VERSION ""

NS_ :

BS_:

BU_: RadarFrontCenter RadarFrontSlave DASy MPC3 RadarFrontLeft RadarFrontRight RadarRearLeft RadarRearRight
VAL_TABLE_ RFC_Obj01_DetectionStatus 4 "Reserved" 3 "Prediction target" 2 "Tracking target" 1 "New detection target" 0 "Default value" ;
VAL_TABLE_ RFC_Obj00_DetectionStatus 4 "Reserved" 3 "Prediction target" 2 "Tracking target" 1 "New detection target" 0 "Default value" ;
VAL_TABLE_ RFC_Obj02_DetectionStatus 4 "Reserved" 3 "Prediction target" 2 "Tracking target" 1 "New detection target" 0 "Default value" ;
VAL_TABLE_ RFC_Obj03_DetectionStatus 4 "Reserved" 3 "Prediction target" 2 "Tracking target" 1 "New detection target" 0 "Default value" ;
VAL_TABLE_ RFC_Obj04_DetectionStatus 4 "Reserved" 3 "Prediction target" 2 "Tracking target" 1 "New detection target" 0 "Default value" ;
VAL_TABLE_ RFC_Obj05_DetectionStatus 4 "Reserved" 3 "Prediction target" 2 "Tracking target" 1 "New detection target" 0 "Default value" ;
VAL_TABLE_ RFC_Obj06_DetectionStatus 4 "Reserved" 3 "Prediction target" 2 "Tracking target" 1 "New detection target" 0 "Default value" ;
VAL_TABLE_ RFC_Obj07_DetectionStatus 4 "Reserved" 3 "Prediction target" 2 "Tracking target" 1 "New detection target" 0 "Default value" ;
VAL_TABLE_ RFC_Obj08_DetectionStatus 4 "Reserved" 3 "Prediction target" 2 "Tracking target" 1 "New detection target" 0 "Default value" ;
VAL_TABLE_ RFC_Obj09_DetectionStatus 4 "Reserved" 3 "Prediction target" 2 "Tracking target" 1 "New detection target" 0 "Default value" ;
VAL_TABLE_ RFC_Obj10_DetectionStatus 4 "Reserved" 3 "Prediction target" 2 "Tracking target" 1 "New detection target" 0 "Default value" ;
VAL_TABLE_ RFC_Obj11_DetectionStatus 4 "Reserved" 3 "Prediction target" 2 "Tracking target" 1 "New detection target" 0 "Default value" ;
VAL_TABLE_ RFC_Obj12_DetectionStatus 4 "Reserved" 3 "Prediction target" 2 "Tracking target" 1 "New detection target" 0 "Default value" ;
VAL_TABLE_ RFC_Obj13_DetectionStatus 4 "Reserved" 3 "Prediction target" 2 "Tracking target" 1 "New detection target" 0 "Default value" ;
VAL_TABLE_ RFC_Obj14_DetectionStatus 4 "Reserved" 3 "Prediction target" 2 "Tracking target" 1 "New detection target" 0 "Default value" ;
VAL_TABLE_ RFC_Obj15_DetectionStatus 4 "Reserved" 3 "Prediction target" 2 "Tracking target" 1 "New detection target" 0 "Default value" ;
VAL_TABLE_ RFC_Obj16_DetectionStatus 4 "Reserved" 3 "Prediction target" 2 "Tracking target" 1 "New detection target" 0 "Default value" ;
VAL_TABLE_ RFC_Obj17_DetectionStatus 4 "Reserved" 3 "Prediction target" 2 "Tracking target" 1 "New detection target" 0 "Default value" ;
VAL_TABLE_ RFC_Obj18_DetectionStatus 4 "Reserved" 3 "Prediction target" 2 "Tracking target" 1 "New detection target" 0 "Default value" ;
VAL_TABLE_ RFC_Obj19_DetectionStatus 4 "Reserved" 3 "Prediction target" 2 "Tracking target" 1 "New detection target" 0 "Default value" ;
VAL_TABLE_ RFC_Obj20_DetectionStatus 4 "Reserved" 3 "Prediction target" 2 "Tracking target" 1 "New detection target" 0 "Default value" ;
VAL_TABLE_ RFC_Obj21_DetectionStatus 4 "Reserved" 3 "Prediction target" 2 "Tracking target" 1 "New detection target" 0 "Default value" ;
VAL_TABLE_ RFC_Obj22_DetectionStatus 4 "Reserved" 3 "Prediction target" 2 "Tracking target" 1 "New detection target" 0 "Default value" ;
VAL_TABLE_ RFC_Obj23_DetectionStatus 4 "Reserved" 3 "Prediction target" 2 "Tracking target" 1 "New detection target" 0 "Default value" ;
VAL_TABLE_ RFC_Obj24_DetectionStatus 4 "Reserved" 3 "Prediction target" 2 "Tracking target" 1 "New detection target" 0 "Default value" ;
VAL_TABLE_ RFC_Obj25_DetectionStatus 4 "Reserved" 3 "Prediction target" 2 "Tracking target" 1 "New detection target" 0 "Default value" ;
VAL_TABLE_ RFC_Obj26_DetectionStatus 4 "Reserved" 3 "Prediction target" 2 "Tracking target" 1 "New detection target" 0 "Default value" ;
VAL_TABLE_ RFC_Obj27_DetectionStatus 4 "Reserved" 3 "Prediction target" 2 "Tracking target" 1 "New detection target" 0 "Default value" ;
VAL_TABLE_ RFC_Obj28_DetectionStatus 4 "Reserved" 3 "Prediction target" 2 "Tracking target" 1 "New detection target" 0 "Default value" ;
VAL_TABLE_ RFC_Obj29_DetectionStatus 4 "Reserved" 3 "Prediction target" 2 "Tracking target" 1 "New detection target" 0 "Default value" ;
VAL_TABLE_ RFC_Obj30_DetectionStatus 4 "Reserved" 3 "Prediction target" 2 "Tracking target" 1 "New detection target" 0 "Default value" ;
VAL_TABLE_ RFC_Obj31_DetectionStatus 4 "Reserved" 3 "Prediction target" 2 "Tracking target" 1 "New detection target" 0 "Default value" ;

BO_ 3221225472 VECTOR__INDEPENDENT_SIG_MSG: 0 Vector__XXX
 SG_ VFC_Left_Confidence : 0|7@1+ (0.01,0) [0|1] "" Vector__XXX
 SG_ VFC_Left_DxEnd : 0|9@1+ (0.5,0) [0|255.5] "m" Vector__XXX
 SG_ VFC_Left_Dy : 0|12@1+ (0.0078125,-16) [-16|15.9921875] "m" Vector__XXX
 SG_ VFC_Left_Curv : 0|12@1+ (3.0517578125E-005,-0.0625) [-0.0625|0.062469482421875] "1/m" Vector__XXX
 SG_ VFC_Left_CurvChange : 0|12@1+ (7.62939453125E-006,-0.015625) [-0.015625|0.0156173706054688] "1/m^2" Vector__XXX
 SG_ VFC_Left_HeadingAngle : 0|12@1+ (0.00048828125,-1) [-1|0.99951171875] "rad" Vector__XXX
 SG_ VFC_Left_Type : 0|5@1+ (1,0) [0|19] "" Vector__XXX
 SG_ VFC_Left_ID : 0|8@1+ (1,0) [0|255] "" Vector__XXX
 SG_ VFC_Right_Confidence : 0|7@1+ (0.01,0) [0|1] "" Vector__XXX
 SG_ VFC_Right_DxEnd : 0|9@1+ (0.5,0) [0|255.5] "m" Vector__XXX
 SG_ VFC_Right_Dy : 0|12@1+ (0.0078125,-16) [-16|15.9921875] "m" Vector__XXX
 SG_ VFC_Right_Curv : 0|12@1+ (3.0517578125E-005,-0.0625) [-0.0625|0.062469482421875] "1/m" Vector__XXX
 SG_ VFC_Right_CurvChange : 0|12@1+ (7.62939453125E-006,-0.015625) [-0.015625|0.0156173706054688] "1/m^2" Vector__XXX
 SG_ VFC_Right_HeadingAngle : 0|12@1+ (0.00048828125,-1) [-1|0.99951171875] "rad" Vector__XXX
 SG_ VFC_Right_Type : 0|5@1+ (1,0) [0|19] "" Vector__XXX
 SG_ VFC_Right_ID : 0|8@1+ (1,0) [0|255] "" Vector__XXX
 SG_ VFC_LeftLe_Confidence : 0|7@1+ (0.01,0) [0|1] "" Vector__XXX
 SG_ VFC_LeftLe_DxEnd : 0|9@1+ (0.5,0) [0|255.5] "m" Vector__XXX
 SG_ VFC_LeftLe_Dy : 0|12@1+ (0.0078125,-16) [-16|15.9921875] "m" Vector__XXX
 SG_ VFC_LeftLe_Curv : 0|12@1+ (3.0517578125E-005,-0.0625) [-0.0625|0.062469482421875] "1/m" Vector__XXX
 SG_ VFC_LeftLe_CurvChange : 0|12@1+ (7.62939453125E-006,-0.015625) [-0.015625|0.0156173706054688] "1/m^2" Vector__XXX
 SG_ VFC_LeftLe_HeadingAngle : 0|12@1+ (0.00048828125,-1) [-1|0.99951171875] "rad" Vector__XXX
 SG_ VFC_LeftLe_Type : 0|5@1+ (1,0) [0|19] "" Vector__XXX
 SG_ VFC_LeftLe_ID : 0|8@1+ (1,0) [0|255] "" Vector__XXX
 SG_ VFC_RightRi_Confidence : 0|7@1+ (0.01,0) [0|1] "" Vector__XXX
 SG_ VFC_RightRi_DxEnd : 0|9@1+ (0.5,0) [0|255.5] "m" Vector__XXX
 SG_ VFC_RightRi_Dy : 0|12@1+ (0.0078125,-16) [-16|15.9921875] "m" Vector__XXX
 SG_ VFC_RightRi_Curv : 0|12@1+ (3.0517578125E-005,-0.0625) [-0.0625|0.062469482421875] "1/m" Vector__XXX
 SG_ VFC_RightRi_CurvChange : 0|12@1+ (7.62939453125E-006,-0.015625) [-0.015625|0.0156173706054688] "1/m^2" Vector__XXX
 SG_ VFC_RightRi_HeadingAngle : 0|12@1+ (0.00048828125,-1) [-1|0.99951171875] "rad" Vector__XXX
 SG_ VFC_RightRi_Type : 0|5@1+ (1,0) [0|19] "" Vector__XXX
 SG_ VFC_RightRi_ID : 0|8@1+ (1,0) [0|255] "" Vector__XXX
 SG_ RFC_ACC_TGU_Hdr_CRC : 0|8@1+ (1,0) [0|255] "" Vector__XXX
 SG_ RFC_ACC_TGU_Hdr_MsgCtr : 0|4@1+ (1,0) [0|15] "" Vector__XXX
 SG_ RFC_ACC_TGU_Hdr_TimeStampStatus : 0|8@1+ (1,0) [0|255] "" Vector__XXX
 SG_ RFC_ACC_TGU_Hdr_TimeStamp : 0|42@1+ (1,0) [0|4398046511103] "ms" Vector__XXX
 SG_ RFC_ACC_TGU_Hdr_SensorState : 0|4@1+ (1,0) [0|15] "" Vector__XXX
 SG_ RFC_ACCObjInfo1_CRC : 0|8@1+ (1,0) [0|255] "" Vector__XXX
 SG_ RFC_ACCObjInfo1_MsgCtr : 0|4@1+ (1,0) [0|15] "" Vector__XXX
 SG_ RFC_ACCObjInfo1_ID : 0|8@1+ (1,0) [0|255] "" Vector__XXX
 SG_ RFC_ACCObjInfo1_Dx : 0|13@1+ (0.0625,-255.9375) [-255.9375|255.9375] "m" Vector__XXX
 SG_ RFC_ACCObjInfo1_Vx : 0|11@1+ (0.125,-128) [-128|127.875] "mps" Vector__XXX
 SG_ RFC_ACCObjInfo1_Ax : 0|10@1+ (0.125,-44.5) [-44.5|44.5] "mps2" Vector__XXX
 SG_ RFC_ACCObjInfo1_Dy : 0|13@1+ (0.0625,-255.9375) [-255.9375|255.9375] "m" Vector__XXX
 SG_ RFC_ACCObjInfo1_Vy : 0|11@1+ (0.125,-128) [-128|127.875] "mps" Vector__XXX
 SG_ RFC_ACCObjInfo1_Ay : 0|10@1+ (0.125,-44.5) [-44.5|44.5] "mps2" Vector__XXX
 SG_ RFC_ACCObjInfo1_DxStd : 0|8@1+ (0.05,0) [0|12.75] "m" Vector__XXX
 SG_ RFC_ACCObjInfo1_VxStd : 0|6@1+ (0.2,0) [0|12.6] "mps" Vector__XXX
 SG_ RFC_ACCObjInfo1_AxStd : 0|5@1+ (0.35,0) [0|10.85] "mps2" Vector__XXX
 SG_ RFC_ACCObjInfo1_DyStd : 0|8@1+ (0.1,0) [0|25.5] "m" Vector__XXX
 SG_ RFC_ACCObjInfo1_VyStd : 0|6@1+ (0.2,0) [0|12.6] "mps" Vector__XXX
 SG_ RFC_ACCObjInfo1_AyStd : 0|5@1+ (0.35,0) [0|10.85] "mps2" Vector__XXX
 SG_ RFC_ACCObjInfo1_ValidFlag : 0|1@1+ (1,0) [0|1] "" Vector__XXX
 SG_ RFC_ACCObjInfo1_UpdateFlag : 0|1@1+ (1,0) [0|1] "" Vector__XXX
 SG_ RFC_ACCObjInfo1_MirProb : 0|7@1+ (1,0) [0|100] "percent" Vector__XXX
 SG_ RFC_ACCObjInfo1_ObsProb : 0|7@1+ (1,0) [0|100] "percent" Vector__XXX
 SG_ RFC_ACCObjInfo1_ExistProb : 0|7@1+ (1,0) [0|100] "percent" Vector__XXX
 SG_ RFC_ACCObjInfo1_Type : 0|4@1+ (1,0) [0|15] "" Vector__XXX
 SG_ RFC_ACCObjInfo1_EDynProp : 0|4@1+ (1,0) [0|15] "" Vector__XXX
 SG_ RFC_ACCObjInfo1_UiLifeCycles : 0|7@1+ (1,0) [0|127] "" Vector__XXX
 SG_ RFC_ACCObjInfo1_RCS : 0|11@1+ (0.1,-100) [-100|100] "dBm" Vector__XXX
 SG_ RFC_ACCObjInfo1_RFF : 0|8@1+ (1,0) [0|255] "" Vector__XXX
 SG_ RFC_ACCObjInfo1_Width : 0|16@1- (0.0078125,0) [-256|255.9921875] "" Vector__XXX
 SG_ RFC_OnGoingObj3_CRC : 0|8@1+ (1,0) [0|255] "" Vector__XXX
 SG_ RFC_OnGoingObj3_MsgCtr : 0|4@1+ (1,0) [0|15] "" Vector__XXX
 SG_ RFC_OnGoingObj3_ID : 0|8@1+ (1,0) [0|255] "" Vector__XXX
 SG_ RFC_OnGoingObj3_Dx : 0|13@1+ (0.0625,-255.9375) [-255.9375|255.9375] "m" Vector__XXX
 SG_ RFC_OnGoingObj3_Vx : 0|11@1+ (0.125,-128) [-128|127.875] "mps" Vector__XXX
 SG_ RFC_OnGoingObj3_Ax : 0|10@1+ (0.125,-44.5) [-44.5|44.5] "mps2" Vector__XXX
 SG_ RFC_OnGoingObj3_Dy : 0|13@1+ (0.0625,-255.9375) [-255.9375|255.9375] "m" Vector__XXX
 SG_ RFC_OnGoingObj3_Vy : 0|11@1+ (0.125,-128) [-128|127.875] "mps" Vector__XXX
 SG_ RFC_OnGoingObj3_Ay : 0|10@1+ (0.125,-44.5) [-44.5|44.5] "mps2" Vector__XXX
 SG_ RFC_OnGoingObj3_DxStd : 0|8@1+ (0.05,0) [0|12.75] "m" Vector__XXX
 SG_ RFC_OnGoingObj3_VxStd : 0|6@1+ (0.2,0) [0|12.6] "mps" Vector__XXX
 SG_ RFC_OnGoingObj3_AxStd : 0|5@1+ (0.35,0) [0|10.85] "mps2" Vector__XXX
 SG_ RFC_OnGoingObj3_DyStd : 0|8@1+ (0.1,0) [0|25.5] "m" Vector__XXX
 SG_ RFC_OnGoingObj3_VyStd : 0|6@1+ (0.2,0) [0|12.6] "mps" Vector__XXX
 SG_ RFC_OnGoingObj3_AyStd : 0|5@1+ (0.35,0) [0|10.85] "mps2" Vector__XXX
 SG_ RFC_OnGoingObj3_ValidFlag : 0|1@1+ (1,0) [0|1] "" Vector__XXX
 SG_ RFC_OnGoingObj3_UpdateFlag : 0|1@1+ (1,0) [0|1] "" Vector__XXX
 SG_ RFC_OnGoingObj3_MirProb : 0|7@1+ (1,0) [0|100] "percent" Vector__XXX
 SG_ RFC_OnGoingObj3_ObsProb : 0|7@1+ (1,0) [0|100] "percent" Vector__XXX
 SG_ RFC_OnGoingObj3_ExistProb : 0|7@1+ (1,0) [0|100] "percent" Vector__XXX
 SG_ RFC_OnGoingObj3_Type : 0|4@1+ (1,0) [0|15] "" Vector__XXX
 SG_ RFC_OnGoingObj3_EDynProp : 0|4@1+ (1,0) [0|15] "" Vector__XXX
 SG_ RFC_OnGoingObj3_UiLifeCycles : 0|7@1+ (1,0) [0|127] "" Vector__XXX
 SG_ RFC_OnGoingObj3_RCS : 0|11@1+ (0.1,-100) [-100|100] "dBm" Vector__XXX
 SG_ RFC_OnGoingObj3_RFF : 0|8@1+ (1,0) [0|255] "" Vector__XXX
 SG_ RFC_OnGoingObj3_Width : 0|16@1- (0.0078125,0) [-256|255.9921875] "" Vector__XXX
 SG_ RFC_OnGoingObj2_CRC : 0|8@1+ (1,0) [0|255] "" Vector__XXX
 SG_ RFC_OnGoingObj2_MsgCtr : 0|4@1+ (1,0) [0|15] "" Vector__XXX
 SG_ RFC_OnGoingObj2_ID : 0|8@1+ (1,0) [0|255] "" Vector__XXX
 SG_ RFC_OnGoingObj2_Dx : 0|13@1+ (0.0625,-255.9375) [-255.9375|255.9375] "m" Vector__XXX
 SG_ RFC_OnGoingObj2_Vx : 0|11@1+ (0.125,-128) [-128|127.875] "mps" Vector__XXX
 SG_ RFC_OnGoingObj2_Ax : 0|10@1+ (0.125,-44.5) [-44.5|44.5] "mps2" Vector__XXX
 SG_ RFC_OnGoingObj2_Dy : 0|13@1+ (0.0625,-255.9375) [-255.9375|255.9375] "m" Vector__XXX
 SG_ RFC_OnGoingObj2_Vy : 0|11@1+ (0.125,-128) [-128|127.875] "mps" Vector__XXX
 SG_ RFC_OnGoingObj2_Ay : 0|10@1+ (0.125,-44.5) [-44.5|44.5] "mps2" Vector__XXX
 SG_ RFC_OnGoingObj2_DxStd : 0|8@1+ (0.05,0) [0|12.75] "m" Vector__XXX
 SG_ RFC_OnGoingObj2_VxStd : 0|6@1+ (0.2,0) [0|12.6] "mps" Vector__XXX
 SG_ RFC_OnGoingObj2_AxStd : 0|5@1+ (0.35,0) [0|10.85] "mps2" Vector__XXX
 SG_ RFC_OnGoingObj2_DyStd : 0|8@1+ (0.1,0) [0|25.5] "m" Vector__XXX
 SG_ RFC_OnGoingObj2_VyStd : 0|6@1+ (0.2,0) [0|12.6] "mps" Vector__XXX
 SG_ RFC_OnGoingObj2_AyStd : 0|5@1+ (0.35,0) [0|10.85] "mps2" Vector__XXX
 SG_ RFC_OnGoingObj2_ValidFlag : 0|1@1+ (1,0) [0|1] "" Vector__XXX
 SG_ RFC_OnGoingObj2_UpdateFlag : 0|1@1+ (1,0) [0|1] "" Vector__XXX
 SG_ RFC_OnGoingObj2_MirProb : 0|7@1+ (1,0) [0|100] "percent" Vector__XXX
 SG_ RFC_OnGoingObj2_ObsProb : 0|7@1+ (1,0) [0|100] "percent" Vector__XXX
 SG_ RFC_OnGoingObj2_ExistProb : 0|7@1+ (1,0) [0|100] "percent" Vector__XXX
 SG_ RFC_OnGoingObj2_Type : 0|4@1+ (1,0) [0|15] "" Vector__XXX
 SG_ RFC_OnGoingObj2_EDynProp : 0|4@1+ (1,0) [0|15] "" Vector__XXX
 SG_ RFC_OnGoingObj2_UiLifeCycles : 0|7@1+ (1,0) [0|127] "" Vector__XXX
 SG_ RFC_OnGoingObj2_RCS : 0|11@1+ (0.1,-100) [-100|100] "dBm" Vector__XXX
 SG_ RFC_OnGoingObj2_RFF : 0|8@1+ (1,0) [0|255] "" Vector__XXX
 SG_ RFC_OnGoingObj2_Width : 0|16@1- (0.0078125,0) [-256|255.9921875] "" Vector__XXX
 SG_ RRR_ObjHdr_CRC : 0|16@1+ (1,0) [0|65535] "" Vector__XXX
 SG_ RRR_ObjHdr_AliveCtr : 0|8@1+ (1,0) [0|255] "" Vector__XXX
 SG_ RRR_ObjHdr_ProtBlockCtr : 0|4@1+ (1,0) [0|15] "" Vector__XXX
 SG_ RRR_ObjHdr_TimeLatency : 0|16@1+ (1,0) [0|65535] "ms" Vector__XXX
 SG_ RRR_ObjHdr_TimeStampStatus : 0|8@1+ (1,0) [0|255] "" Vector__XXX
 SG_ RRR_ObjHdr_TimeStamp : 0|26@1+ (1,0) [0|67108863] "ms" Vector__XXX
 SG_ RRL_ObjHdr_CRC : 0|16@1+ (1,0) [0|65535] "" Vector__XXX
 SG_ RRL_ObjHdr_AliveCtr : 0|8@1+ (1,0) [0|255] "" Vector__XXX
 SG_ RRL_ObjHdr_ProtBlockCtr : 0|4@1+ (1,0) [0|15] "" Vector__XXX
 SG_ RRL_ObjHdr_TimeLatency : 0|16@1+ (1,0) [0|65535] "ms" Vector__XXX
 SG_ RRL_ObjHdr_TimeStampStatus : 0|8@1+ (1,0) [0|255] "" Vector__XXX
 SG_ RRL_ObjHdr_TimeStamp : 0|26@1+ (1,0) [0|67108863] "ms" Vector__XXX
 SG_ RFR_ObjHdr_CRC : 0|16@1+ (1,0) [0|65535] "" Vector__XXX
 SG_ RFR_ObjHdr_AliveCtr : 0|8@1+ (1,0) [0|255] "" Vector__XXX
 SG_ RFR_ObjHdr_ProtBlockCtr : 0|4@1+ (1,0) [0|15] "" Vector__XXX
 SG_ RFR_ObjHdr_TimeLatency : 0|16@1+ (1,0) [0|65535] "ms" Vector__XXX
 SG_ RFR_ObjHdr_TimeStampStatus : 0|8@1+ (1,0) [0|255] "" Vector__XXX
 SG_ RFR_ObjHdr_TimeStamp : 0|26@1+ (1,0) [0|67108863] "ms" Vector__XXX
 SG_ RFL_ObjHdr_CRC : 0|16@1+ (1,0) [0|65535] "" Vector__XXX
 SG_ RFL_ObjHdr_AliveCtr : 0|8@1+ (1,0) [0|255] "" Vector__XXX
 SG_ RFL_ObjHdr_ProtBlockCtr : 0|4@1+ (1,0) [0|15] "" Vector__XXX
 SG_ RFL_ObjHdr_TimeLatency : 0|16@1+ (1,0) [0|65535] "ms" Vector__XXX
 SG_ RFL_ObjHdr_TimeStampStatus : 0|8@1+ (1,0) [0|255] "" Vector__XXX
 SG_ RFL_ObjHdr_TimeStamp : 0|26@1+ (1,0) [0|67108863] "ms" Vector__XXX
 SG_ VFC_SafeSearch_ALC_CRC : 0|8@1+ (1,0) [0|255] "" Vector__XXX
 SG_ VFC_SafeSearch_ALC_MsgCtr : 0|4@1+ (1,0) [0|15] "" Vector__XXX
 SG_ VFC_ALCSt : 0|3@1+ (1,0) [0|7] "" Vector__XXX
 SG_ VFC_LaneChangeDirection : 0|2@1+ (1,0) [0|3] "" Vector__XXX
 SG_ VFC_SafeSearchCondition : 0|1@1+ (1,0) [0|1] "" Vector__XXX
 SG_ VFC_JumpTargetLane : 0|1@1+ (1,0) [0|1] "" Vector__XXX
 SG_ RFC_Evaluator_ALC_CRC : 0|8@1+ (1,0) [0|255] "" Vector__XXX
 SG_ RFC_Evaluator_ALC_MsgCtr : 0|4@1+ (1,0) [0|15] "" Vector__XXX
 SG_ LaneChangeLeft_collision_prob : 0|7@1+ (0.01,0) [0|1] "" Vector__XXX
 SG_ LaneChangeLeft_recommendation : 0|1@1+ (1,0) [0|1] "" Vector__XXX
 SG_ LaneChangeRight_collision_prob : 0|7@1+ (0.01,0) [0|1] "" Vector__XXX
 SG_ LaneChangeRight_recommendation : 0|1@1+ (1,0) [0|1] "" Vector__XXX
 SG_ CRObj_LeftObjLostAtCloseRange : 0|1@1+ (1,0) [0|1] "" Vector__XXX
 SG_ CRObj_RightObjLostAtCloseRange : 0|1@1+ (1,0) [0|1] "" Vector__XXX
 SG_ CRObj_evaluator_axd_valid : 0|1@1+ (1,0) [0|1] "" Vector__XXX
 SG_ CRObj_evaluator_axc_valid : 0|1@1+ (1,0) [0|1] "" Vector__XXX
 SG_ FLObj_evaluator_feasibility : 0|7@1+ (0.01,0) [0|1] "" Vector__XXX
 SG_ FRObj_evaluator_feasibility : 0|7@1+ (0.01,0) [0|1] "" Vector__XXX
 SG_ RLObj_evaluator_feasibility : 0|7@1+ (0.01,0) [0|1] "" Vector__XXX
 SG_ RRObj_evaluator_feasibility : 0|7@1+ (0.01,0) [0|1] "" Vector__XXX
 SG_ RFC_ALC_CR_invalid : 0|1@1+ (1,0) [0|1] "" Vector__XXX
 SG_ RFL_Status_CRC : 0|8@1+ (1,0) [0|255] "" Vector__XXX
 SG_ RFL_Status_MsgCtr : 0|4@1+ (1,0) [0|15] "" Vector__XXX
 SG_ RFL_Modulation_Status : 0|2@1+ (1,0) [0|3] "" Vector__XXX
 SG_ RFL_Status_SensorState : 0|4@1+ (1,0) [0|15] "" Vector__XXX
 SG_ RFR_Status_CRC : 0|8@1+ (1,0) [0|255] "" Vector__XXX
 SG_ RFR_Status_MsgCtr : 0|4@1+ (1,0) [0|15] "" Vector__XXX
 SG_ RFR_Modulation_Status : 0|2@1+ (1,0) [0|3] "" Vector__XXX
 SG_ RFR_Status_SensorState : 0|4@1+ (1,0) [0|15] "" Vector__XXX
 SG_ RRL_Status_CRC : 0|8@1+ (1,0) [0|255] "" Vector__XXX
 SG_ RRL_Status_MsgCtr : 0|4@1+ (1,0) [0|15] "" Vector__XXX
 SG_ RRL_Status_SensorState : 0|4@1+ (1,0) [0|15] "" Vector__XXX
 SG_ RRL_Modulation_Status : 0|2@1+ (1,0) [0|3] "" Vector__XXX
 SG_ RRR_Status_CRC : 0|8@1+ (1,0) [0|255] "" Vector__XXX
 SG_ RRR_Status_MsgCtr : 0|4@1+ (1,0) [0|15] "" Vector__XXX
 SG_ RRR_Status_SensorState : 0|4@1+ (1,0) [0|15] "" Vector__XXX
 SG_ RRR_Modulation_Status : 0|2@1+ (1,0) [0|3] "" Vector__XXX
 SG_ RFL_Obj00_01_CRC : 0|16@1+ (1,0) [0|65535] "" Vector__XXX
 SG_ RFL_Obj00_01_AliveCtr : 0|8@1+ (1,0) [0|255] "" Vector__XXX
 SG_ RFL_Obj00_01_ProtBlockCtr : 0|4@1+ (1,0) [0|15] "" Vector__XXX
 SG_ RFL_Obj00_RefPosIndex : 0|4@1+ (1,0) [0|15] "" Vector__XXX
 SG_ RFL_Obj00_Dx : 0|13@1+ (0.0625,-256) [-256|255.9375] "m" Vector__XXX
 SG_ RFL_Obj00_Dy : 0|11@1+ (0.125,-128) [-128|127.875] "m" Vector__XXX
 SG_ RFL_Obj00_DxVnce : 0|12@1+ (0.01,0) [0|30] "m^2" Vector__XXX
 SG_ RFL_Obj00_DyVnce : 0|12@1+ (0.01,0) [0|30] "m^2" Vector__XXX
 SG_ RFL_Obj00_Vx : 0|12@1+ (0.0625,-128) [-128|127.9375] "m/s" Vector__XXX
 SG_ RFL_Obj00_WidthVnce : 0|12@1+ (0.01,0) [0|30] "m^2" Vector__XXX
 SG_ RFL_Obj00_Width : 0|7@1+ (0.125,0) [0|15.875] "m" Vector__XXX
 SG_ RFL_Obj00_Valid : 0|1@1+ (1,0) [0|1] "" Vector__XXX
 SG_ RFL_Obj00_ID : 0|7@1+ (1,0) [0|127] "" Vector__XXX
 SG_ RFL_Obj00_Length : 0|7@1+ (0.125,0) [0|15.875] "m" Vector__XXX
 SG_ RFL_Obj00_MovingObserved : 0|6@1+ (2,0) [0|100] "%" Vector__XXX
 SG_ RFL_Obj00_MovingProbability : 0|6@1+ (2,0) [0|100] "%" Vector__XXX
 SG_ RFL_Obj01_RefPosIndex : 0|4@1+ (1,0) [0|15] "" Vector__XXX
 SG_ RFL_Obj01_Dx : 0|13@1+ (0.0625,-256) [-256|255.9375] "m" Vector__XXX
 SG_ RFL_Obj01_Dy : 0|11@1+ (0.125,-128) [-128|127.875] "m" Vector__XXX
 SG_ RFL_Obj01_DxVnce : 0|12@1+ (0.01,0) [0|30] "m^2" Vector__XXX
 SG_ RFL_Obj01_DyVnce : 0|12@1+ (0.01,0) [0|30] "m^2" Vector__XXX
 SG_ RFL_Obj01_Vx : 0|12@1+ (0.0625,-128) [-128|127.9375] "m/s" Vector__XXX
 SG_ RFL_Obj01_WidthVnce : 0|12@1+ (0.01,0) [0|30] "m^2" Vector__XXX
 SG_ RFL_Obj01_Width : 0|7@1+ (0.125,0) [0|15.875] "m" Vector__XXX
 SG_ RFL_Obj01_Valid : 0|1@1+ (1,0) [0|1] "" Vector__XXX
 SG_ RFL_Obj01_ID : 0|7@1+ (1,0) [0|127] "" Vector__XXX
 SG_ RFL_Obj01_Length : 0|7@1+ (0.125,0) [0|15.875] "m" Vector__XXX
 SG_ RFL_Obj01_MovingObserved : 0|6@1+ (2,0) [0|100] "%" Vector__XXX
 SG_ RFL_Obj01_MovingProbability : 0|6@1+ (2,0) [0|100] "%" Vector__XXX
 SG_ RFL_Obj02_03_CRC : 0|16@1+ (1,0) [0|65535] "" Vector__XXX
 SG_ RFL_Obj02_03_AliveCtr : 0|8@1+ (1,0) [0|255] "" Vector__XXX
 SG_ RFL_Obj02_03_ProtBlockCtr : 0|4@1+ (1,0) [0|15] "" Vector__XXX
 SG_ RFL_Obj02_RefPosIndex : 0|4@1+ (1,0) [0|15] "" Vector__XXX
 SG_ RFL_Obj02_Dx : 0|13@1+ (0.0625,-256) [-256|255.9375] "m" Vector__XXX
 SG_ RFL_Obj02_Dy : 0|11@1+ (0.125,-128) [-128|127.875] "m" Vector__XXX
 SG_ RFL_Obj02_DxVnce : 0|12@1+ (0.01,0) [0|30] "m^2" Vector__XXX
 SG_ RFL_Obj02_DyVnce : 0|12@1+ (0.01,0) [0|30] "m^2" Vector__XXX
 SG_ RFL_Obj02_Vx : 0|12@1+ (0.0625,-128) [-128|127.9375] "m/s" Vector__XXX
 SG_ RFL_Obj02_WidthVnce : 0|12@1+ (0.01,0) [0|30] "m^2" Vector__XXX
 SG_ RFL_Obj02_Width : 0|7@1+ (0.125,0) [0|15.875] "m" Vector__XXX
 SG_ RFL_Obj02_Valid : 0|1@1+ (1,0) [0|1] "" Vector__XXX
 SG_ RFL_Obj02_ID : 0|7@1+ (1,0) [0|127] "" Vector__XXX
 SG_ RFL_Obj02_Length : 0|7@1+ (0.125,0) [0|15.875] "m" Vector__XXX
 SG_ RFL_Obj02_MovingObserved : 0|6@1+ (2,0) [0|100] "%" Vector__XXX
 SG_ RFL_Obj02_MovingProbability : 0|6@1+ (2,0) [0|100] "%" Vector__XXX
 SG_ RFL_Obj03_RefPosIndex : 0|4@1+ (1,0) [0|15] "" Vector__XXX
 SG_ RFL_Obj03_Dx : 0|13@1+ (0.0625,-256) [-256|255.9375] "m" Vector__XXX
 SG_ RFL_Obj03_Dy : 0|11@1+ (0.125,-128) [-128|127.875] "m" Vector__XXX
 SG_ RFL_Obj03_DxVnce : 0|12@1+ (0.01,0) [0|30] "m^2" Vector__XXX
 SG_ RFL_Obj03_DyVnce : 0|12@1+ (0.01,0) [0|30] "m^2" Vector__XXX
 SG_ RFL_Obj03_Vx : 0|12@1+ (0.0625,-128) [-128|127.9375] "m/s" Vector__XXX
 SG_ RFL_Obj03_WidthVnce : 0|12@1+ (0.01,0) [0|30] "m^2" Vector__XXX
 SG_ RFL_Obj03_Width : 0|7@1+ (0.125,0) [0|15.875] "m" Vector__XXX
 SG_ RFL_Obj03_Valid : 0|1@1+ (1,0) [0|1] "" Vector__XXX
 SG_ RFL_Obj03_ID : 0|7@1+ (1,0) [0|127] "" Vector__XXX
 SG_ RFL_Obj03_Length : 0|7@1+ (0.125,0) [0|15.875] "m" Vector__XXX
 SG_ RFL_Obj03_MovingObserved : 0|6@1+ (2,0) [0|100] "%" Vector__XXX
 SG_ RFL_Obj03_MovingProbability : 0|6@1+ (2,0) [0|100] "%" Vector__XXX
 SG_ RFL_Obj04_05_CRC : 0|16@1+ (1,0) [0|65535] "" Vector__XXX
 SG_ RFL_Obj04_05_AliveCtr : 0|8@1+ (1,0) [0|255] "" Vector__XXX
 SG_ RFL_Obj04_05_ProtBlockCtr : 0|4@1+ (1,0) [0|15] "" Vector__XXX
 SG_ RFL_Obj04_RefPosIndex : 0|4@1+ (1,0) [0|15] "" Vector__XXX
 SG_ RFL_Obj04_Dx : 0|13@1+ (0.0625,-256) [-256|255.9375] "m" Vector__XXX
 SG_ RFL_Obj04_Dy : 0|11@1+ (0.125,-128) [-128|127.875] "m" Vector__XXX
 SG_ RFL_Obj04_DxVnce : 0|12@1+ (0.01,0) [0|30] "m^2" Vector__XXX
 SG_ RFL_Obj04_DyVnce : 0|12@1+ (0.01,0) [0|30] "m^2" Vector__XXX
 SG_ RFL_Obj04_Vx : 0|12@1+ (0.0625,-128) [-128|127.9375] "m/s" Vector__XXX
 SG_ RFL_Obj04_WidthVnce : 0|12@1+ (0.01,0) [0|30] "m^2" Vector__XXX
 SG_ RFL_Obj04_Width : 0|7@1+ (0.125,0) [0|15.875] "m" Vector__XXX
 SG_ RFL_Obj04_Valid : 0|1@1+ (1,0) [0|1] "" Vector__XXX
 SG_ RFL_Obj04_ID : 0|7@1+ (1,0) [0|127] "" Vector__XXX
 SG_ RFL_Obj04_Length : 0|7@1+ (0.125,0) [0|15.875] "m" Vector__XXX
 SG_ RFL_Obj04_MovingObserved : 0|6@1+ (2,0) [0|100] "%" Vector__XXX
 SG_ RFL_Obj04_MovingProbability : 0|6@1+ (2,0) [0|100] "%" Vector__XXX
 SG_ RFL_Obj05_RefPosIndex : 0|4@1+ (1,0) [0|15] "" Vector__XXX
 SG_ RFL_Obj05_Dx : 0|13@1+ (0.0625,-256) [-256|255.9375] "m" Vector__XXX
 SG_ RFL_Obj05_Dy : 0|11@1+ (0.125,-128) [-128|127.875] "m" Vector__XXX
 SG_ RFL_Obj05_DxVnce : 0|12@1+ (0.01,0) [0|30] "m^2" Vector__XXX
 SG_ RFL_Obj05_DyVnce : 0|12@1+ (0.01,0) [0|30] "m^2" Vector__XXX
 SG_ RFL_Obj05_Vx : 0|12@1+ (0.0625,-128) [-128|127.9375] "m/s" Vector__XXX
 SG_ RFL_Obj05_WidthVnce : 0|12@1+ (0.01,0) [0|30] "m^2" Vector__XXX
 SG_ RFL_Obj05_Width : 0|7@1+ (0.125,0) [0|15.875] "m" Vector__XXX
 SG_ RFL_Obj05_Valid : 0|1@1+ (1,0) [0|1] "" Vector__XXX
 SG_ RFL_Obj05_ID : 0|7@1+ (1,0) [0|127] "" Vector__XXX
 SG_ RFL_Obj05_Length : 0|7@1+ (0.125,0) [0|15.875] "m" Vector__XXX
 SG_ RFL_Obj05_MovingObserved : 0|6@1+ (2,0) [0|100] "%" Vector__XXX
 SG_ RFL_Obj05_MovingProbability : 0|6@1+ (2,0) [0|100] "%" Vector__XXX
 SG_ RFR_Obj00_01_CRC : 0|16@1+ (1,0) [0|65535] "" Vector__XXX
 SG_ RFR_Obj00_01_AliveCtr : 0|8@1+ (1,0) [0|255] "" Vector__XXX
 SG_ RFR_Obj00_01_ProtBlockCtr : 0|4@1+ (1,0) [0|15] "" Vector__XXX
 SG_ RFR_Obj00_RefPosIndex : 0|4@1+ (1,0) [0|15] "" Vector__XXX
 SG_ RFR_Obj00_Dx : 0|13@1+ (0.0625,-256) [-256|255.9375] "m" Vector__XXX
 SG_ RFR_Obj00_Dy : 0|11@1+ (0.125,-128) [-128|127.875] "m" Vector__XXX
 SG_ RFR_Obj00_DxVnce : 0|12@1+ (0.01,0) [0|30] "m^2" Vector__XXX
 SG_ RFR_Obj00_DyVnce : 0|12@1+ (0.01,0) [0|30] "m^2" Vector__XXX
 SG_ RFR_Obj00_Vx : 0|12@1+ (0.0625,-128) [-128|127.9375] "m/s" Vector__XXX
 SG_ RFR_Obj00_WidthVnce : 0|12@1+ (0.01,0) [0|30] "m^2" Vector__XXX
 SG_ RFR_Obj00_Width : 0|7@1+ (0.125,0) [0|15.875] "m" Vector__XXX
 SG_ RFR_Obj00_Valid : 0|1@1+ (1,0) [0|1] "" Vector__XXX
 SG_ RFR_Obj00_ID : 0|7@1+ (1,0) [0|127] "" Vector__XXX
 SG_ RFR_Obj00_Length : 0|7@1+ (0.125,0) [0|15.875] "m" Vector__XXX
 SG_ RFR_Obj00_MovingObserved : 0|6@1+ (2,0) [0|100] "%" Vector__XXX
 SG_ RFR_Obj00_MovingProbability : 0|6@1+ (2,0) [0|100] "%" Vector__XXX
 SG_ RFR_Obj01_RefPosIndex : 0|4@1+ (1,0) [0|15] "" Vector__XXX
 SG_ RFR_Obj01_Dx : 0|13@1+ (0.0625,-256) [-256|255.9375] "m" Vector__XXX
 SG_ RFR_Obj01_Dy : 0|11@1+ (0.125,-128) [-128|127.875] "m" Vector__XXX
 SG_ RFR_Obj01_DxVnce : 0|12@1+ (0.01,0) [0|30] "m^2" Vector__XXX
 SG_ RFR_Obj01_DyVnce : 0|12@1+ (0.01,0) [0|30] "m^2" Vector__XXX
 SG_ RFR_Obj01_Vx : 0|12@1+ (0.0625,-128) [-128|127.9375] "m/s" Vector__XXX
 SG_ RFR_Obj01_WidthVnce : 0|12@1+ (0.01,0) [0|30] "m^2" Vector__XXX
 SG_ RFR_Obj01_Width : 0|7@1+ (0.125,0) [0|15.875] "m" Vector__XXX
 SG_ RFR_Obj01_Valid : 0|1@1+ (1,0) [0|1] "" Vector__XXX
 SG_ RFR_Obj01_ID : 0|7@1+ (1,0) [0|127] "" Vector__XXX
 SG_ RFR_Obj01_Length : 0|7@1+ (0.125,0) [0|15.875] "m" Vector__XXX
 SG_ RFR_Obj01_MovingObserved : 0|6@1+ (2,0) [0|100] "%" Vector__XXX
 SG_ RFR_Obj01_MovingProbability : 0|6@1+ (2,0) [0|100] "%" Vector__XXX
 SG_ RFR_Obj02_03_CRC : 0|16@1+ (1,0) [0|65535] "" Vector__XXX
 SG_ RFR_Obj02_03_AliveCtr : 0|8@1+ (1,0) [0|255] "" Vector__XXX
 SG_ RFR_Obj02_03_ProtBlockCtr : 0|4@1+ (1,0) [0|15] "" Vector__XXX
 SG_ RFR_Obj02_RefPosIndex : 0|4@1+ (1,0) [0|15] "" Vector__XXX
 SG_ RFR_Obj02_Dx : 0|13@1+ (0.0625,-256) [-256|255.9375] "m" Vector__XXX
 SG_ RFR_Obj02_Dy : 0|11@1+ (0.125,-128) [-128|127.875] "m" Vector__XXX
 SG_ RFR_Obj02_DxVnce : 0|12@1+ (0.01,0) [0|30] "m^2" Vector__XXX
 SG_ RFR_Obj02_DyVnce : 0|12@1+ (0.01,0) [0|30] "m^2" Vector__XXX
 SG_ RFR_Obj02_Vx : 0|12@1+ (0.0625,-128) [-128|127.9375] "m/s" Vector__XXX
 SG_ RFR_Obj02_WidthVnce : 0|12@1+ (0.01,0) [0|30] "m^2" Vector__XXX
 SG_ RFR_Obj02_Width : 0|7@1+ (0.125,0) [0|15.875] "m" Vector__XXX
 SG_ RFR_Obj02_Valid : 0|1@1+ (1,0) [0|1] "" Vector__XXX
 SG_ RFR_Obj02_ID : 0|7@1+ (1,0) [0|127] "" Vector__XXX
 SG_ RFR_Obj02_Length : 0|7@1+ (0.125,0) [0|15.875] "m" Vector__XXX
 SG_ RFR_Obj02_MovingObserved : 0|6@1+ (2,0) [0|100] "%" Vector__XXX
 SG_ RFR_Obj02_MovingProbability : 0|6@1+ (2,0) [0|100] "%" Vector__XXX
 SG_ RFR_Obj03_RefPosIndex : 0|4@1+ (1,0) [0|15] "" Vector__XXX
 SG_ RFR_Obj03_Dx : 0|13@1+ (0.0625,-256) [-256|255.9375] "m" Vector__XXX
 SG_ RFR_Obj03_Dy : 0|11@1+ (0.125,-128) [-128|127.875] "m" Vector__XXX
 SG_ RFR_Obj03_DxVnce : 0|12@1+ (0.01,0) [0|30] "m^2" Vector__XXX
 SG_ RFR_Obj03_DyVnce : 0|12@1+ (0.01,0) [0|30] "m^2" Vector__XXX
 SG_ RFR_Obj03_Vx : 0|12@1+ (0.0625,-128) [-128|127.9375] "m/s" Vector__XXX
 SG_ RFR_Obj03_WidthVnce : 0|12@1+ (0.01,0) [0|30] "m^2" Vector__XXX
 SG_ RFR_Obj03_Width : 0|7@1+ (0.125,0) [0|15.875] "m" Vector__XXX
 SG_ RFR_Obj03_Valid : 0|1@1+ (1,0) [0|1] "" Vector__XXX
 SG_ RFR_Obj03_ID : 0|7@1+ (1,0) [0|127] "" Vector__XXX
 SG_ RFR_Obj03_Length : 0|7@1+ (0.125,0) [0|15.875] "m" Vector__XXX
 SG_ RFR_Obj03_MovingObserved : 0|6@1+ (2,0) [0|100] "%" Vector__XXX
 SG_ RFR_Obj03_MovingProbability : 0|6@1+ (2,0) [0|100] "%" Vector__XXX
 SG_ RFR_Obj04_05_CRC : 0|16@1+ (1,0) [0|65535] "" Vector__XXX
 SG_ RFR_Obj04_05_AliveCtr : 0|8@1+ (1,0) [0|255] "" Vector__XXX
 SG_ RFR_Obj04_05_ProtBlockCtr : 0|4@1+ (1,0) [0|15] "" Vector__XXX
 SG_ RFR_Obj04_RefPosIndex : 0|4@1+ (1,0) [0|15] "" Vector__XXX
 SG_ RFR_Obj04_Dx : 0|13@1+ (0.0625,-256) [-256|255.9375] "m" Vector__XXX
 SG_ RFR_Obj04_Dy : 0|11@1+ (0.125,-128) [-128|127.875] "m" Vector__XXX
 SG_ RFR_Obj04_DxVnce : 0|12@1+ (0.01,0) [0|30] "m^2" Vector__XXX
 SG_ RFR_Obj04_DyVnce : 0|12@1+ (0.01,0) [0|30] "m^2" Vector__XXX
 SG_ RFR_Obj04_Vx : 0|12@1+ (0.0625,-128) [-128|127.9375] "m/s" Vector__XXX
 SG_ RFR_Obj04_WidthVnce : 0|12@1+ (0.01,0) [0|30] "m^2" Vector__XXX
 SG_ RFR_Obj04_Width : 0|7@1+ (0.125,0) [0|15.875] "m" Vector__XXX
 SG_ RFR_Obj04_Valid : 0|1@1+ (1,0) [0|1] "" Vector__XXX
 SG_ RFR_Obj04_ID : 0|7@1+ (1,0) [0|127] "" Vector__XXX
 SG_ RFR_Obj04_Length : 0|7@1+ (0.125,0) [0|15.875] "m" Vector__XXX
 SG_ RFR_Obj04_MovingObserved : 0|6@1+ (2,0) [0|100] "%" Vector__XXX
 SG_ RFR_Obj04_MovingProbability : 0|6@1+ (2,0) [0|100] "%" Vector__XXX
 SG_ RFR_Obj05_RefPosIndex : 0|4@1+ (1,0) [0|15] "" Vector__XXX
 SG_ RFR_Obj05_Dx : 0|13@1+ (0.0625,-256) [-256|255.9375] "m" Vector__XXX
 SG_ RFR_Obj05_Dy : 0|11@1+ (0.125,-128) [-128|127.875] "m" Vector__XXX
 SG_ RFR_Obj05_DxVnce : 0|12@1+ (0.01,0) [0|30] "m^2" Vector__XXX
 SG_ RFR_Obj05_DyVnce : 0|12@1+ (0.01,0) [0|30] "m^2" Vector__XXX
 SG_ RFR_Obj05_Vx : 0|12@1+ (0.0625,-128) [-128|127.9375] "m/s" Vector__XXX
 SG_ RFR_Obj05_WidthVnce : 0|12@1+ (0.01,0) [0|30] "m^2" Vector__XXX
 SG_ RFR_Obj05_Width : 0|7@1+ (0.125,0) [0|15.875] "m" Vector__XXX
 SG_ RFR_Obj05_Valid : 0|1@1+ (1,0) [0|1] "" Vector__XXX
 SG_ RFR_Obj05_ID : 0|7@1+ (1,0) [0|127] "" Vector__XXX
 SG_ RFR_Obj05_Length : 0|7@1+ (0.125,0) [0|15.875] "m" Vector__XXX
 SG_ RFR_Obj05_MovingObserved : 0|6@1+ (2,0) [0|100] "%" Vector__XXX
 SG_ RFR_Obj05_MovingProbability : 0|6@1+ (2,0) [0|100] "%" Vector__XXX
 SG_ RRL_Obj00_01_CRC : 0|16@1+ (1,0) [0|65535] "" Vector__XXX
 SG_ RRL_Obj00_01_AliveCtr : 0|8@1+ (1,0) [0|255] "" Vector__XXX
 SG_ RRL_Obj00_01_ProtBlockCtr : 0|4@1+ (1,0) [0|15] "" Vector__XXX
 SG_ RRL_Obj00_RefPosIndex : 0|4@1+ (1,0) [0|15] "" Vector__XXX
 SG_ RRL_Obj00_Dx : 0|13@1+ (0.0625,-256) [-256|255.9375] "m" Vector__XXX
 SG_ RRL_Obj00_Dy : 0|11@1+ (0.125,-128) [-128|127.875] "m" Vector__XXX
 SG_ RRL_Obj00_DxVnce : 0|12@1+ (0.01,0) [0|30] "m^2" Vector__XXX
 SG_ RRL_Obj00_DyVnce : 0|12@1+ (0.01,0) [0|30] "m^2" Vector__XXX
 SG_ RRL_Obj00_Vx : 0|12@1+ (0.0625,-128) [-128|127.9375] "m/s" Vector__XXX
 SG_ RRL_Obj00_WidthVnce : 0|12@1+ (0.01,0) [0|30] "m^2" Vector__XXX
 SG_ RRL_Obj00_Width : 0|7@1+ (0.125,0) [0|15.875] "m" Vector__XXX
 SG_ RRL_Obj00_Valid : 0|1@1+ (1,0) [0|1] "" Vector__XXX
 SG_ RRL_Obj00_ID : 0|7@1+ (1,0) [0|127] "" Vector__XXX
 SG_ RRL_Obj00_Length : 0|7@1+ (0.125,0) [0|15.875] "m" Vector__XXX
 SG_ RRL_Obj00_MovingObserved : 0|6@1+ (2,0) [0|100] "%" Vector__XXX
 SG_ RRL_Obj00_MovingProbability : 0|6@1+ (2,0) [0|100] "%" Vector__XXX
 SG_ RRL_Obj01_RefPosIndex : 0|4@1+ (1,0) [0|15] "" Vector__XXX
 SG_ RRL_Obj01_Dx : 0|13@1+ (0.0625,-256) [-256|255.9375] "m" Vector__XXX
 SG_ RRL_Obj01_Dy : 0|11@1+ (0.125,-128) [-128|127.875] "m" Vector__XXX
 SG_ RRL_Obj01_DxVnce : 0|12@1+ (0.01,0) [0|30] "m^2" Vector__XXX
 SG_ RRL_Obj01_DyVnce : 0|12@1+ (0.01,0) [0|30] "m^2" Vector__XXX
 SG_ RRL_Obj01_Vx : 0|12@1+ (0.0625,-128) [-128|127.9375] "m/s" Vector__XXX
 SG_ RRL_Obj01_WidthVnce : 0|12@1+ (0.01,0) [0|30] "m^2" Vector__XXX
 SG_ RRL_Obj01_Width : 0|7@1+ (0.125,0) [0|15.875] "m" Vector__XXX
 SG_ RRL_Obj01_Valid : 0|1@1+ (1,0) [0|1] "" Vector__XXX
 SG_ RRL_Obj01_ID : 0|7@1+ (1,0) [0|127] "" Vector__XXX
 SG_ RRL_Obj01_Length : 0|7@1+ (0.125,0) [0|15.875] "m" Vector__XXX
 SG_ RRL_Obj01_MovingObserved : 0|6@1+ (2,0) [0|100] "%" Vector__XXX
 SG_ RRL_Obj01_MovingProbability : 0|6@1+ (2,0) [0|100] "%" Vector__XXX
 SG_ RRL_Obj02_03_CRC : 0|16@1+ (1,0) [0|65535] "" Vector__XXX
 SG_ RRL_Obj02_03_AliveCtr : 0|8@1+ (1,0) [0|255] "" Vector__XXX
 SG_ RRL_Obj02_03_ProtBlockCtr : 0|4@1+ (1,0) [0|15] "" Vector__XXX
 SG_ RRL_Obj02_RefPosIndex : 0|4@1+ (1,0) [0|15] "" Vector__XXX
 SG_ RRL_Obj02_Dx : 0|13@1+ (0.0625,-256) [-256|255.9375] "m" Vector__XXX
 SG_ RRL_Obj02_Dy : 0|11@1+ (0.125,-128) [-128|127.875] "m" Vector__XXX
 SG_ RRL_Obj02_DxVnce : 0|12@1+ (0.01,0) [0|30] "m^2" Vector__XXX
 SG_ RRL_Obj02_DyVnce : 0|12@1+ (0.01,0) [0|30] "m^2" Vector__XXX
 SG_ RRL_Obj02_Vx : 0|12@1+ (0.0625,-128) [-128|127.9375] "m/s" Vector__XXX
 SG_ RRL_Obj02_WidthVnce : 0|12@1+ (0.01,0) [0|30] "m^2" Vector__XXX
 SG_ RRL_Obj02_Width : 0|7@1+ (0.125,0) [0|15.875] "m" Vector__XXX
 SG_ RRL_Obj02_Valid : 0|1@1+ (1,0) [0|1] "" Vector__XXX
 SG_ RRL_Obj02_ID : 0|7@1+ (1,0) [0|127] "" Vector__XXX
 SG_ RRL_Obj02_Length : 0|7@1+ (0.125,0) [0|15.875] "m" Vector__XXX
 SG_ RRL_Obj02_MovingObserved : 0|6@1+ (2,0) [0|100] "%" Vector__XXX
 SG_ RRL_Obj02_MovingProbability : 0|6@1+ (2,0) [0|100] "%" Vector__XXX
 SG_ RRL_Obj03_RefPosIndex : 0|4@1+ (1,0) [0|15] "" Vector__XXX
 SG_ RRL_Obj03_Dx : 0|13@1+ (0.0625,-256) [-256|255.9375] "m" Vector__XXX
 SG_ RRL_Obj03_Dy : 0|11@1+ (0.125,-128) [-128|127.875] "m" Vector__XXX
 SG_ RRL_Obj03_DxVnce : 0|12@1+ (0.01,0) [0|30] "m^2" Vector__XXX
 SG_ RRL_Obj03_DyVnce : 0|12@1+ (0.01,0) [0|30] "m^2" Vector__XXX
 SG_ RRL_Obj03_Vx : 0|12@1+ (0.0625,-128) [-128|127.9375] "m/s" Vector__XXX
 SG_ RRL_Obj03_WidthVnce : 0|12@1+ (0.01,0) [0|30] "m^2" Vector__XXX
 SG_ RRL_Obj03_Width : 0|7@1+ (0.125,0) [0|15.875] "m" Vector__XXX
 SG_ RRL_Obj03_Valid : 0|1@1+ (1,0) [0|1] "" Vector__XXX
 SG_ RRL_Obj03_ID : 0|7@1+ (1,0) [0|127] "" Vector__XXX
 SG_ RRL_Obj03_Length : 0|7@1+ (0.125,0) [0|15.875] "m" Vector__XXX
 SG_ RRL_Obj03_MovingObserved : 0|6@1+ (2,0) [0|100] "%" Vector__XXX
 SG_ RRL_Obj03_MovingProbability : 0|6@1+ (2,0) [0|100] "%" Vector__XXX
 SG_ RRL_Obj04_05_CRC : 0|16@1+ (1,0) [0|65535] "" Vector__XXX
 SG_ RRL_Obj04_05_AliveCtr : 0|8@1+ (1,0) [0|255] "" Vector__XXX
 SG_ RRL_Obj04_05_ProtBlockCtr : 0|4@1+ (1,0) [0|15] "" Vector__XXX
 SG_ RRL_Obj04_RefPosIndex : 0|4@1+ (1,0) [0|15] "" Vector__XXX
 SG_ RRL_Obj04_Dx : 0|13@1+ (0.0625,-256) [-256|255.9375] "m" Vector__XXX
 SG_ RRL_Obj04_Dy : 0|11@1+ (0.125,-128) [-128|127.875] "m" Vector__XXX
 SG_ RRL_Obj04_DxVnce : 0|12@1+ (0.01,0) [0|30] "m^2" Vector__XXX
 SG_ RRL_Obj04_DyVnce : 0|12@1+ (0.01,0) [0|30] "m^2" Vector__XXX
 SG_ RRL_Obj04_Vx : 0|12@1+ (0.0625,-128) [-128|127.9375] "m/s" Vector__XXX
 SG_ RRL_Obj04_WidthVnce : 0|12@1+ (0.01,0) [0|30] "m^2" Vector__XXX
 SG_ RRL_Obj04_Width : 0|7@1+ (0.125,0) [0|15.875] "m" Vector__XXX
 SG_ RRL_Obj04_Valid : 0|1@1+ (1,0) [0|1] "" Vector__XXX
 SG_ RRL_Obj04_ID : 0|7@1+ (1,0) [0|127] "" Vector__XXX
 SG_ RRL_Obj04_Length : 0|7@1+ (0.125,0) [0|15.875] "m" Vector__XXX
 SG_ RRL_Obj04_MovingObserved : 0|6@1+ (2,0) [0|100] "%" Vector__XXX
 SG_ RRL_Obj04_MovingProbability : 0|6@1+ (2,0) [0|100] "%" Vector__XXX
 SG_ RRL_Obj05_RefPosIndex : 0|4@1+ (1,0) [0|15] "" Vector__XXX
 SG_ RRL_Obj05_Dx : 0|13@1+ (0.0625,-256) [-256|255.9375] "m" Vector__XXX
 SG_ RRL_Obj05_Dy : 0|11@1+ (0.125,-128) [-128|127.875] "m" Vector__XXX
 SG_ RRL_Obj05_DxVnce : 0|12@1+ (0.01,0) [0|30] "m^2" Vector__XXX
 SG_ RRL_Obj05_DyVnce : 0|12@1+ (0.01,0) [0|30] "m^2" Vector__XXX
 SG_ RRL_Obj05_Vx : 0|12@1+ (0.0625,-128) [-128|127.9375] "m/s" Vector__XXX
 SG_ RRL_Obj05_WidthVnce : 0|12@1+ (0.01,0) [0|30] "m^2" Vector__XXX
 SG_ RRL_Obj05_Width : 0|7@1+ (0.125,0) [0|15.875] "m" Vector__XXX
 SG_ RRL_Obj05_Valid : 0|1@1+ (1,0) [0|1] "" Vector__XXX
 SG_ RRL_Obj05_ID : 0|7@1+ (1,0) [0|127] "" Vector__XXX
 SG_ RRL_Obj05_Length : 0|7@1+ (0.125,0) [0|15.875] "m" Vector__XXX
 SG_ RRL_Obj05_MovingObserved : 0|6@1+ (2,0) [0|100] "%" Vector__XXX
 SG_ RRL_Obj05_MovingProbability : 0|6@1+ (2,0) [0|100] "%" Vector__XXX
 SG_ RRR_Obj00_01_CRC : 0|16@1+ (1,0) [0|65535] "" Vector__XXX
 SG_ RRR_Obj00_01_AliveCtr : 0|8@1+ (1,0) [0|255] "" Vector__XXX
 SG_ RRR_Obj00_01_ProtBlockCtr : 0|4@1+ (1,0) [0|15] "" Vector__XXX
 SG_ RRR_Obj00_RefPosIndex : 0|4@1+ (1,0) [0|15] "" Vector__XXX
 SG_ RRR_Obj00_Dx : 0|13@1+ (0.0625,-256) [-256|255.9375] "m" Vector__XXX
 SG_ RRR_Obj00_Dy : 0|11@1+ (0.125,-128) [-128|127.875] "m" Vector__XXX
 SG_ RRR_Obj00_DxVnce : 0|12@1+ (0.01,0) [0|30] "m^2" Vector__XXX
 SG_ RRR_Obj00_DyVnce : 0|12@1+ (0.01,0) [0|30] "m^2" Vector__XXX
 SG_ RRR_Obj00_Vx : 0|12@1+ (0.0625,-128) [-128|127.9375] "m/s" Vector__XXX
 SG_ RRR_Obj00_WidthVnce : 0|12@1+ (0.01,0) [0|30] "m^2" Vector__XXX
 SG_ RRR_Obj00_Width : 0|7@1+ (0.125,0) [0|15.875] "m" Vector__XXX
 SG_ RRR_Obj00_Valid : 0|1@1+ (1,0) [0|1] "" Vector__XXX
 SG_ RRR_Obj00_ID : 0|7@1+ (1,0) [0|127] "" Vector__XXX
 SG_ RRR_Obj00_Length : 0|7@1+ (0.125,0) [0|15.875] "m" Vector__XXX
 SG_ RRR_Obj00_MovingObserved : 0|6@1+ (2,0) [0|100] "%" Vector__XXX
 SG_ RRR_Obj00_MovingProbability : 0|6@1+ (2,0) [0|100] "%" Vector__XXX
 SG_ RRR_Obj01_RefPosIndex : 0|4@1+ (1,0) [0|15] "" Vector__XXX
 SG_ RRR_Obj01_Dx : 0|13@1+ (0.0625,-256) [-256|255.9375] "m" Vector__XXX
 SG_ RRR_Obj01_Dy : 0|11@1+ (0.125,-128) [-128|127.875] "m" Vector__XXX
 SG_ RRR_Obj01_DxVnce : 0|12@1+ (0.01,0) [0|30] "m^2" Vector__XXX
 SG_ RRR_Obj01_DyVnce : 0|12@1+ (0.01,0) [0|30] "m^2" Vector__XXX
 SG_ RRR_Obj01_Vx : 0|12@1+ (0.0625,-128) [-128|127.9375] "m/s" Vector__XXX
 SG_ RRR_Obj01_WidthVnce : 0|12@1+ (0.01,0) [0|30] "m^2" Vector__XXX
 SG_ RRR_Obj01_Width : 0|7@1+ (0.125,0) [0|15.875] "m" Vector__XXX
 SG_ RRR_Obj01_Valid : 0|1@1+ (1,0) [0|1] "" Vector__XXX
 SG_ RRR_Obj01_ID : 0|7@1+ (1,0) [0|127] "" Vector__XXX
 SG_ RRR_Obj01_Length : 0|7@1+ (0.125,0) [0|15.875] "m" Vector__XXX
 SG_ RRR_Obj01_MovingObserved : 0|6@1+ (2,0) [0|100] "%" Vector__XXX
 SG_ RRR_Obj01_MovingProbability : 0|6@1+ (2,0) [0|100] "%" Vector__XXX
 SG_ RRR_Obj02_03_CRC : 0|16@1+ (1,0) [0|65535] "" Vector__XXX
 SG_ RRR_Obj02_03_AliveCtr : 0|8@1+ (1,0) [0|255] "" Vector__XXX
 SG_ RRR_Obj02_03_ProtBlockCtr : 0|4@1+ (1,0) [0|15] "" Vector__XXX
 SG_ RRR_Obj02_RefPosIndex : 0|4@1+ (1,0) [0|15] "" Vector__XXX
 SG_ RRR_Obj02_Dx : 0|13@1+ (0.0625,-256) [-256|255.9375] "m" Vector__XXX
 SG_ RRR_Obj02_Dy : 0|11@1+ (0.125,-128) [-128|127.875] "m" Vector__XXX
 SG_ RRR_Obj02_DxVnce : 0|12@1+ (0.01,0) [0|30] "m^2" Vector__XXX
 SG_ RRR_Obj02_DyVnce : 0|12@1+ (0.01,0) [0|30] "m^2" Vector__XXX
 SG_ RRR_Obj02_Vx : 0|12@1+ (0.0625,-128) [-128|127.9375] "m/s" Vector__XXX
 SG_ RRR_Obj02_WidthVnce : 0|12@1+ (0.01,0) [0|30] "m^2" Vector__XXX
 SG_ RRR_Obj02_Width : 0|7@1+ (0.125,0) [0|15.875] "m" Vector__XXX
 SG_ RRR_Obj02_Valid : 0|1@1+ (1,0) [0|1] "" Vector__XXX
 SG_ RRR_Obj02_ID : 0|7@1+ (1,0) [0|127] "" Vector__XXX
 SG_ RRR_Obj02_Length : 0|7@1+ (0.125,0) [0|15.875] "m" Vector__XXX
 SG_ RRR_Obj02_MovingObserved : 0|6@1+ (2,0) [0|100] "%" Vector__XXX
 SG_ RRR_Obj02_MovingProbability : 0|6@1+ (2,0) [0|100] "%" Vector__XXX
 SG_ RRR_Obj03_RefPosIndex : 0|4@1+ (1,0) [0|15] "" Vector__XXX
 SG_ RRR_Obj03_Dx : 0|13@1+ (0.0625,-256) [-256|255.9375] "m" Vector__XXX
 SG_ RRR_Obj03_Dy : 0|11@1+ (0.125,-128) [-128|127.875] "m" Vector__XXX
 SG_ RRR_Obj03_DxVnce : 0|12@1+ (0.01,0) [0|30] "m^2" Vector__XXX
 SG_ RRR_Obj03_DyVnce : 0|12@1+ (0.01,0) [0|30] "m^2" Vector__XXX
 SG_ RRR_Obj03_Vx : 0|12@1+ (0.0625,-128) [-128|127.9375] "m/s" Vector__XXX
 SG_ RRR_Obj03_WidthVnce : 0|12@1+ (0.01,0) [0|30] "m^2" Vector__XXX
 SG_ RRR_Obj03_Width : 0|7@1+ (0.125,0) [0|15.875] "m" Vector__XXX
 SG_ RRR_Obj03_Valid : 0|1@1+ (1,0) [0|1] "" Vector__XXX
 SG_ RRR_Obj03_ID : 0|7@1+ (1,0) [0|127] "" Vector__XXX
 SG_ RRR_Obj03_Length : 0|7@1+ (0.125,0) [0|15.875] "m" Vector__XXX
 SG_ RRR_Obj03_MovingObserved : 0|6@1+ (2,0) [0|100] "%" Vector__XXX
 SG_ RRR_Obj03_MovingProbability : 0|6@1+ (2,0) [0|100] "%" Vector__XXX
 SG_ RRR_Obj04_05_CRC : 0|16@1+ (1,0) [0|65535] "" Vector__XXX
 SG_ RRR_Obj04_05_AliveCtr : 0|8@1+ (1,0) [0|255] "" Vector__XXX
 SG_ RRR_Obj04_05_ProtBlockCtr : 0|4@1+ (1,0) [0|15] "" Vector__XXX
 SG_ RRR_Obj04_RefPosIndex : 0|4@1+ (1,0) [0|15] "" Vector__XXX
 SG_ RRR_Obj04_Dx : 0|13@1+ (0.0625,-256) [-256|255.9375] "m" Vector__XXX
 SG_ RRR_Obj04_Dy : 0|11@1+ (0.125,-128) [-128|127.875] "m" Vector__XXX
 SG_ RRR_Obj04_DxVnce : 0|12@1+ (0.01,0) [0|30] "m^2" Vector__XXX
 SG_ RRR_Obj04_DyVnce : 0|12@1+ (0.01,0) [0|30] "m^2" Vector__XXX
 SG_ RRR_Obj04_Vx : 0|12@1+ (0.0625,-128) [-128|127.9375] "m/s" Vector__XXX
 SG_ RRR_Obj04_WidthVnce : 0|12@1+ (0.01,0) [0|30] "m^2" Vector__XXX
 SG_ RRR_Obj04_Width : 0|7@1+ (0.125,0) [0|15.875] "m" Vector__XXX
 SG_ RRR_Obj04_Valid : 0|1@1+ (1,0) [0|1] "" Vector__XXX
 SG_ RRR_Obj04_ID : 0|7@1+ (1,0) [0|127] "" Vector__XXX
 SG_ RRR_Obj04_Length : 0|7@1+ (0.125,0) [0|15.875] "m" Vector__XXX
 SG_ RRR_Obj04_MovingObserved : 0|6@1+ (2,0) [0|100] "%" Vector__XXX
 SG_ RRR_Obj04_MovingProbability : 0|6@1+ (2,0) [0|100] "%" Vector__XXX
 SG_ RRR_Obj05_RefPosIndex : 0|4@1+ (1,0) [0|15] "" Vector__XXX
 SG_ RRR_Obj05_Dx : 0|13@1+ (0.0625,-256) [-256|255.9375] "m" Vector__XXX
 SG_ RRR_Obj05_Dy : 0|11@1+ (0.125,-128) [-128|127.875] "m" Vector__XXX
 SG_ RRR_Obj05_DxVnce : 0|12@1+ (0.01,0) [0|30] "m^2" Vector__XXX
 SG_ RRR_Obj05_DyVnce : 0|12@1+ (0.01,0) [0|30] "m^2" Vector__XXX
 SG_ RRR_Obj05_Vx : 0|12@1+ (0.0625,-128) [-128|127.9375] "m/s" Vector__XXX
 SG_ RRR_Obj05_WidthVnce : 0|12@1+ (0.01,0) [0|30] "m^2" Vector__XXX
 SG_ RRR_Obj05_Width : 0|7@1+ (0.125,0) [0|15.875] "m" Vector__XXX
 SG_ RRR_Obj05_Valid : 0|1@1+ (1,0) [0|1] "" Vector__XXX
 SG_ RRR_Obj05_ID : 0|7@1+ (1,0) [0|127] "" Vector__XXX
 SG_ RRR_Obj05_Length : 0|7@1+ (0.125,0) [0|15.875] "m" Vector__XXX
 SG_ RRR_Obj05_MovingObserved : 0|6@1+ (2,0) [0|100] "%" Vector__XXX
 SG_ RRR_Obj05_MovingProbability : 0|6@1+ (2,0) [0|100] "%" Vector__XXX

BO_ 941 RFC_FCT_AEB: 20 RadarFrontCenter
 SG_ AEB_TTC_tiplLoWarnAcoustic : 144|10@1+ (0.1,0) [0|10] "s" Vector__XXX
 SG_ AddSenNotAsLoTgOncEmBrkA : 49|1@1+ (1,0) [0|1] "" Vector__XXX
 SG_ ObjNotMeaEgoTurnTgtCrFullBrake : 136|1@1+ (1,0) [0|1] "" Vector__XXX
 SG_ ObjNotMeaEgoTurnTgtLoFullBrake : 135|1@1+ (1,0) [0|1] "" Vector__XXX
 SG_ ObjNotMeaEgoLongTgtLoFullBrake : 134|1@1+ (1,0) [0|1] "" Vector__XXX
 SG_ ObjNotMeaEgoLongTgtLoEmBrakeA : 133|1@1+ (1,0) [0|1] "" Vector__XXX
 SG_ ObjNotMeaEgoLongTgtOncFullBrk : 132|1@1+ (1,0) [0|1] "" Vector__XXX
 SG_ ObjNotMeaEgoLongTgtOncEmBrkA : 131|1@1+ (1,0) [0|1] "" Vector__XXX
 SG_ ObjNotMeaEgoLongTgtCrEmBrkA : 130|1@1+ (1,0) [0|1] "" Vector__XXX
 SG_ ObjNotMeaEgoLongTgtCrFullBrk : 129|1@1+ (1,0) [0|1] "" Vector__XXX
 SG_ ObjNotVerifEgoTurnTgtLoFullBrk : 128|1@1+ (1,0) [0|1] "" Vector__XXX
 SG_ ObjNotVerifEgoTurnTgtCrFullBrk : 127|1@1+ (1,0) [0|1] "" Vector__XXX
 SG_ ObjNotVerifEgoLongTgtCrEmBrkA : 126|1@1+ (1,0) [0|1] "" Vector__XXX
 SG_ ObjNotVerifEgoLongTgtCrFullBrk : 125|1@1+ (1,0) [0|1] "" Vector__XXX
 SG_ ObjNotVerifEgoLongTgtOncEmBrkA : 124|1@1+ (1,0) [0|1] "" Vector__XXX
 SG_ ObjNotVerifEgoLongTgtOncFullBrk : 123|1@1+ (1,0) [0|1] "" Vector__XXX
 SG_ ObjNotVerifEgoLongTgtLoEmBrkA : 122|1@1+ (1,0) [0|1] "" Vector__XXX
 SG_ ObjNotVerifEgoLongTgtLoFullBrk : 121|1@1+ (1,0) [0|1] "" Vector__XXX
 SG_ ObjQuaEgoTurnTgtCrWarnAcoustic : 120|1@1+ (1,0) [0|1] "" Vector__XXX
 SG_ ObjQuaEgoTurnTgtCrPrefill : 119|1@1+ (1,0) [0|1] "" Vector__XXX
 SG_ ObjQuaEgoTurnTgtCrFullBrk : 118|1@1+ (1,0) [0|1] "" Vector__XXX
 SG_ ObjQuaEgoTurnTgtLoPrefill : 117|1@1+ (1,0) [0|1] "" Vector__XXX
 SG_ ObjQuaEgoTurnTgtLoFullBrk : 116|1@1+ (1,0) [0|1] "" Vector__XXX
 SG_ ObjQuaEgoLongTgtLoWarnAcoustic : 115|1@1+ (1,0) [0|1] "" Vector__XXX
 SG_ ObjQuaEgoLongTgtLoWarnHaptic : 114|1@1+ (1,0) [0|1] "" Vector__XXX
 SG_ ObjQuaEgoLongTgtLoPrefill : 113|1@1+ (1,0) [0|1] "" Vector__XXX
 SG_ ObjQuaEgoLongTgtLoPartialBrk : 112|1@1+ (1,0) [0|1] "" Vector__XXX
 SG_ ObjQuaEgoLongTgtLoFullBrk : 111|1@1+ (1,0) [0|1] "" Vector__XXX
 SG_ ObjQuaEgoLongTgtLoEmBrkA : 110|1@1+ (1,0) [0|1] "" Vector__XXX
 SG_ ObjQuaEgoLongTgtOncPrefill : 109|1@1+ (1,0) [0|1] "" Vector__XXX
 SG_ ObjQuaEgoLongTgtOncFullBrk : 108|1@1+ (1,0) [0|1] "" Vector__XXX
 SG_ ObjQuaEgoLongTgtOncEmBrkA : 107|1@1+ (1,0) [0|1] "" Vector__XXX
 SG_ ObjQuaEgoLongTgtCrWarnAcoustic : 106|1@1+ (1,0) [0|1] "" Vector__XXX
 SG_ ObjQuaEgoLongTgtCrPrefill : 105|1@1+ (1,0) [0|1] "" Vector__XXX
 SG_ ObjQuaEgoLongTgtCrEmBrkA : 104|1@1+ (1,0) [0|1] "" Vector__XXX
 SG_ ObjQuaEgoLongTgtCrFullBrake : 103|1@1+ (1,0) [0|1] "" Vector__XXX
 SG_ LatEgoLongTgtLoWarnAcoustic : 102|1@1+ (1,0) [0|1] "" Vector__XXX
 SG_ LongEgoLongTgtLoWarnAcoustic : 101|1@1+ (1,0) [0|1] "" Vector__XXX
 SG_ LongBelowEgoLongBtLoLatInfor : 100|1@1+ (1,0) [0|1] "" Vector__XXX
 SG_ LongBelowEgoLongBtLoWarnHaptic : 99|1@1+ (1,0) [0|1] "" Vector__XXX
 SG_ LongBelowEgoLongBtLoWarnAcoustic : 98|1@1+ (1,0) [0|1] "" Vector__XXX
 SG_ LongBelowEgoLongBTgtLoPrefill : 97|1@1+ (1,0) [0|1] "" Vector__XXX
 SG_ LongBelowEgoLongBTgtLoPartialBrk : 96|1@1+ (1,0) [0|1] "" Vector__XXX
 SG_ LongBelowEgoLongBTgtLoFullBrk : 87|1@1+ (1,0) [0|1] "" Vector__XXX
 SG_ LongBelowEgoLongBTgtOncPrefill : 88|1@1+ (1,0) [0|1] "" Vector__XXX
 SG_ LongBelowEgoLongBTgtOncFullBrk : 86|1@1+ (1,0) [0|1] "" Vector__XXX
 SG_ LongBelowEgoLongBTgtLoEmBrkA : 85|1@1+ (1,0) [0|1] "" Vector__XXX
 SG_ LongBelowEgoLongBTgtOncEmBrkA : 84|1@1+ (1,0) [0|1] "" Vector__XXX
 SG_ LongAboveEgoLongATgtOncPrefill : 83|1@1+ (1,0) [0|1] "" Vector__XXX
 SG_ LongAboveEgoLongATgtOncFullBrk : 82|1@1+ (1,0) [0|1] "" Vector__XXX
 SG_ LongAboveEgoLongATgtOncEmBrkA : 81|1@1+ (1,0) [0|1] "" Vector__XXX
 SG_ StandstillProlongTimeCond : 80|1@1+ (1,0) [0|1] "" Vector__XXX
 SG_ AccAvoidNotCrEgoLongTgtCross : 79|1@1+ (1,0) [0|1] "" Vector__XXX
 SG_ AccAvoidLatNoLoTgOncPrefill : 78|1@1+ (1,0) [0|1] "" Vector__XXX
 SG_ AccAvoidLatNoLoTgOncFullBrk : 77|1@1+ (1,0) [0|1] "" Vector__XXX
 SG_ AccAvoidLatNoLoTgOncEmBrkA : 76|1@1+ (1,0) [0|1] "" Vector__XXX
 SG_ AccAvoidNoCrCondEgoLoTgtLong : 75|1@1+ (1,0) [0|1] "" Vector__XXX
 SG_ BlockTiNoElaEbaCond : 74|1@1+ (1,0) [0|1] "" Vector__XXX
 SG_ BlockTiNotElaFullBrkCond : 73|1@1+ (1,0) [0|1] "" Vector__XXX
 SG_ BlockTiNotElaWarnHapticCond : 72|1@1+ (1,0) [0|1] "" Vector__XXX
 SG_ BlockTiNotElaWarnAcousticCond : 71|1@1+ (1,0) [0|1] "" Vector__XXX
 SG_ BlockTiNotElaPrefillCond : 70|1@1+ (1,0) [0|1] "" Vector__XXX
 SG_ OnlyByAddSenLoTgOncFullBrk : 69|1@1+ (1,0) [0|1] "" Vector__XXX
 SG_ OnlyByAddSenTuTgCrFullBrk : 68|1@1+ (1,0) [0|1] "" Vector__XXX
 SG_ OnlyByAddSenTuTgLoFullBrk : 67|1@1+ (1,0) [0|1] "" Vector__XXX
 SG_ OnlyByAddSenLoTgCrFullBrk : 66|1@1+ (1,0) [0|1] "" Vector__XXX
 SG_ OnlyByAddSenLoTgLoFullBrk : 65|1@1+ (1,0) [0|1] "" Vector__XXX
 SG_ AddSenNotAsTuTgCrWarnAcoustic : 64|1@1+ (1,0) [0|1] "" Vector__XXX
 SG_ AddSenNotAsTuTgCrFullBrk : 63|1@1+ (1,0) [0|1] "" Vector__XXX
 SG_ AddSenNotAsTuTgLoFullBrk : 62|1@1+ (1,0) [0|1] "" Vector__XXX
 SG_ AddSenNotAsLoTgCrWarnAcoustic : 61|1@1+ (1,0) [0|1] "" Vector__XXX
 SG_ AddSenNotAsLoTgCrEmBrkA : 60|1@1+ (1,0) [0|1] "" Vector__XXX
 SG_ AddSenNotAsLoTgCrFullBrk : 59|1@1+ (1,0) [0|1] "" Vector__XXX
 SG_ AddSenNotAsdLoTgLoEmBrkA : 58|1@1+ (1,0) [0|1] "" Vector__XXX
 SG_ AddSenNotAsLoTgLoWarnHaptic : 57|1@1+ (1,0) [0|1] "" Vector__XXX
 SG_ AddSenNotAsLoTgLoWarnAcoustic : 56|1@1+ (1,0) [0|1] "" Vector__XXX
 SG_ AddSenNotAsLoTgOncFullBrk : 55|1@1+ (1,0) [0|1] "" Vector__XXX
 SG_ AddSenrNotAsLoTgLoPartialBrk : 54|1@1+ (1,0) [0|1] "" Vector__XXX
 SG_ AddSenNotAsLoTgLoFullBrk : 53|1@1+ (1,0) [0|1] "" Vector__XXX
 SG_ CurvatureAboveThresCond : 52|1@1+ (1,0) [0|1] "" Vector__XXX
 SG_ DriverOvertakingCond : 51|1@1+ (1,0) [0|1] "" Vector__XXX
 SG_ DriverBrkSignCustomerCond : 50|1@1+ (1,0) [0|1] "" Vector__XXX
 SG_ TTCThEgoLoTgtLoWarnAcoustic : 15|1@1+ (1,0) [0|1] "" Vector__XXX
 SG_ AEB_AebPObjNotMoving : 48|1@1+ (1,0) [0|1] "" Vector__XXX
 SG_ AEB_Standstill_State : 46|2@1+ (1,0) [0|2] "" Vector__XXX
 SG_ AEB_TiplTurnFullBrk_State : 44|2@1+ (1,0) [0|2] "" Vector__XXX
 SG_ AEB_TixlFullBrk_State : 42|2@1+ (1,0) [0|2] "" Vector__XXX
 SG_ AEB_TixlWarnAcoustic_State : 40|2@1+ (1,0) [0|2] "" Vector__XXX
 SG_ AEB_CfmEba_State : 38|2@1+ (1,0) [0|2] "" Vector__XXX
 SG_ AEB_CfmFullBrk_State : 36|2@1+ (1,0) [0|2] "" Vector__XXX
 SG_ AEB_CfmWarnAcoustic_State : 34|2@1+ (1,0) [0|2] "" Vector__XXX
 SG_ AEB_TiplLoOncEba_State : 32|2@1+ (1,0) [0|2] "" Vector__XXX
 SG_ AEB_TiplLoFullBrkOnc_State : 30|2@1+ (1,0) [0|2] "" Vector__XXX
 SG_ AEB_TiplLoEba_State : 28|2@1+ (1,0) [0|2] "" Vector__XXX
 SG_ AEB_TiplLoPartialBrk_State : 26|2@1+ (1,0) [0|2] "" Vector__XXX
 SG_ AEB_TiplLoFullBrk_State : 24|2@1+ (1,0) [0|2] "" Vector__XXX
 SG_ AEB_TiplLoWarnAcoustic_State : 13|2@1+ (1,0) [0|3] "" Vector__XXX
 SG_ AEB_TiplLoWarnHaptic_State : 11|2@1+ (1,0) [0|3] "" Vector__XXX
 SG_ AEB_TimeToBrk : 0|11@1- (0.01,0) [-10|10] "s" Vector__XXX

BO_ 940 RFC_FCT_ACC: 24 RadarFrontCenter
 SG_ fct_acc_reserved : 160|8@1+ (1,0) [0|255] "" Vector__XXX
 SG_ IsconditionVLCNotActive : 14|1@1+ (1,0) [0|1] "" Vector__XXX
 SG_ IsconditionHillDescentCtrlActAPC : 13|1@1+ (1,0) [0|1] "" Vector__XXX
 SG_ IsconditionDisplaySpdTooHighAPC : 12|1@1+ (1,0) [0|1] "" Vector__XXX
 SG_ IsConditionTargetAccelisPositive : 11|1@1+ (1,0) [0|1] "" Vector__XXX
 SG_ IsConditionHillDescentCtrlActive : 10|1@1+ (1,0) [0|1] "" Vector__XXX
 SG_ IsconditionCancelButtonPressed : 9|1@1+ (1,0) [0|1] "" Vector__XXX
 SG_ ACC_objectDataList0movingState : 152|3@1+ (1,0) [0|8] "" Vector__XXX
 SG_ ACC_objectDataList0vy : 144|8@1+ (0.5,-64) [-64|63.5] "" Vector__XXX
 SG_ ACC_objectDataList0vx : 136|8@1+ (0.5,-64) [-64|63.5] "" Vector__XXX
 SG_ ACC_objectDataList0dy : 128|8@1+ (0.5,-64) [-64|63.5] "" Vector__XXX
 SG_ ACC_objectDataList0dx : 120|8@1+ (1,0) [0|255] "" Vector__XXX
 SG_ ACC_objectDataList0fusIndex : 112|8@1+ (1,0) [0|255] "" Vector__XXX
 SG_ IsconditionCameraBlindness : 109|1@1+ (1,0) [0|1] "" Vector__XXX
 SG_ IsconditionNoBrakeForce : 108|1@1+ (1,0) [0|1] "" Vector__XXX
 SG_ IsconditionCDDNotActive : 107|1@1+ (1,0) [0|1] "" Vector__XXX
 SG_ IsconditionVirtualButtonFromSCF : 106|1@1+ (1,0) [0|1] "" Vector__XXX
 SG_ IsconditionTrailerConnectSts : 105|1@1+ (1,0) [0|1] "" Vector__XXX
 SG_ IsconditionStandWaitExceedTimer : 104|1@1+ (1,0) [0|1] "" Vector__XXX
 SG_ IsVehicleSpeedAndTOSuppress : 103|1@1+ (1,0) [0|1] "" Vector__XXX
 SG_ IsconditionDrivDrsOpenStandstill : 102|1@1+ (1,0) [0|1] "" Vector__XXX
 SG_ IsconditionPassDrsOpenStandstill : 101|1@1+ (1,0) [0|1] "" Vector__XXX
 SG_ IsconditionTolCloseRange : 100|1@1+ (1,0) [0|1] "" Vector__XXX
 SG_ IsconditionHillDescentContActive : 99|1@1+ (1,0) [0|1] "" Vector__XXX
 SG_ IsconditionSetButtonCus : 98|1@1+ (1,0) [0|1] "" Vector__XXX
 SG_ IsconditionStandExceedTimer : 97|1@1+ (1,0) [0|1] "" Vector__XXX
 SG_ IsconditionSuspendExceedTimer : 96|1@1+ (1,0) [0|1] "" Vector__XXX
 SG_ IsconditionObjectLostCloseNotDec : 87|1@1+ (1,0) [0|1] "" Vector__XXX
 SG_ IsconditionBeltOpenNotStandstill : 86|1@1+ (1,0) [0|1] "" Vector__XXX
 SG_ IsconditionBeltOpenStandstill : 85|1@1+ (1,0) [0|1] "" Vector__XXX
 SG_ IsconditionDoorOpenNotStandstill : 84|1@1+ (1,0) [0|1] "" Vector__XXX
 SG_ IsconditionCancelButtonPressBOM : 83|1@1+ (1,0) [0|1] "" Vector__XXX
 SG_ IsconditionCusAutoResumeTimer : 82|1@1+ (1,0) [0|1] "" Vector__XXX
 SG_ isNoBrakeForceStandstillActive : 88|1@1+ (1,0) [0|1] "" Vector__XXX
 SG_ IsconditionActTriggerButton : 81|1@1+ (1,0) [0|1] "" Vector__XXX
 SG_ IsconditionESPDisabled : 80|1@1+ (1,0) [0|1] "" Vector__XXX
 SG_ IsconditionMainSwitchOff : 71|1@1+ (1,0) [0|1] "" Vector__XXX
 SG_ IsconditionBrakeTempHigh : 70|1@1+ (1,0) [0|1] "" Vector__XXX
 SG_ IsconditionHoodOpend : 69|1@1+ (1,0) [0|1] "" Vector__XXX
 SG_ IsconditionFollowObjectLostClose : 68|1@1+ (1,0) [0|1] "" Vector__XXX
 SG_ IsconditionEPBSwtApplied : 67|1@1+ (1,0) [0|1] "" Vector__XXX
 SG_ IsconditionRollingBackwards : 66|1@1+ (1,0) [0|1] "" Vector__XXX
 SG_ IsconditionDisplaySpeedTooHigh : 65|1@1+ (1,0) [0|1] "" Vector__XXX
 SG_ IsConditionFollowObjectContNot : 72|1@1+ (1,0) [0|1] "" Vector__XXX
 SG_ IsConditionTargetAcceNegative : 64|1@1+ (1,0) [0|1] "" Vector__XXX
 SG_ IsConditionDecToStop : 63|1@1+ (1,0) [0|1] "" Vector__XXX
 SG_ IsConditionStandSecureEnd : 62|1@1+ (1,0) [0|1] "" Vector__XXX
 SG_ IsConditionAcceleratorPedal : 61|1@1+ (1,0) [0|1] "" Vector__XXX
 SG_ IsConditionMaxStandTimeElapsed : 60|1@1+ (1,0) [0|1] "" Vector__XXX
 SG_ IsConditionMaxBrakeOnlyTime : 59|1@1+ (1,0) [0|1] "" Vector__XXX
 SG_ IsConditionVehicleMovAfterDrive : 58|1@1+ (1,0) [0|1] "" Vector__XXX
 SG_ isConditionStandStillTDriveOff : 57|1@1+ (1,0) [0|1] "" Vector__XXX
 SG_ IsConditionTimeInDriveOff : 56|1@1+ (1,0) [0|1] "" Vector__XXX
 SG_ IsConditionVehicleSpeedDriveOff : 55|1@1+ (1,0) [0|1] "" Vector__XXX
 SG_ IsConditionOverrideActive : 54|1@1+ (1,0) [0|1] "" Vector__XXX
 SG_ IsConditionAsrTimerFulfilled : 53|1@1+ (1,0) [0|1] "" Vector__XXX
 SG_ IsConditionAbsTimerFulfilled : 52|1@1+ (1,0) [0|1] "" Vector__XXX
 SG_ IsConditionFadeoutFinished : 51|1@1+ (1,0) [0|1] "" Vector__XXX
 SG_ IsConditionDriveOffAutomatic : 50|1@1+ (1,0) [0|1] "" Vector__XXX
 SG_ IsConditionDriveOffConfirmed : 49|1@1+ (1,0) [0|1] "" Vector__XXX
 SG_ IsConditionBrakePedalPressed : 48|1@1+ (1,0) [0|1] "" Vector__XXX
 SG_ IsConditionVehicleSpeedInvalid : 47|1@1+ (1,0) [0|1] "" Vector__XXX
 SG_ IsConditionEscTimerFulfilled : 46|1@1+ (1,0) [0|1] "" Vector__XXX
 SG_ IsConditionExternalDeactivation : 45|1@1+ (1,0) [0|1] "" Vector__XXX
 SG_ IsConditionIrreversibleFailure : 44|1@1+ (1,0) [0|1] "" Vector__XXX
 SG_ IsConditionReversibleFailure : 43|1@1+ (1,0) [0|1] "" Vector__XXX
 SG_ IsConditionInit2offFulfilled : 42|1@1+ (1,0) [0|1] "" Vector__XXX
 SG_ IsConditionStandstillFulfilled : 41|1@1+ (1,0) [0|1] "" Vector__XXX
 SG_ IsConditionDriveOffRequest : 40|1@1+ (1,0) [0|1] "" Vector__XXX
 SG_ IsConditionActivationRequest : 23|1@1+ (1,0) [0|1] "" Vector__XXX
 SG_ IsConditionSpeedInvalidAccBase : 22|1@1+ (1,0) [0|1] "" Vector__XXX
 SG_ IsConditionRoadSlopeDeacnLow : 21|1@1+ (1,0) [0|1] "" Vector__XXX
 SG_ IsConditionRoadSlopeDeacHigh : 32|1@1+ (1,0) [0|1] "" Vector__XXX
 SG_ IsConditionRoadSlopeApcLow : 20|1@1+ (1,0) [0|1] "" Vector__XXX
 SG_ IsConditionRoadSlopeApcHigh : 19|1@1+ (1,0) [0|1] "" Vector__XXX
 SG_ IsConditionParkingAssistActive : 18|1@1+ (1,0) [0|1] "" Vector__XXX
 SG_ IsConditionEngineNotRunning : 24|1@1+ (1,0) [0|1] "" Vector__XXX
 SG_ IsConditionAccNotEnabled : 17|1@1+ (1,0) [0|1] "" Vector__XXX
 SG_ IsConditionElectronicParkBrake : 16|1@1+ (1,0) [0|1] "" Vector__XXX
 SG_ IsConditionNoForwardGearEngaged : 8|1@1+ (1,0) [0|1] "" Vector__XXX
 SG_ IsConditionDriverSeatBeltOpen : 7|1@1+ (1,0) [0|1] "" Vector__XXX
 SG_ IsConditionAnyDoorOpenFulfilled : 6|1@1+ (1,0) [0|1] "" Vector__XXX
 SG_ IsConditionDeactivationRequest : 5|1@1+ (1,0) [0|1] "" Vector__XXX
 SG_ IsBrkPedalPressNotStandstill : 4|1@1+ (1,0) [0|1] "" Vector__XXX
 SG_ IsConditionAebaActiveFulfilled : 3|1@1+ (1,0) [0|1] "" Vector__XXX
 SG_ IsConditionAsrActiveFulfilled : 2|1@1+ (1,0) [0|1] "" Vector__XXX
 SG_ IsConditionEscActiveFulfilled : 1|1@1+ (1,0) [0|1] "" Vector__XXX
 SG_ IsConditionAbsActiveFulfilled : 0|1@1+ (1,0) [0|1] "" Vector__XXX

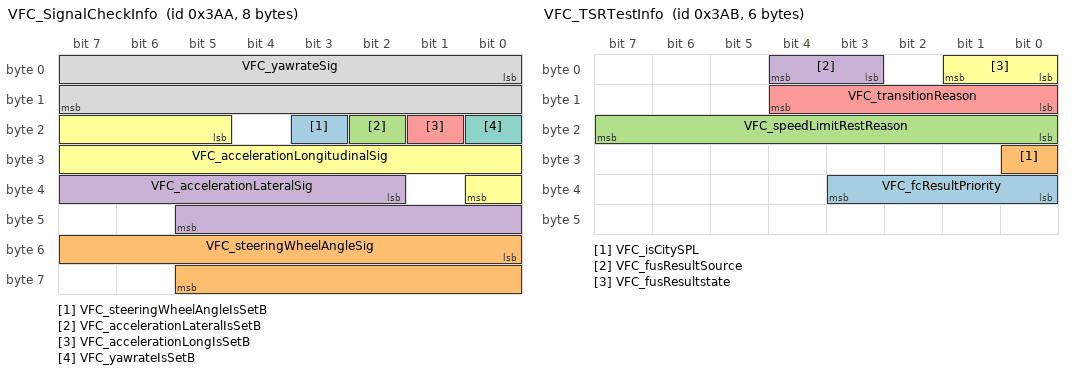
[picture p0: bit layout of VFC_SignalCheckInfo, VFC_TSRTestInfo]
BO_ 938 VFC_SignalCheckInfo: 8 MPC3
 SG_ VFC_steeringWheelAngleIsSetB : 19|1@1+ (1,0) [0|1] "" Vector__XXX
 SG_ VFC_steeringWheelAngleSig : 48|14@1+ (0.1,-780) [-780|780] "radian" Vector__XXX
 SG_ VFC_accelerationLateralIsSetB : 18|1@1+ (1,0) [0|1] "" Vector__XXX
 SG_ VFC_accelerationLateralSig : 34|12@1+ (0.001,-2) [-2|2] "m/s^2" Vector__XXX
 SG_ VFC_accelerationLongIsSetB : 17|1@1+ (1,0) [0|1] "" Vector__XXX
 SG_ VFC_accelerationLongitudinalSig : 21|12@1+ (0.001,-2) [-2|2] "m/s^2" Vector__XXX
 SG_ VFC_yawrateIsSetB : 16|1@1+ (1,0) [0|1] "" Vector__XXX
 SG_ VFC_yawrateSig : 0|16@1+ (0.01,-180) [-180|180] "radian/s" Vector__XXX

BO_ 939 VFC_TSRTestInfo: 6 MPC3
 SG_ VFC_fcResultPriority : 32|4@1- (1,0) [0|3] "" Vector__XXX
 SG_ VFC_isCitySPL : 24|1@1- (1,0) [0|1] "" Vector__XXX
 SG_ VFC_speedLimitRestReason : 16|8@1- (1,0) [0|15] "" Vector__XXX
 SG_ VFC_fusResultSource : 3|2@1+ (1,0) [0|3] "" Vector__XXX
 SG_ VFC_transitionReason : 8|5@1+ (1,0) [0|31] "" Vector__XXX
 SG_ VFC_fusResultstate : 0|2@1+ (1,0) [0|3] "" Vector__XXX

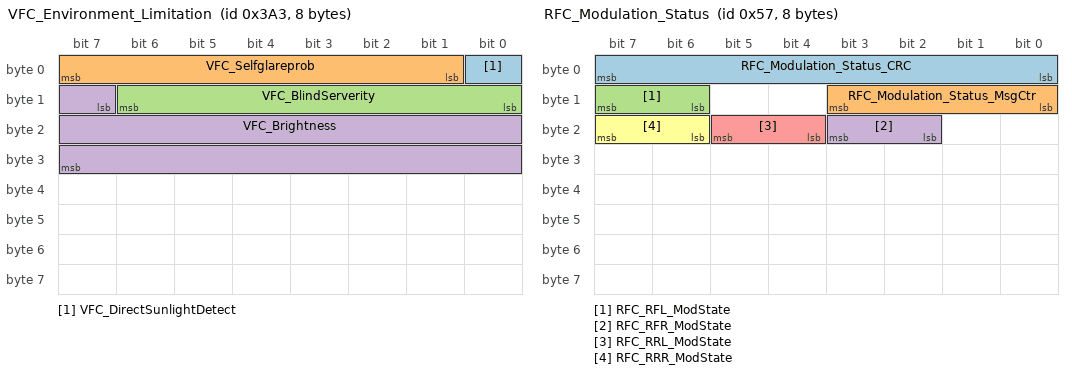
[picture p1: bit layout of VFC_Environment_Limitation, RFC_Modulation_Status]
BO_ 931 VFC_Environment_Limitation: 8 MPC3
 SG_ VFC_DirectSunlightDetect : 0|1@1+ (1,0) [0|1] ""  RadarFrontCenter
 SG_ VFC_Selfglareprob : 1|7@1+ (0.01,0) [0|1] ""  RadarFrontCenter
 SG_ VFC_BlindServerity : 8|7@1+ (0.01,0) [0|1] ""  RadarFrontCenter
 SG_ VFC_Brightness : 15|17@1+ (1,0) [0|100000] "lux"  RadarFrontCenter

BO_ 360 RFC_AEB_TGU_Hdr: 12 Vector__XXX
 SG_ RFC_AEB_TGU_Hdr_CRC : 0|8@1+ (1,0) [0|65535] ""  DASy
 SG_ RFC_AEB_TGU_Hdr_MsgCtr : 8|4@1+ (1,0) [0|255] ""  DASy
 SG_ RFC_AEB_TGU_Hdr_TimeStampStatus : 24|8@1+ (1,0) [0|255] ""  DASy
 SG_ RFC_AEB_TGU_Hdr_TimeStamp : 32|42@1+ (1,0) [0|4398046511103] "ms"  DASy
 SG_ RFC_AEB_TGU_Hdr_SensorState : 74|4@1+ (1,0) [0|15] ""  DASy

BO_ 340 RFC_ACCObjInfo0: 32 RadarFrontCenter
 SG_ RFC_ACCObjInfo0_CRC : 0|8@1+ (1,0) [0|255] ""  MPC3,DASy
 SG_ RFC_ACCObjInfo0_MsgCtr : 8|4@1+ (1,0) [0|15] ""  MPC3,DASy
 SG_ RFC_ACCObjInfo0_ID : 16|8@1+ (1,0) [0|255] ""  MPC3,DASy
 SG_ RFC_ACCObjInfo0_Dx : 24|13@1+ (0.0625,-255.9375) [-255.9375|255.9375] "m"  MPC3,DASy
 SG_ RFC_ACCObjInfo0_Vx : 53|11@1+ (0.125,-128) [-128|127.875] "mps"  MPC3,DASy
 SG_ RFC_ACCObjInfo0_Ax : 75|10@1+ (0.125,-44.5) [-44.5|44.5] "mps2"  MPC3,DASy
 SG_ RFC_ACCObjInfo0_Dy : 40|13@1+ (0.0625,-255.9375) [-255.9375|255.9375] "m"  MPC3,DASy
 SG_ RFC_ACCObjInfo0_Vy : 64|11@1+ (0.125,-128) [-128|127.875] "mps"  MPC3,DASy
 SG_ RFC_ACCObjInfo0_Ay : 85|10@1+ (0.125,-44.5) [-44.5|44.5] "mps2"  MPC3,DASy
 SG_ RFC_ACCObjInfo0_DxStd : 96|8@1+ (0.05,0) [0|12.75] "m"  MPC3,DASy
 SG_ RFC_ACCObjInfo0_VxStd : 112|6@1+ (0.2,0) [0|12.6] "mps"  MPC3,DASy
 SG_ RFC_ACCObjInfo0_AxStd : 128|5@1+ (0.35,0) [0|10.85] "mps2"  MPC3,DASy
 SG_ RFC_ACCObjInfo0_DyStd : 104|8@1+ (0.1,0) [0|25.5] "m"  MPC3,DASy
 SG_ RFC_ACCObjInfo0_VyStd : 120|6@1+ (0.2,0) [0|12.6] "mps"  MPC3,DASy
 SG_ RFC_ACCObjInfo0_AyStd : 136|5@1+ (0.35,0) [0|10.85] "mps2"  MPC3,DASy
 SG_ RFC_ACCObjInfo0_ValidFlag : 141|1@1+ (1,0) [0|1] ""  MPC3,DASy
 SG_ RFC_ACCObjInfo0_UpdateFlag : 142|1@1+ (1,0) [0|1] ""  MPC3,DASy
 SG_ RFC_ACCObjInfo0_MirProb : 176|7@1+ (1,0) [0|100] "percent"  MPC3,DASy
 SG_ RFC_ACCObjInfo0_ObsProb : 144|7@1+ (1,0) [0|100] "percent"  MPC3,DASy
 SG_ RFC_ACCObjInfo0_ExistProb : 152|7@1+ (1,0) [0|100] "percent"  MPC3,DASy
 SG_ RFC_ACCObjInfo0_Type : 160|4@1+ (1,0) [0|15] ""  MPC3,DASy
 SG_ RFC_ACCObjInfo0_EDynProp : 164|4@1+ (1,0) [0|15] ""  MPC3,DASy
 SG_ RFC_ACCObjInfo0_UiLifeCycles : 168|7@1+ (1,0) [0|127] ""  MPC3,DASy
 SG_ RFC_ACCObjInfo0_RCS : 184|11@1+ (0.1,-100) [-100|100] "dBm"  MPC3,DASy
 SG_ RFC_ACCObjInfo0_RFF : 200|8@1+ (1,0) [0|255] ""  MPC3,DASy
 SG_ RFC_ACCObjInfo0_Width : 208|16@1- (0.0078125,0) [-256|255.9921875] ""  MPC3,DASy

BO_ 361 RFC_AEB_TGU_AEBP_Obj: 32 Vector__XXX
 SG_ RFC_AEB_TGU_AEBP_Obj_CRC : 0|8@1+ (1,0) [0|255] ""  DASy
 SG_ RFC_AEB_TGU_AEBP_Obj_MsgCtr : 8|4@1+ (1,0) [0|15] ""  DASy
 SG_ RFC_AEB_TGU_AEBP_Obj_ID : 16|8@1+ (1,0) [0|255] ""  DASy
 SG_ RFC_AEB_TGU_AEBP_Obj_Dx : 24|13@1+ (0.0625,-255.9375) [-255.9375|255.9375] "m"  DASy
 SG_ RFC_AEB_TGU_AEBP_Obj_Vx : 53|11@1+ (0.125,-128) [-128|127.875] "mps"  DASy
 SG_ RFC_AEB_TGU_AEBP_Obj_Ax : 75|10@1+ (0.125,-44.5) [-44.5|44.5] "mps2"  DASy
 SG_ RFC_AEB_TGU_AEBP_Obj_Dy : 40|13@1+ (0.0625,-255.9375) [-255.9375|255.9375] "m"  DASy
 SG_ RFC_AEB_TGU_AEBP_Obj_Vy : 64|11@1+ (0.125,-128) [-128|127.875] "mps"  DASy
 SG_ RFC_AEB_TGU_AEBP_Obj_Ay : 85|10@1+ (0.125,-44.5) [-44.5|44.5] "mps2"  DASy
 SG_ RFC_AEB_TGU_AEBP_Obj_DxStd : 96|8@1+ (0.05,0) [0|12.75] "m"  DASy
 SG_ RFC_AEB_TGU_AEBP_Obj_VxStd : 112|6@1+ (0.2,0) [0|12.6] "mps"  DASy
 SG_ RFC_AEB_TGU_AEBP_Obj_AxStd : 128|5@1+ (0.35,0) [0|10.85] "mps2"  DASy
 SG_ RFC_AEB_TGU_AEBP_Obj_DyStd : 104|8@1+ (0.1,0) [0|25.5] "m"  DASy
 SG_ RFC_AEB_TGU_AEBP_Obj_VyStd : 120|6@1+ (0.2,0) [0|12.6] "mps"  DASy
 SG_ RFC_AEB_TGU_AEBP_Obj_AyStd : 136|5@1+ (0.35,0) [0|10.85] "mps2"  DASy
 SG_ RFC_AEB_TGU_AEBP_Obj_ValidFlag : 141|1@1+ (1,0) [0|1] ""  DASy
 SG_ RFC_AEB_TGU_AEBP_Obj_UpdateFlag : 142|1@1+ (1,0) [0|1] ""  DASy
 SG_ RFC_AEB_TGU_AEBP_Obj_MirProb : 176|7@1+ (1,0) [0|100] "percent"  DASy
 SG_ RFC_AEB_TGU_AEBP_Obj_ObsProb : 144|7@1+ (1,0) [0|100] "percent"  DASy
 SG_ RFC_AEB_TGU_AEBP_Obj_ExistProb : 152|7@1+ (1,0) [0|100] "percent"  DASy
 SG_ RFC_AEB_TGU_AEBP_Obj_Type : 160|4@1+ (1,0) [0|15] ""  DASy
 SG_ RFC_AEB_TGU_AEBP_Obj_EDynProp : 164|4@1+ (1,0) [0|15] ""  DASy
 SG_ RFC_AEB_TGU_AEBP_Obj_UiLifeCyc : 168|7@1+ (1,0) [0|127] ""  DASy
 SG_ RFC_AEB_TGU_AEBP_Obj_RCS : 184|11@1+ (0.1,-100) [-100|100] "dBm"  DASy
 SG_ RFC_AEB_TGU_AEBP_Obj_RFF : 200|8@1+ (1,0) [0|255] ""  DASy
 SG_ RFC_AEB_TGU_AEBP_Obj_Width : 208|16@1- (0.0078125,0) [-256|255.9921875] ""  DASy

BO_ 370 RFC_AEB_TGU_Turn_Obj0_1: 64 Vector__XXX
 SG_ RFC_AEB_TGU_Turn_Obj0_1_CRC : 0|8@1+ (1,0) [0|255] ""  DASy
 SG_ RFC_AEB_TGU_Turn_Obj0_1_MsgCtr : 8|4@1+ (1,0) [0|15] ""  DASy
 SG_ RFC_AEB_TGU_Turn_Obj0_ID : 16|8@1+ (1,0) [0|255] ""  DASy
 SG_ RFC_AEB_TGU_Turn_Obj0_Dx : 24|13@1+ (0.0625,-255.9375) [-255.9375|255.9375] "m"  DASy
 SG_ RFC_AEB_TGU_Turn_Obj0_Vx : 53|11@1+ (0.125,-128) [-128|127.875] "mps"  DASy
 SG_ RFC_AEB_TGU_Turn_Obj0_Ax : 75|10@1+ (0.125,-44.5) [-44.5|44.5] "mps2"  DASy
 SG_ RFC_AEB_TGU_Turn_Obj0_Dy : 40|13@1+ (0.0625,-255.9375) [-255.9375|255.9375] "m"  DASy
 SG_ RFC_AEB_TGU_Turn_Obj0_Vy : 64|11@1+ (0.125,-128) [-128|127.875] "mps"  DASy
 SG_ RFC_AEB_TGU_Turn_Obj0_Ay : 85|10@1+ (0.125,-44.5) [-44.5|44.5] "mps2"  DASy
 SG_ RFC_AEB_TGU_Turn_Obj0_DxStd : 96|8@1+ (0.05,0) [0|12.75] "m"  DASy
 SG_ RFC_AEB_TGU_Turn_Obj0_VxStd : 112|6@1+ (0.2,0) [0|12.6] "mps"  DASy
 SG_ RFC_AEB_TGU_Turn_Obj0_AxStd : 128|5@1+ (0.35,0) [0|10.85] "mps2"  DASy
 SG_ RFC_AEB_TGU_Turn_Obj0_DyStd : 104|8@1+ (0.1,0) [0|25.5] "m"  DASy
 SG_ RFC_AEB_TGU_Turn_Obj0_VyStd : 120|6@1+ (0.2,0) [0|12.6] "mps"  DASy
 SG_ RFC_AEB_TGU_Turn_Obj0_AyStd : 136|5@1+ (0.35,0) [0|10.85] "mps2"  DASy
 SG_ RFC_AEB_TGU_Turn_Obj0_ValidFlag : 141|1@1+ (1,0) [0|1] ""  DASy
 SG_ RFC_AEB_TGU_Turn_Obj0_UpdateFlag : 142|1@1+ (1,0) [0|1] ""  DASy
 SG_ RFC_AEB_TGU_Turn_Obj0_MirProb : 176|7@1+ (1,0) [0|100] "percent"  DASy
 SG_ RFC_AEB_TGU_Turn_Obj0_ObsProb : 144|7@1+ (1,0) [0|100] "percent"  DASy
 SG_ RFC_AEB_TGU_Turn_Obj0_ExistProb : 152|7@1+ (1,0) [0|100] "percent"  DASy
 SG_ RFC_AEB_TGU_Turn_Obj0_Type : 160|4@1+ (1,0) [0|15] ""  DASy
 SG_ RFC_AEB_TGU_Turn_Obj0_EDynProp : 164|4@1+ (1,0) [0|15] ""  DASy
 SG_ RFC_AEB_TGU_Turn_Obj0_UiLifeCyc : 168|7@1+ (1,0) [0|127] ""  DASy
 SG_ RFC_AEB_TGU_Turn_Obj0_RCS : 184|11@1+ (0.1,-100) [-100|100] "dBm"  DASy
 SG_ RFC_AEB_TGU_Turn_Obj0_RFF : 200|8@1+ (1,0) [0|255] ""  DASy
 SG_ RFC_AEB_TGU_Turn_Obj0_Width : 208|16@1- (0.0078125,0) [-256|255.9921875] ""  DASy
 SG_ RFC_AEB_TGU_Turn_Obj1_ID : 232|8@1+ (1,0) [0|255] ""  DASy
 SG_ RFC_AEB_TGU_Turn_Obj1_Dx : 240|13@1+ (0.0625,-255.9375) [-255.9375|255.9375] "m"  DASy
 SG_ RFC_AEB_TGU_Turn_Obj1_Vx : 269|11@1+ (0.125,-128) [-128|127.875] "mps"  DASy
 SG_ RFC_AEB_TGU_Turn_Obj1_Ax : 291|10@1+ (0.125,-44.5) [-44.5|44.5] "mps2"  DASy
 SG_ RFC_AEB_TGU_Turn_Obj1_Dy : 256|13@1+ (0.0625,-255.9375) [-255.9375|255.9375] "m"  DASy
 SG_ RFC_AEB_TGU_Turn_Obj1_Vy : 280|11@1+ (0.125,-128) [-128|127.875] "mps"  DASy
 SG_ RFC_AEB_TGU_Turn_Obj1_Ay : 301|10@1+ (0.125,-44.5) [-44.5|44.5] "mps2"  DASy
 SG_ RFC_AEB_TGU_Turn_Obj1_DxStd : 312|8@1+ (0.05,0) [0|12.75] "m"  DASy
 SG_ RFC_AEB_TGU_Turn_Obj1_VxStd : 328|6@1+ (0.2,0) [0|12.6] "mps"  DASy
 SG_ RFC_AEB_TGU_Turn_Obj1_AxStd : 344|5@1+ (0.35,0) [0|10.85] "mps2"  DASy
 SG_ RFC_AEB_TGU_Turn_Obj1_DyStd : 320|8@1+ (0.1,0) [0|25.5] "m"  DASy
 SG_ RFC_AEB_TGU_Turn_Obj1_VyStd : 336|6@1+ (0.2,0) [0|12.6] "mps"  DASy
 SG_ RFC_AEB_TGU_Turn_Obj1_AyStd : 352|5@1+ (0.35,0) [0|10.85] "mps2"  DASy
 SG_ RFC_AEB_TGU_Turn_Obj1_ValidFlag : 357|1@1+ (1,0) [0|1] ""  DASy
 SG_ RFC_AEB_TGU_Turn_Obj1_UpdateFlag : 358|1@1+ (1,0) [0|1] ""  DASy
 SG_ RFC_AEB_TGU_Turn_Obj1_MirProb : 392|7@1+ (1,0) [0|100] "percent"  DASy
 SG_ RFC_AEB_TGU_Turn_Obj1_ObsProb : 360|7@1+ (1,0) [0|100] "percent"  DASy
 SG_ RFC_AEB_TGU_Turn_Obj1_ExistProb : 368|7@1+ (1,0) [0|100] "percent"  DASy
 SG_ RFC_AEB_TGU_Turn_Obj1_Type : 376|4@1+ (1,0) [0|15] ""  DASy
 SG_ RFC_AEB_TGU_Turn_Obj1_EDynProp : 380|4@1+ (1,0) [0|15] ""  DASy
 SG_ RFC_AEB_TGU_Turn_Obj1_UiLifeCyc : 384|7@1+ (1,0) [0|127] ""  DASy
 SG_ RFC_AEB_TGU_Turn_Obj1_RCS : 400|11@1+ (0.1,-100) [-100|100] "dBm"  DASy
 SG_ RFC_AEB_TGU_Turn_Obj1_RFF : 416|8@1+ (1,0) [0|255] ""  DASy
 SG_ RFC_AEB_TGU_Turn_Obj1_Width : 424|16@1- (0.0078125,0) [-256|255.9921875] ""  DASy

BO_ 369 RFC_AEB_TGU_VRU_Obj0_1: 64 Vector__XXX
 SG_ RFC_AEB_TGU_VRU_Obj0_1_CRC : 0|8@1+ (1,0) [0|255] ""  DASy
 SG_ RFC_AEB_TGU_VRU_Obj0_1_MsgCtr : 8|4@1+ (1,0) [0|15] ""  DASy
 SG_ RFC_AEB_TGU_VRU_Obj0_ID : 16|8@1+ (1,0) [0|255] ""  DASy
 SG_ RFC_AEB_TGU_VRU_Obj0_Dx : 24|13@1+ (0.0625,-255.9375) [-255.9375|255.9375] "m"  DASy
 SG_ RFC_AEB_TGU_VRU_Obj0_Vx : 53|11@1+ (0.125,-128) [-128|127.875] "mps"  DASy
 SG_ RFC_AEB_TGU_VRU_Obj0_Ax : 75|10@1+ (0.125,-44.5) [-44.5|44.5] "mps2"  DASy
 SG_ RFC_AEB_TGU_VRU_Obj0_Dy : 40|13@1+ (0.0625,-255.9375) [-255.9375|255.9375] "m"  DASy
 SG_ RFC_AEB_TGU_VRU_Obj0_Vy : 64|11@1+ (0.125,-128) [-128|127.875] "mps"  DASy
 SG_ RFC_AEB_TGU_VRU_Obj0_Ay : 85|10@1+ (0.125,-44.5) [-44.5|44.5] "mps2"  DASy
 SG_ RFC_AEB_TGU_VRU_Obj0_DxStd : 96|8@1+ (0.05,0) [0|12.75] "m"  DASy
 SG_ RFC_AEB_TGU_VRU_Obj0_VxStd : 112|6@1+ (0.2,0) [0|12.6] "mps"  DASy
 SG_ RFC_AEB_TGU_VRU_Obj0_AxStd : 128|5@1+ (0.35,0) [0|10.85] "mps2"  DASy
 SG_ RFC_AEB_TGU_VRU_Obj0_DyStd : 104|8@1+ (0.1,0) [0|25.5] "m"  DASy
 SG_ RFC_AEB_TGU_VRU_Obj0_VyStd : 120|6@1+ (0.2,0) [0|12.6] "mps"  DASy
 SG_ RFC_AEB_TGU_VRU_Obj0_AyStd : 136|5@1+ (0.35,0) [0|10.85] "mps2"  DASy
 SG_ RFC_AEB_TGU_VRU_Obj0_ValidFlag : 141|1@1+ (1,0) [0|1] ""  DASy
 SG_ RFC_AEB_TGU_VRU_Obj0_UpdateFlag : 142|1@1+ (1,0) [0|1] ""  DASy
 SG_ RFC_AEB_TGU_VRU_Obj0_MirProb : 176|7@1+ (1,0) [0|100] "percent"  DASy
 SG_ RFC_AEB_TGU_VRU_Obj0_ObsProb : 144|7@1+ (1,0) [0|100] "percent"  DASy
 SG_ RFC_AEB_TGU_VRU_Obj0_ExistProb : 152|7@1+ (1,0) [0|100] "percent"  DASy
 SG_ RFC_AEB_TGU_VRU_Obj0_Type : 160|4@1+ (1,0) [0|15] ""  DASy
 SG_ RFC_AEB_TGU_VRU_Obj0_EDynProp : 164|4@1+ (1,0) [0|15] ""  DASy
 SG_ RFC_AEB_TGU_VRU_Obj0_UiLifeCyc : 168|7@1+ (1,0) [0|127] ""  DASy
 SG_ RFC_AEB_TGU_VRU_Obj0_RCS : 184|11@1+ (0.1,-100) [-100|100] "dBm"  DASy
 SG_ RFC_AEB_TGU_VRU_Obj0_RFF : 200|8@1+ (1,0) [0|255] ""  DASy
 SG_ RFC_AEB_TGU_VRU_Obj0_Width : 208|16@1- (0.0078125,0) [-256|255.9921875] ""  DASy
 SG_ RFC_AEB_TGU_VRU_Obj1_ID : 232|8@1+ (1,0) [0|255] ""  DASy
 SG_ RFC_AEB_TGU_VRU_Obj1_Dx : 240|13@1+ (0.0625,-255.9375) [-255.9375|255.9375] "m"  DASy
 SG_ RFC_AEB_TGU_VRU_Obj1_Vx : 269|11@1+ (0.125,-128) [-128|127.875] "mps"  DASy
 SG_ RFC_AEB_TGU_VRU_Obj1_Ax : 291|10@1+ (0.125,-44.5) [-44.5|44.5] "mps2"  DASy
 SG_ RFC_AEB_TGU_VRU_Obj1_Dy : 256|13@1+ (0.0625,-255.9375) [-255.9375|255.9375] "m"  DASy
 SG_ RFC_AEB_TGU_VRU_Obj1_Vy : 280|11@1+ (0.125,-128) [-128|127.875] "mps"  DASy
 SG_ RFC_AEB_TGU_VRU_Obj1_Ay : 301|10@1+ (0.125,-44.5) [-44.5|44.5] "mps2"  DASy
 SG_ RFC_AEB_TGU_VRU_Obj1_DxStd : 312|8@1+ (0.05,0) [0|12.75] "m"  DASy
 SG_ RFC_AEB_TGU_VRU_Obj1_VxStd : 328|6@1+ (0.2,0) [0|12.6] "mps"  DASy
 SG_ RFC_AEB_TGU_VRU_Obj1_AxStd : 344|5@1+ (0.35,0) [0|10.85] "mps2"  DASy
 SG_ RFC_AEB_TGU_VRU_Obj1_DyStd : 320|8@1+ (0.1,0) [0|25.5] "m"  DASy
 SG_ RFC_AEB_TGU_VRU_Obj1_VyStd : 336|6@1+ (0.2,0) [0|12.6] "mps"  DASy
 SG_ RFC_AEB_TGU_VRU_Obj1_AyStd : 352|5@1+ (0.35,0) [0|10.85] "mps2"  DASy
 SG_ RFC_AEB_TGU_VRU_Obj1_ValidFlag : 357|1@1+ (1,0) [0|1] ""  DASy
 SG_ RFC_AEB_TGU_VRU_Obj1_UpdateFlag : 358|1@1+ (1,0) [0|1] ""  DASy
 SG_ RFC_AEB_TGU_VRU_Obj1_MirProb : 392|7@1+ (1,0) [0|100] "percent"  DASy
 SG_ RFC_AEB_TGU_VRU_Obj1_ObsProb : 360|7@1+ (1,0) [0|100] "percent"  DASy
 SG_ RFC_AEB_TGU_VRU_Obj1_ExistProb : 368|7@1+ (1,0) [0|100] "percent"  DASy
 SG_ RFC_AEB_TGU_VRU_Obj1_Type : 376|4@1+ (1,0) [0|15] ""  DASy
 SG_ RFC_AEB_TGU_VRU_Obj1_EDynProp : 380|4@1+ (1,0) [0|15] ""  DASy
 SG_ RFC_AEB_TGU_VRU_Obj1_UiLifeCyc : 384|7@1+ (1,0) [0|127] ""  DASy
 SG_ RFC_AEB_TGU_VRU_Obj1_RCS : 400|11@1+ (0.1,-100) [-100|100] "dBm"  DASy
 SG_ RFC_AEB_TGU_VRU_Obj1_RFF : 416|8@1+ (1,0) [0|255] ""  DASy
 SG_ RFC_AEB_TGU_VRU_Obj1_Width : 424|16@1- (0.0078125,0) [-256|255.9921875] ""  DASy

BO_ 368 RFC_AEB_TGU_C2C_Obj0_1: 64 Vector__XXX
 SG_ RFC_AEB_TGU_C2C_Obj0_1_CRC : 0|8@1+ (1,0) [0|255] ""  DASy
 SG_ RFC_AEB_TGU_C2C_Obj0_1_MsgCtr : 8|4@1+ (1,0) [0|15] ""  DASy
 SG_ RFC_AEB_TGU_C2C_Obj0_ID : 16|8@1+ (1,0) [0|255] ""  DASy
 SG_ RFC_AEB_TGU_C2C_Obj0_Dx : 24|13@1+ (0.0625,-255.9375) [-255.9375|255.9375] "m"  DASy
 SG_ RFC_AEB_TGU_C2C_Obj0_Vx : 53|11@1+ (0.125,-128) [-128|127.875] "mps"  DASy
 SG_ RFC_AEB_TGU_C2C_Obj0_Ax : 75|10@1+ (0.125,-44.5) [-44.5|44.5] "mps2"  DASy
 SG_ RFC_AEB_TGU_C2C_Obj0_Dy : 40|13@1+ (0.0625,-255.9375) [-255.9375|255.9375] "m"  DASy
 SG_ RFC_AEB_TGU_C2C_Obj0_Vy : 64|11@1+ (0.125,-128) [-128|127.875] "mps"  DASy
 SG_ RFC_AEB_TGU_C2C_Obj0_Ay : 85|10@1+ (0.125,-44.5) [-44.5|44.5] "mps2"  DASy
 SG_ RFC_AEB_TGU_C2C_Obj0_DxStd : 96|8@1+ (0.05,0) [0|12.75] "m"  DASy
 SG_ RFC_AEB_TGU_C2C_Obj0_VxStd : 112|6@1+ (0.2,0) [0|12.6] "mps"  DASy
 SG_ RFC_AEB_TGU_C2C_Obj0_AxStd : 128|5@1+ (0.35,0) [0|10.85] "mps2"  DASy
 SG_ RFC_AEB_TGU_C2C_Obj0_DyStd : 104|8@1+ (0.1,0) [0|25.5] "m"  DASy
 SG_ RFC_AEB_TGU_C2C_Obj0_VyStd : 120|6@1+ (0.2,0) [0|12.6] "mps"  DASy
 SG_ RFC_AEB_TGU_C2C_Obj0_AyStd : 136|5@1+ (0.35,0) [0|10.85] "mps2"  DASy
 SG_ RFC_AEB_TGU_C2C_Obj0_ValidFlag : 141|1@1+ (1,0) [0|1] ""  DASy
 SG_ RFC_AEB_TGU_C2C_Obj0_UpdateFlag : 142|1@1+ (1,0) [0|1] ""  DASy
 SG_ RFC_AEB_TGU_C2C_Obj0_MirProb : 176|7@1+ (1,0) [0|100] "percent"  DASy
 SG_ RFC_AEB_TGU_C2C_Obj0_ObsProb : 144|7@1+ (1,0) [0|100] "percent"  DASy
 SG_ RFC_AEB_TGU_C2C_Obj0_ExistProb : 152|7@1+ (1,0) [0|100] "percent"  DASy
 SG_ RFC_AEB_TGU_C2C_Obj0_Type : 160|4@1+ (1,0) [0|15] ""  DASy
 SG_ RFC_AEB_TGU_C2C_Obj0_EDynProp : 164|4@1+ (1,0) [0|15] ""  DASy
 SG_ RFC_AEB_TGU_C2C_Obj0_UiLifeCyc : 168|7@1+ (1,0) [0|127] ""  DASy
 SG_ RFC_AEB_TGU_C2C_Obj0_RCS : 184|11@1+ (0.1,-100) [-100|100] "dBm"  DASy
 SG_ RFC_AEB_TGU_C2C_Obj0_RFF : 200|8@1+ (1,0) [0|255] ""  DASy
 SG_ RFC_AEB_TGU_C2C_Obj0_Width : 208|16@1- (0.0078125,0) [-256|255.9921875] ""  DASy
 SG_ RFC_AEB_TGU_C2C_Obj1_ID : 232|8@1+ (1,0) [0|255] ""  DASy
 SG_ RFC_AEB_TGU_C2C_Obj1_Dx : 240|13@1+ (0.0625,-255.9375) [-255.9375|255.9375] "m"  DASy
 SG_ RFC_AEB_TGU_C2C_Obj1_Vx : 269|11@1+ (0.125,-128) [-128|127.875] "mps"  DASy
 SG_ RFC_AEB_TGU_C2C_Obj1_Ax : 291|10@1+ (0.125,-44.5) [-44.5|44.5] "mps2"  DASy
 SG_ RFC_AEB_TGU_C2C_Obj1_Dy : 256|13@1+ (0.0625,-255.9375) [-255.9375|255.9375] "m"  DASy
 SG_ RFC_AEB_TGU_C2C_Obj1_Vy : 280|11@1+ (0.125,-128) [-128|127.875] "mps"  DASy
 SG_ RFC_AEB_TGU_C2C_Obj1_Ay : 301|10@1+ (0.125,-44.5) [-44.5|44.5] "mps2"  DASy
 SG_ RFC_AEB_TGU_C2C_Obj1_DxStd : 312|8@1+ (0.05,0) [0|12.75] "m"  DASy
 SG_ RFC_AEB_TGU_C2C_Obj1_VxStd : 328|6@1+ (0.2,0) [0|12.6] "mps"  DASy
 SG_ RFC_AEB_TGU_C2C_Obj1_AxStd : 344|5@1+ (0.35,0) [0|10.85] "mps2"  DASy
 SG_ RFC_AEB_TGU_C2C_Obj1_DyStd : 320|8@1+ (0.1,0) [0|25.5] "m"  DASy
 SG_ RFC_AEB_TGU_C2C_Obj1_VyStd : 336|6@1+ (0.2,0) [0|12.6] "mps"  DASy
 SG_ RFC_AEB_TGU_C2C_Obj1_AyStd : 352|5@1+ (0.35,0) [0|10.85] "mps2"  DASy
 SG_ RFC_AEB_TGU_C2C_Obj1_ValidFlag : 357|1@1+ (1,0) [0|1] ""  DASy
 SG_ RFC_AEB_TGU_C2C_Obj1_UpdateFlag : 358|1@1+ (1,0) [0|1] ""  DASy
 SG_ RFC_AEB_TGU_C2C_Obj1_MirProb : 392|7@1+ (1,0) [0|100] "percent"  DASy
 SG_ RFC_AEB_TGU_C2C_Obj1_ObsProb : 360|7@1+ (1,0) [0|100] "percent"  DASy
 SG_ RFC_AEB_TGU_C2C_Obj1_ExistProb : 368|7@1+ (1,0) [0|100] "percent"  DASy
 SG_ RFC_AEB_TGU_C2C_Obj1_Type : 376|4@1+ (1,0) [0|15] ""  DASy
 SG_ RFC_AEB_TGU_C2C_Obj1_EDynProp : 380|4@1+ (1,0) [0|15] ""  DASy
 SG_ RFC_AEB_TGU_C2C_Obj1_UiLifeCyc : 384|7@1+ (1,0) [0|127] ""  DASy
 SG_ RFC_AEB_TGU_C2C_Obj1_RCS : 400|11@1+ (0.1,-100) [-100|100] "dBm"  DASy
 SG_ RFC_AEB_TGU_C2C_Obj1_RFF : 416|8@1+ (1,0) [0|255] ""  DASy
 SG_ RFC_AEB_TGU_C2C_Obj1_Width : 424|16@1- (0.0078125,0) [-256|255.9921875] ""  DASy

BO_ 151 VFC_KPI_Check: 8 MPC3
 SG_ VFC_dcLeCollisionProbLow : 0|1@1+ (1,0) [0|1] ""  RadarFrontCenter
 SG_ VFC_CFLeCollisionProbLow : 1|1@1+ (1,0) [0|1] ""  RadarFrontCenter
 SG_ VFC_CRLeCollisionProbLow : 2|1@1+ (1,0) [0|1] ""  RadarFrontCenter
 SG_ VFC_dcRiCollisionProbLow : 3|1@1+ (1,0) [0|1] ""  RadarFrontCenter
 SG_ VFC_HWA_ILCLeftSt : 4|3@1+ (1,0) [0|7] ""  RadarFrontCenter
 SG_ VFC_HWA_ILCRightSt : 8|3@1+ (1,0) [0|7] ""  RadarFrontCenter
 SG_ VFC_CFRiCollisionProbLow : 11|1@1+ (1,0) [0|1] ""  RadarFrontCenter
 SG_ VFC_CRRiCollisionProbLow : 12|1@1+ (1,0) [0|1] ""  RadarFrontCenter
 SG_ VFC_isOriLaneWidthInDefRange : 13|1@1+ (1,0) [0|1] ""  RadarFrontCenter
 SG_ VFC_isLeLaneTypeValidForALC : 14|1@1+ (1,0) [0|1] ""  RadarFrontCenter
 SG_ VFC_isNeiLeLaneWidthInRange : 16|1@1+ (1,0) [0|1] ""  RadarFrontCenter
 SG_ VFC_isDetecDisActCondForNeiLe : 18|1@1+ (1,0) [0|1] ""  RadarFrontCenter
 SG_ VFC_isExiProbActCondNeiLe : 20|1@1+ (1,0) [0|1] ""  RadarFrontCenter
 SG_ VFC_isRiLaneTypeValidForALC : 15|1@1+ (1,0) [0|1] ""  RadarFrontCenter
 SG_ VFC_isNeiRiLaneWidthInRange : 17|1@1+ (1,0) [0|1] ""  RadarFrontCenter
 SG_ VFC_isDetecDisActCondForNeiRi : 19|1@1+ (1,0) [0|1] ""  RadarFrontCenter
 SG_ VFC_isExiProbActCondNeiRi : 21|1@1+ (1,0) [0|1] ""  RadarFrontCenter
 SG_ VFC_isLdwInReactZoneLe : 22|1@1+ (1,0) [0|1] ""  RadarFrontCenter
 SG_ VFC_isLdwInReactZoneRi : 23|1@1+ (1,0) [0|1] ""  RadarFrontCenter
 SG_ VFC_isRdpInReactZoneLe : 24|1@1+ (1,0) [0|1] ""  RadarFrontCenter
 SG_ VFC_isRdpInReactZoneRi : 25|1@1+ (1,0) [0|1] ""  RadarFrontCenter
 SG_ VFC_isELKslInReactZoneLe : 26|1@1+ (1,0) [0|1] ""  RadarFrontCenter
 SG_ VFC_isELKslInReactZoneRi : 27|1@1+ (1,0) [0|1] ""  RadarFrontCenter
 SG_ VFC_isELKoInReactZoneLe : 28|1@1+ (1,0) [0|1] ""  RadarFrontCenter
 SG_ VFC_isELKoInReactZoneRi : 29|1@1+ (1,0) [0|1] ""  RadarFrontCenter
 SG_ VFC_isELKotInReactZoneLe : 30|1@1+ (1,0) [0|1] ""  RadarFrontCenter
 SG_ VFC_isELKotInReactZoneRi : 31|1@1+ (1,0) [0|1] ""  RadarFrontCenter
 SG_ VFC_isELKreInReactZoneLe : 32|1@1+ (1,0) [0|1] ""  RadarFrontCenter
 SG_ VFC_isELKreInReactZoneRi : 33|1@1+ (1,0) [0|1] ""  RadarFrontCenter
 SG_ VFC_DesFinalTraj_Dy : 34|10@1+ (0.01,0) [-3|3] "m"  RadarFrontCenter
 SG_ VFC_DLC : 44|10@1+ (0.01,0) [-3|3] "m"  RadarFrontCenter
 SG_ VFC_LatSpeed : 54|9@1+ (0.01,0) [-1.5|1.5] "m/s"  RadarFrontCenter

BO_ 87 RFC_Modulation_Status: 8 Vector__XXX
 SG_ RFC_Modulation_Status_CRC : 0|8@1+ (1,0) [0|255] ""  RadarFrontRight,RadarFrontLeft,RadarRearLeft,RadarRearRight
 SG_ RFC_Modulation_Status_MsgCtr : 8|4@1+ (1,0) [0|15] ""  RadarFrontRight,RadarFrontLeft,RadarRearLeft,RadarRearRight
 SG_ RFC_RFL_ModState : 14|2@1+ (1,0) [0|3] ""  RadarFrontRight,RadarFrontLeft,RadarRearLeft,RadarRearRight
 SG_ RFC_RFR_ModState : 18|2@1+ (1,0) [0|3] ""  RadarFrontRight,RadarFrontLeft,RadarRearLeft,RadarRearRight
 SG_ RFC_RRL_ModState : 20|2@1+ (1,0) [0|3] ""  RadarFrontRight,RadarFrontLeft,RadarRearLeft,RadarRearRight
 SG_ RFC_RRR_ModState : 22|2@1+ (1,0) [0|3] ""  RadarFrontRight,RadarFrontLeft,RadarRearLeft,RadarRearRight

BO_ 2281601536 Dev_Video_SyncVisor_TX: 8 MPC3
 SG_ ImgTimeDelay : 32|32@1+ (1,0) [0|4294967295] ""  RadarFrontCenter
 SG_ ImgFrameCounter : 0|32@1+ (1,0) [0|4294967295] ""  RadarFrontCenter

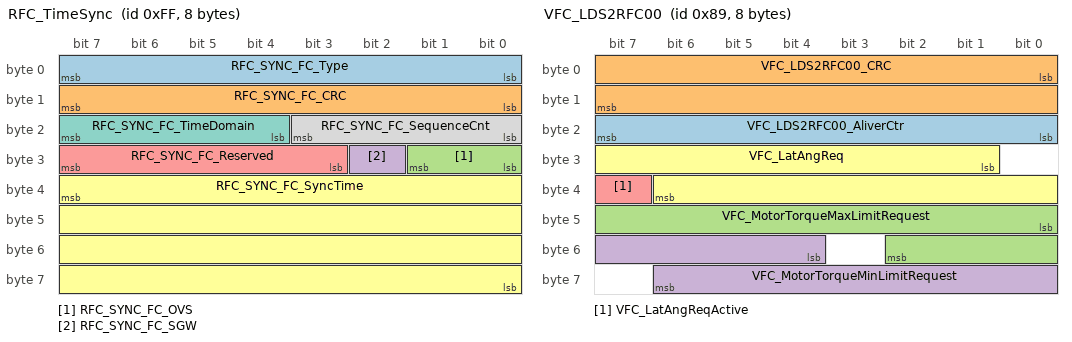
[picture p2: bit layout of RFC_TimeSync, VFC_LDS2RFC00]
BO_ 255 RFC_TimeSync: 8 Vector__XXX
 SG_ RFC_SYNC_FC_Type : 0|8@1+ (1,0) [0|255] ""  RadarFrontSlave,RadarFrontRight,RadarFrontLeft,RadarRearLeft,RadarRearRight
 SG_ RFC_SYNC_FC_CRC : 8|8@1+ (1,0) [0|255] ""  RadarFrontSlave,RadarFrontRight,RadarFrontLeft,RadarRearLeft,RadarRearRight
 SG_ RFC_SYNC_FC_OVS : 24|2@1+ (1,0) [0|3] ""  RadarFrontSlave,RadarFrontRight,RadarFrontLeft,RadarRearLeft,RadarRearRight
 SG_ RFC_SYNC_FC_SGW : 26|1@1+ (1,0) [0|1] ""  RadarFrontSlave,RadarFrontRight,RadarFrontLeft,RadarRearLeft,RadarRearRight
 SG_ RFC_SYNC_FC_Reserved : 27|5@1+ (1,0) [0|31] ""  RadarFrontSlave,RadarFrontRight,RadarFrontLeft,RadarRearLeft,RadarRearRight
 SG_ RFC_SYNC_FC_SyncTime : 39|32@0+ (1,0) [0|4294967295] ""  RadarFrontSlave,RadarFrontRight,RadarFrontLeft,RadarRearLeft,RadarRearRight
 SG_ RFC_SYNC_FC_TimeDomain : 20|4@1+ (1,0) [0|15] ""  RadarFrontSlave,RadarFrontRight,RadarFrontLeft,RadarRearLeft,RadarRearRight
 SG_ RFC_SYNC_FC_SequenceCnt : 16|4@1+ (1,0) [0|15] ""  RadarFrontSlave,RadarFrontRight,RadarFrontLeft,RadarRearLeft,RadarRearRight

BO_ 75 RFC_Fct: 16 RadarFrontCenter
 SG_ RFC_SCF_MFS_Set : 67|1@1+ (1,0) [0|1] ""  MPC3
 SG_ RFC_Fct_CRC : 0|16@1+ (1,0) [0|65535] ""  MPC3
 SG_ RFC_Fct_AliveCtr : 16|8@1+ (1,0) [0|255] ""  MPC3
 SG_ RFC_AEBSts : 24|3@1+ (1,0) [0|7] ""  MPC3
 SG_ RFC_ACCSts : 27|4@1+ (1,0) [0|9] ""  MPC3
 SG_ RFC_ESSSts : 31|3@1+ (1,0) [0|7] ""  MPC3
 SG_ RFC_ToqReq_ESS : 34|11@1+ (0.01,-10.24) [-10.24|10.23] "Nm"  MPC3
 SG_ RFC_ToqReqActive_ESS : 45|1@1+ (1,0) [0|1] ""  MPC3
 SG_ RFC_AngReq_ESS : 46|14@1+ (0.1,-720) [-720|720] "degree"  MPC3
 SG_ RFC_AngReqActive_ESS : 60|1@1+ (1,0) [0|1] ""  MPC3
 SG_ RFC_Stat_Error : 61|1@1+ (1,0) [0|1] ""  MPC3
 SG_ RFC_Stat_ACCSwitchButton : 62|2@1+ (1,0) [0|3] ""  MPC3
 SG_ RFC_Pri_ALOD_ControlType : 64|3@1+ (1,0) [0|7] ""  MPC3

BO_ 137 VFC_LDS2RFC00: 8 MPC3
 SG_ VFC_LDS2RFC00_AliverCtr : 16|8@1+ (1,0) [0|255] ""  RadarFrontCenter
 SG_ VFC_LDS2RFC00_CRC : 0|16@1+ (1,0) [0|65535] ""  RadarFrontCenter
 SG_ VFC_MotorTorqueMaxLimitRequest : 40|11@1+ (0.02,-20.48) [-20.48|20.46] "Nm"  RadarFrontCenter
 SG_ VFC_MotorTorqueMinLimitRequest : 52|11@1+ (0.02,-20.48) [-20.48|20.46] "Nm"  RadarFrontCenter
 SG_ VFC_LatAngReqActive : 39|1@1+ (1,0) [0|1] ""  RadarFrontCenter
 SG_ VFC_LatAngReq : 25|14@1+ (0.1,-720) [-720|720] "degree"  RadarFrontCenter

BO_ 145 VFC_LDS2RFC01: 16 MPC3
 SG_ Selflearning_angle : 72|11@1+ (0.01,-10.25) [-10.25|10.22] "degree"  RadarFrontCenter
 SG_ Selflearning_status : 64|2@1+ (1,0) [0|3] ""  RadarFrontCenter
 SG_ VFC_LDS2RFC01_CRC : 0|16@1+ (1,0) [0|65535] ""  RadarFrontCenter
 SG_ VFC_LDS2RFC01_AliverCtr : 16|8@1+ (1,0) [0|255] ""  RadarFrontCenter
 SG_ VFC_DriverWindowControl : 32|7@1+ (1,0) [0|100] ""  RadarFrontCenter
 SG_ VFC_ToTargetLatDistance : 56|8@1+ (0.1,-10) [-10|10] ""  RadarFrontCenter
 SG_ VFC_LLaneDistanceFusion : 24|7@1+ (0.05,-1) [-1|5] "m"  RadarFrontCenter
 SG_ VFC_SunroofControl : 47|8@1+ (1,0) [0|255] ""  RadarFrontCenter
 SG_ VFC_RLaneDistanceFusion : 40|7@1+ (0.05,-1) [-1|5] "m"  RadarFrontCenter

BO_ 146 VFC_LDS2RFC02: 32 MPC3
 SG_ VFC_EmergencyLightingRequest : 144|2@1+ (1,0) [0|3] ""  RadarFrontCenter
 SG_ VFC_ELKActiveSide : 152|2@1+ (1,0) [0|3] ""  RadarFrontCenter
 SG_ VFC_VFC_LDS2RFC02_CRC : 0|16@1+ (1,0) [0|65535] ""  RadarFrontCenter
 SG_ VFC_VFC_LDS2RFC02_AliverCtr : 16|8@1+ (1,0) [0|255] ""  RadarFrontCenter
 SG_ VFC_LASModeSelectionStatus : 61|3@1+ (1,0) [0|7] ""  RadarFrontCenter
 SG_ VFC_LatTakeoverReq : 88|2@1+ (1,0) [0|3] ""  RadarFrontCenter
 SG_ VFC_HandsOnReq : 39|3@1+ (1,0) [0|7] ""  RadarFrontCenter
 SG_ VFC_RLaneMarkerType : 103|3@1+ (1,0) [0|7] ""  RadarFrontCenter
 SG_ VFC_LaneChangeStatus : 59|2@1+ (1,0) [0|3] ""  RadarFrontCenter
 SG_ VFC_RoadCurvatureFar : 113|7@1+ (0.0005,-0.03) [-0.03|0.03] "1/m"  RadarFrontCenter
 SG_ VFC_RRLaneDistance : 129|6@1+ (0.2,0) [0|12] "m"  RadarFrontCenter
 SG_ VFC_IACCHWAMode : 51|3@1+ (1,0) [0|7] ""  RadarFrontCenter
 SG_ VFC_LASWarningModeSelectionSts : 64|3@1+ (1,0) [0|7] ""  RadarFrontCenter
 SG_ VFC_DriverHandsOffStatus : 24|2@1+ (1,0) [0|3] ""  RadarFrontCenter
 SG_ VFC_IACCHWATextInfoForDriver : 54|5@1+ (1,0) [0|31] ""  RadarFrontCenter
 SG_ VFC_LDWShakeLevStatus : 90|2@1+ (1,0) [0|3] ""  RadarFrontCenter
 SG_ VFC_IACCHWAEnable : 50|1@1+ (1,0) [0|1] ""  RadarFrontCenter
 SG_ VFC_HostLaneLeftStatus : 42|4@1+ (1,0) [0|15] ""  RadarFrontCenter
 SG_ VFC_ELKInterventionMode : 27|2@1+ (1,0) [0|3] ""  RadarFrontCenter
 SG_ VFC_ELKMode : 29|3@1+ (1,0) [0|7] ""  RadarFrontCenter
 SG_ VFC_HostLaneRightStatus : 46|4@1+ (1,0) [0|15] ""  RadarFrontCenter
 SG_ VFC_TargetBasedLateralControl : 135|2@1+ (1,0) [0|3] ""  RadarFrontCenter
 SG_ VFC_HandsoffFuncStatus : 32|3@1+ (1,0) [0|7] ""  RadarFrontCenter
 SG_ VFC_HandsoffFuncTextinfo : 35|4@1+ (1,0) [0|15] ""  RadarFrontCenter
 SG_ VFC_LLaneMarkerType : 92|3@1+ (1,0) [0|7] ""  RadarFrontCenter
 SG_ VFC_ELKEnableStatus : 26|1@1+ (1,0) [0|1] ""  RadarFrontCenter
 SG_ VFC_LLLaneDistance : 97|6@1+ (0.2,0) [0|12] "m"  RadarFrontCenter
 SG_ VFC_LatPathDY : 67|10@1- (0.01,0) [-5|5] "m"  RadarFrontCenter
 SG_ VFC_RoadCurvature : 106|7@1+ (0.0005,-0.03) [-0.03|0.03] "1/m"  RadarFrontCenter
 SG_ VFC_LLLaneDetection : 95|2@1+ (1,0) [0|3] ""  RadarFrontCenter
 SG_ VFC_LatPathHeadingAngle : 77|11@1- (0.1,0) [-90|90] "degree"  RadarFrontCenter
 SG_ VFC_Voiceinfo : 137|5@1+ (1,0) [0|31] ""  RadarFrontCenter
 SG_ VFC_RRLaneDetection : 127|2@1+ (1,0) [0|3] ""  RadarFrontCenter
 SG_ VFC_RoadCurvatureNear : 120|7@1+ (0.0005,-0.03) [-0.03|0.03] "1/m"  RadarFrontCenter

BO_ 147 VFC_LDS2RFC03: 16 MPC3
 SG_ VFC_VFC_LDS2RFC03_CRC : 0|16@1+ (1,0) [0|65535] ""  RadarFrontCenter
 SG_ VFC_VFC_LDS2RFC03_AliverCtr : 16|8@1+ (1,0) [0|255] ""  RadarFrontCenter
 SG_ VFC_LaneQuality : 62|6@1+ (0.015625,0) [0|0.984375] ""  RadarFrontCenter
 SG_ VFC_LaneEquationC1 : 24|12@1+ (0.00048828125,-1) [-1|0.9990234375] "red"  RadarFrontCenter
 SG_ VFC_LaneEquationC2 : 36|12@1+ (1.52587890625E-005,-0.0312347412109375) [-0.0312347412109375|0.0312347412109375] ""  RadarFrontCenter
 SG_ VFC_LaneEquationStatus : 60|2@1+ (1,0) [0|3] ""  RadarFrontCenter
 SG_ VFC_LaneEquationC3 : 48|12@1+ (4.76837158203125E-007,-0.000976085662841797) [-0.000976085662841797|0.000976085662841797] ""  RadarFrontCenter

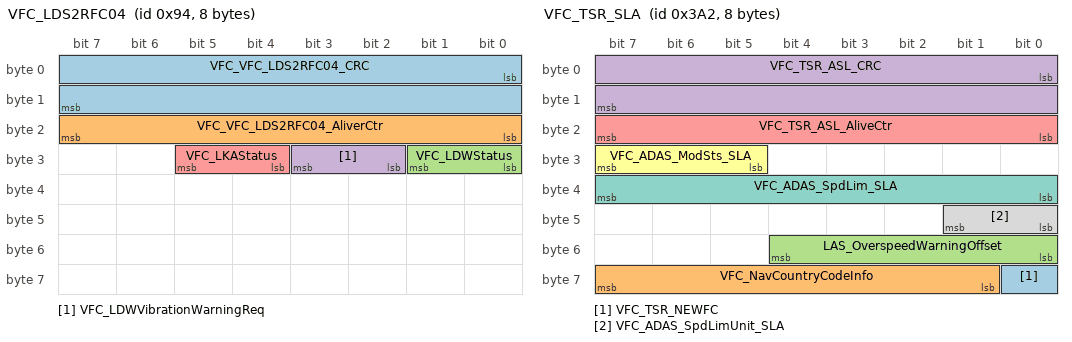
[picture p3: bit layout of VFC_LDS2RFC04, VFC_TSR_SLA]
BO_ 148 VFC_LDS2RFC04: 8 MPC3
 SG_ VFC_VFC_LDS2RFC04_CRC : 0|16@1+ (1,0) [0|65535] ""  RadarFrontCenter
 SG_ VFC_VFC_LDS2RFC04_AliverCtr : 16|8@1+ (1,0) [0|255] ""  RadarFrontCenter
 SG_ VFC_LDWStatus : 24|2@1+ (1,0) [0|3] ""  RadarFrontCenter
 SG_ VFC_LDWVibrationWarningReq : 26|2@1+ (1,0) [0|3] ""  RadarFrontCenter
 SG_ VFC_LKAStatus : 28|2@1+ (1,0) [0|3] ""  RadarFrontCenter

BO_ 149 VFC_CLARA_Test: 12 MPC3
 SG_ VFC_Fct_Status_CRC : 0|16@1+ (1,0) [0|65535] "" Vector__XXX
 SG_ VFC_Fct_Status_AliverCtr : 16|8@1+ (1,0) [0|255] "" Vector__XXX
 SG_ VFC_LDWSt : 24|3@1+ (1,0) [0|7] "" Vector__XXX
 SG_ VFC_RDPSt : 27|3@1+ (1,0) [0|7] "" Vector__XXX
 SG_ VFC_ELKSt_re : 32|3@1+ (1,0) [0|7] "" Vector__XXX
 SG_ VFC_ELKSt_ot : 35|3@1+ (1,0) [0|7] "" Vector__XXX
 SG_ VFC_ELKSt_oc : 40|3@1+ (1,0) [0|7] "" Vector__XXX
 SG_ VFC_ELKSt_sl : 43|3@1+ (1,0) [0|7] "" Vector__XXX
 SG_ VFC_LKSSt : 48|3@1+ (1,0) [0|7] "" Vector__XXX
 SG_ VFC_vehicleReachTargetLane : 51|1@1+ (1,0) [0|1] "" Vector__XXX
 SG_ VFC_isLaneChangeFinished : 52|1@1+ (1,0) [0|1] "" Vector__XXX
 SG_ VFC_inLaneChangeManoeuvre : 53|1@1+ (1,0) [0|1] "" Vector__XXX
 SG_ VFC_isAlcAttentiveHandsOnSt : 54|1@1+ (1,0) [0|1] "" Vector__XXX
 SG_ VFC_laneChangeDirectionChanged : 55|1@1+ (1,0) [0|1] "" Vector__XXX
 SG_ VFC_ILCASysSts : 56|3@1+ (1,0) [0|7] "" Vector__XXX
 SG_ VFC_DirectionIndDisableReq : 59|2@1+ (1,0) [0|2] "" Vector__XXX
 SG_ VFC_OpticalWarningForALC : 61|3@1+ (1,0) [0|7] "" Vector__XXX
 SG_ VFC_HapticWarningForALC : 64|2@1+ (1,0) [0|2] "" Vector__XXX

BO_ 930 VFC_TSR_SLA: 8 MPC3
 SG_ VFC_TSR_NEWFC : 56|1@1+ (1,0) [0|1] ""  RadarFrontCenter
 SG_ VFC_NavCountryCodeInfo : 63|7@0+ (1,0) [0|127] ""  RadarFrontCenter
 SG_ LAS_OverspeedWarningOffset : 48|5@1+ (1,-10) [-10|10] "km/h"  RadarFrontCenter
 SG_ VFC_TSR_ASL_CRC : 0|16@1+ (1,0) [0|65535] ""  RadarFrontCenter
 SG_ VFC_TSR_ASL_AliveCtr : 16|8@1+ (1,0) [0|255] ""  RadarFrontCenter
 SG_ VFC_ADAS_ModSts_SLA : 29|3@1+ (1,0) [0|7] ""  RadarFrontCenter
 SG_ VFC_ADAS_SpdLim_SLA : 32|8@1+ (1,0) [0|255] ""  RadarFrontCenter
 SG_ VFC_ADAS_SpdLimUnit_SLA : 40|2@1+ (1,0) [0|3] ""  RadarFrontCenter

BO_ 929 VFC_TLAObject: 12 MPC3
 SG_ VFC_TLAObject_CRC : 0|16@1+ (1,0) [0|65535] ""  RadarFrontCenter
 SG_ VFC_TLAObject_AliveCtr : 16|8@1+ (1,0) [0|255] ""  RadarFrontCenter
 SG_ VFC_TLAObject_ProtBlockCtr : 24|4@1+ (1,0) [0|15] ""  RadarFrontCenter
 SG_ VFC_TLAObjectColour_LeftLane : 28|2@1+ (1,0) [0|3] "-"  RadarFrontCenter
 SG_ VFC_TLAObjectColour_RightLane : 30|2@1+ (1,0) [0|3] "-"  RadarFrontCenter
 SG_ VFC_TLAObjectColour_HostLane : 32|2@1+ (1,0) [0|3] "-"  RadarFrontCenter
 SG_ VFC_TLAStopLine_HostLane : 36|12@1+ (0.1,0) [0|255] "m"  RadarFrontCenter
 SG_ VFC_TLF_SuggestedDriveAction : 34|2@1+ (1,0) [0|3] "-"  RadarFrontCenter
 SG_ VFC_TLATrafficLightDisLeft : 48|12@1+ (0.1,0) [0|255] "m"  RadarFrontCenter
 SG_ VFC_TLATrafficLightDisRight : 60|12@1+ (0.1,0) [0|255] "m"  RadarFrontCenter
 SG_ VFC_TLATrafficLightDisHost : 72|12@1+ (0.1,0) [0|255] "m"  RadarFrontCenter
 SG_ VFC_VFC_TLAZebraLineDis : 84|12@1+ (0.1,0) [0|255] "m"  RadarFrontCenter

BO_ 273 RFC_TIPLBoundary: 32 RadarFrontCenter
 SG_ RFC_TIPLBoundary_CRC : 0|16@1+ (1,0) [0|65535] ""  MPC3
 SG_ RFC_TIPLBoundary_AliveCtr : 16|8@1+ (1,0) [0|255] ""  MPC3
 SG_ RFC_TIPLBoundary_BlockCtr : 24|4@1+ (1,0) [0|15] ""  MPC3
 SG_ RFC_TIPLBoundary_Type : 29|2@1+ (1,0) [0|3] ""  MPC3
 SG_ RFC_TIPLBoundary_Valid : 28|1@1+ (1,0) [0|1] ""  MPC3
 SG_ RFC_BoundaryLe_Dy : 32|12@1+ (0.015625,-32) [-32|31.984375] "m"  MPC3
 SG_ RFC_BoundaryLe_HeadingAngle : 56|13@1+ (0.000488281,-1.6) [-1.6|1.6] "rad"  MPC3
 SG_ RFC_BoundaryLe_Curvature : 72|13@1+ (3.8147E-006,-0.015625) [-0.015625|0.0156212077] "1/m"  MPC3
 SG_ RFC_BoundaryLe_CurvChange : 44|12@1+ (3.8147E-006,-0.0078125) [-0.0078125|0.0078086965] "1/(m*m)"  MPC3
 SG_ RFC_BoundaryLe_DxEnd : 85|10@1+ (0.25,0) [0|255.75] "m"  MPC3
 SG_ RFC_BoundaryLe_DxStart : 96|13@1+ (0.025,0) [0|204.775] "m"  MPC3
 SG_ RFC_BoundaryRi_Dy : 112|12@1+ (0.015625,-32) [-32|31.984375] "m"  MPC3
 SG_ RFC_BoundaryRi_HeadingAngle : 136|13@1+ (0.000488281,-1.6) [-1.6|1.6] "rad"  MPC3
 SG_ RFC_BoundaryRi_Curvature : 152|13@1+ (3.8147E-006,-0.015625) [-0.015625|0.0156212077] "1/m"  MPC3
 SG_ RFC_BoundaryRi_CurvChange : 124|12@1+ (3.8147E-006,-0.0078125) [-0.0078125|0.0078086965] "1/(m*m)"  MPC3
 SG_ RFC_BoundaryRi_DxEnd : 165|10@1+ (0.25,0) [0|255.75] "m"  MPC3
 SG_ RFC_BoundaryRi_DxStart : 176|13@1+ (0.025,0) [0|204.775] "m"  MPC3

BO_ 288 RFC_OnComingObj0: 32 RadarFrontCenter
 SG_ RFC_OnComingObj0_CRC : 0|8@1+ (1,0) [0|255] ""  MPC3,DASy
 SG_ RFC_OnComingObj0_MsgCtr : 8|4@1+ (1,0) [0|15] ""  MPC3,DASy
 SG_ RFC_OnComingObj0_ID : 16|8@1+ (1,0) [0|255] ""  MPC3,DASy
 SG_ RFC_OnComingObj0_Dx : 24|13@1+ (0.0625,-255.9375) [-255.9375|255.9375] "m"  MPC3,DASy
 SG_ RFC_OnComingObj0_Vx : 53|11@1+ (0.125,-128) [-128|127.875] "mps"  MPC3,DASy
 SG_ RFC_OnComingObj0_Ax : 75|10@1+ (0.125,-44.5) [-44.5|44.5] "mps2"  MPC3,DASy
 SG_ RFC_OnComingObj0_Dy : 40|13@1+ (0.0625,-255.9375) [-255.9375|255.9375] "m"  MPC3,DASy
 SG_ RFC_OnComingObj0_Vy : 64|11@1+ (0.125,-128) [-128|127.875] "mps"  MPC3,DASy
 SG_ RFC_OnComingObj0_Ay : 85|10@1+ (0.125,-44.5) [-44.5|44.5] "mps2"  MPC3,DASy
 SG_ RFC_OnComingObj0_DxStd : 96|8@1+ (0.05,0) [0|12.75] "m"  MPC3,DASy
 SG_ RFC_OnComingObj0_VxStd : 112|6@1+ (0.2,0) [0|12.6] "mps"  MPC3,DASy
 SG_ RFC_OnComingObj0_AxStd : 128|5@1+ (0.35,0) [0|10.85] "mps2"  MPC3,DASy
 SG_ RFC_OnComingObj0_DyStd : 104|8@1+ (0.1,0) [0|25.5] "m"  MPC3,DASy
 SG_ RFC_OnComingObj0_VyStd : 120|6@1+ (0.2,0) [0|12.6] "mps"  MPC3,DASy
 SG_ RFC_OnComingObj0_AyStd : 136|5@1+ (0.35,0) [0|10.85] "mps2"  MPC3,DASy
 SG_ RFC_OnComingObj0_ValidFlag : 141|1@1+ (1,0) [0|1] ""  MPC3,DASy
 SG_ RFC_OnComingObj0_UpdateFlag : 142|1@1+ (1,0) [0|1] ""  MPC3,DASy
 SG_ RFC_OnComingObj0_MirProb : 176|7@1+ (1,0) [0|100] "percent"  MPC3,DASy
 SG_ RFC_OnComingObj0_ObsProb : 144|7@1+ (1,0) [0|100] "percent"  MPC3,DASy
 SG_ RFC_OnComingObj0_ExistProb : 152|7@1+ (1,0) [0|100] "percent"  MPC3,DASy
 SG_ RFC_OnComingObj0_Type : 160|4@1+ (1,0) [0|15] ""  MPC3,DASy
 SG_ RFC_OnComingObj0_EDynProp : 164|4@1+ (1,0) [0|15] ""  MPC3,DASy
 SG_ RFC_OnComingObj0_UiLifeCycles : 168|7@1+ (1,0) [0|127] ""  MPC3,DASy
 SG_ RFC_OnComingObj0_RCS : 184|11@1+ (0.1,-100) [-100|100] "dBm"  MPC3,DASy
 SG_ RFC_OnComingObj0_RFF : 200|8@1+ (1,0) [0|255] ""  MPC3,DASy
 SG_ RFC_OnComingObj0_Width : 208|16@1- (0.0078125,0) [-256|255.9921875] ""  MPC3,DASy

BO_ 289 RFC_OnComingObj1: 32 RadarFrontCenter
 SG_ RFC_OnComingObj1_CRC : 0|8@1+ (1,0) [0|255] ""  MPC3,DASy
 SG_ RFC_OnComingObj1_MsgCtr : 8|4@1+ (1,0) [0|15] ""  MPC3,DASy
 SG_ RFC_OnComingObj1_ID : 16|8@1+ (1,0) [0|255] ""  MPC3,DASy
 SG_ RFC_OnComingObj1_Dx : 24|13@1+ (0.0625,-255.9375) [-255.9375|255.9375] "m"  MPC3,DASy
 SG_ RFC_OnComingObj1_Vx : 53|11@1+ (0.125,-128) [-128|127.875] "mps"  MPC3,DASy
 SG_ RFC_OnComingObj1_Ax : 75|10@1+ (0.125,-44.5) [-44.5|44.5] "mps2"  MPC3,DASy
 SG_ RFC_OnComingObj1_Dy : 40|13@1+ (0.0625,-255.9375) [-255.9375|255.9375] "m"  MPC3,DASy
 SG_ RFC_OnComingObj1_Vy : 64|11@1+ (0.125,-128) [-128|127.875] "mps"  MPC3,DASy
 SG_ RFC_OnComingObj1_Ay : 85|10@1+ (0.125,-44.5) [-44.5|44.5] "mps2"  MPC3,DASy
 SG_ RFC_OnComingObj1_DxStd : 96|8@1+ (0.05,0) [0|12.75] "m"  MPC3,DASy
 SG_ RFC_OnComingObj1_VxStd : 112|6@1+ (0.2,0) [0|12.6] "mps"  MPC3,DASy
 SG_ RFC_OnComingObj1_AxStd : 128|5@1+ (0.35,0) [0|10.85] "mps2"  MPC3,DASy
 SG_ RFC_OnComingObj1_DyStd : 104|8@1+ (0.1,0) [0|25.5] "m"  MPC3,DASy
 SG_ RFC_OnComingObj1_VyStd : 120|6@1+ (0.2,0) [0|12.6] "mps"  MPC3,DASy
 SG_ RFC_OnComingObj1_AyStd : 136|5@1+ (0.35,0) [0|10.85] "mps2"  MPC3,DASy
 SG_ RFC_OnComingObj1_ValidFlag : 141|1@1+ (1,0) [0|1] ""  MPC3,DASy
 SG_ RFC_OnComingObj1_UpdateFlag : 142|1@1+ (1,0) [0|1] ""  MPC3,DASy
 SG_ RFC_OnComingObj1_MirProb : 176|7@1+ (1,0) [0|100] "percent"  MPC3,DASy
 SG_ RFC_OnComingObj1_ObsProb : 144|7@1+ (1,0) [0|100] "percent"  MPC3,DASy
 SG_ RFC_OnComingObj1_ExistProb : 152|7@1+ (1,0) [0|100] "percent"  MPC3,DASy
 SG_ RFC_OnComingObj1_Type : 160|4@1+ (1,0) [0|15] ""  MPC3,DASy
 SG_ RFC_OnComingObj1_EDynProp : 164|4@1+ (1,0) [0|15] ""  MPC3,DASy
 SG_ RFC_OnComingObj1_UiLifeCycles : 168|7@1+ (1,0) [0|127] ""  MPC3,DASy
 SG_ RFC_OnComingObj1_RCS : 184|11@1+ (0.1,-100) [-100|100] "dBm"  MPC3,DASy
 SG_ RFC_OnComingObj1_RFF : 200|8@1+ (1,0) [0|255] ""  MPC3,DASy
 SG_ RFC_OnComingObj1_Width : 208|16@1- (0.0078125,0) [-256|255.9921875] ""  MPC3,DASy

BO_ 292 RFC_OnGoingObj0: 32 RadarFrontCenter
 SG_ RFC_OnGoingObj0_CRC : 0|8@1+ (1,0) [0|255] ""  MPC3,DASy
 SG_ RFC_OnGoingObj0_MsgCtr : 8|4@1+ (1,0) [0|15] ""  MPC3,DASy
 SG_ RFC_OnGoingObj0_ID : 16|8@1+ (1,0) [0|255] ""  MPC3,DASy
 SG_ RFC_OnGoingObj0_Dx : 24|13@1+ (0.0625,-255.9375) [-255.9375|255.9375] "m"  MPC3,DASy
 SG_ RFC_OnGoingObj0_Vx : 53|11@1+ (0.125,-128) [-128|127.875] "mps"  MPC3,DASy
 SG_ RFC_OnGoingObj0_Ax : 75|10@1+ (0.125,-44.5) [-44.5|44.5] "mps2"  MPC3,DASy
 SG_ RFC_OnGoingObj0_Dy : 40|13@1+ (0.0625,-255.9375) [-255.9375|255.9375] "m"  MPC3,DASy
 SG_ RFC_OnGoingObj0_Vy : 64|11@1+ (0.125,-128) [-128|127.875] "mps"  MPC3,DASy
 SG_ RFC_OnGoingObj0_Ay : 85|10@1+ (0.125,-44.5) [-44.5|44.5] "mps2"  MPC3,DASy
 SG_ RFC_OnGoingObj0_DxStd : 96|8@1+ (0.05,0) [0|12.75] "m"  MPC3,DASy
 SG_ RFC_OnGoingObj0_VxStd : 112|6@1+ (0.2,0) [0|12.6] "mps"  MPC3,DASy
 SG_ RFC_OnGoingObj0_AxStd : 128|5@1+ (0.35,0) [0|10.85] "mps2"  MPC3,DASy
 SG_ RFC_OnGoingObj0_DyStd : 104|8@1+ (0.1,0) [0|25.5] "m"  MPC3,DASy
 SG_ RFC_OnGoingObj0_VyStd : 120|6@1+ (0.2,0) [0|12.6] "mps"  MPC3,DASy
 SG_ RFC_OnGoingObj0_AyStd : 136|5@1+ (0.35,0) [0|10.85] "mps2"  MPC3,DASy
 SG_ RFC_OnGoingObj0_ValidFlag : 141|1@1+ (1,0) [0|1] ""  MPC3,DASy
 SG_ RFC_OnGoingObj0_UpdateFlag : 142|1@1+ (1,0) [0|1] ""  MPC3,DASy
 SG_ RFC_OnGoingObj0_MirProb : 176|7@1+ (1,0) [0|100] "percent"  MPC3,DASy
 SG_ RFC_OnGoingObj0_ObsProb : 144|7@1+ (1,0) [0|100] "percent"  MPC3,DASy
 SG_ RFC_OnGoingObj0_ExistProb : 152|7@1+ (1,0) [0|100] "percent"  MPC3,DASy
 SG_ RFC_OnGoingObj0_Type : 160|4@1+ (1,0) [0|15] ""  MPC3,DASy
 SG_ RFC_OnGoingObj0_EDynProp : 164|4@1+ (1,0) [0|15] ""  MPC3,DASy
 SG_ RFC_OnGoingObj0_UiLifeCycles : 168|7@1+ (1,0) [0|127] ""  MPC3,DASy
 SG_ RFC_OnGoingObj0_RCS : 184|11@1+ (0.1,-100) [-100|100] "dBm"  MPC3,DASy
 SG_ RFC_OnGoingObj0_RFF : 200|8@1+ (1,0) [0|255] ""  MPC3,DASy
 SG_ RFC_OnGoingObj0_Width : 208|16@1- (0.0078125,0) [-256|255.9921875] ""  MPC3,DASy

BO_ 293 RFC_OnGoingObj1: 32 RadarFrontCenter
 SG_ RFC_OnGoingObj1_CRC : 0|8@1+ (1,0) [0|255] ""  MPC3,DASy
 SG_ RFC_OnGoingObj1_MsgCtr : 8|4@1+ (1,0) [0|15] ""  MPC3,DASy
 SG_ RFC_OnGoingObj1_ID : 16|8@1+ (1,0) [0|255] ""  MPC3,DASy
 SG_ RFC_OnGoingObj1_Dx : 24|13@1+ (0.0625,-255.9375) [-255.9375|255.9375] "m"  MPC3,DASy
 SG_ RFC_OnGoingObj1_Vx : 53|11@1+ (0.125,-128) [-128|127.875] "mps"  MPC3,DASy
 SG_ RFC_OnGoingObj1_Ax : 75|10@1+ (0.125,-44.5) [-44.5|44.5] "mps2"  MPC3,DASy
 SG_ RFC_OnGoingObj1_Dy : 40|13@1+ (0.0625,-255.9375) [-255.9375|255.9375] "m"  MPC3,DASy
 SG_ RFC_OnGoingObj1_Vy : 64|11@1+ (0.125,-128) [-128|127.875] "mps"  MPC3,DASy
 SG_ RFC_OnGoingObj1_Ay : 85|10@1+ (0.125,-44.5) [-44.5|44.5] "mps2"  MPC3,DASy
 SG_ RFC_OnGoingObj1_DxStd : 96|8@1+ (0.05,0) [0|12.75] "m"  MPC3,DASy
 SG_ RFC_OnGoingObj1_VxStd : 112|6@1+ (0.2,0) [0|12.6] "mps"  MPC3,DASy
 SG_ RFC_OnGoingObj1_AxStd : 128|5@1+ (0.35,0) [0|10.85] "mps2"  MPC3,DASy
 SG_ RFC_OnGoingObj1_DyStd : 104|8@1+ (0.1,0) [0|25.5] "m"  MPC3,DASy
 SG_ RFC_OnGoingObj1_VyStd : 120|6@1+ (0.2,0) [0|12.6] "mps"  MPC3,DASy
 SG_ RFC_OnGoingObj1_AyStd : 136|5@1+ (0.35,0) [0|10.85] "mps2"  MPC3,DASy
 SG_ RFC_OnGoingObj1_ValidFlag : 141|1@1+ (1,0) [0|1] ""  MPC3,DASy
 SG_ RFC_OnGoingObj1_UpdateFlag : 142|1@1+ (1,0) [0|1] ""  MPC3,DASy
 SG_ RFC_OnGoingObj1_MirProb : 176|7@1+ (1,0) [0|100] "percent"  MPC3,DASy
 SG_ RFC_OnGoingObj1_ObsProb : 144|7@1+ (1,0) [0|100] "percent"  MPC3,DASy
 SG_ RFC_OnGoingObj1_ExistProb : 152|7@1+ (1,0) [0|100] "percent"  MPC3,DASy
 SG_ RFC_OnGoingObj1_Type : 160|4@1+ (1,0) [0|15] ""  MPC3,DASy
 SG_ RFC_OnGoingObj1_EDynProp : 164|4@1+ (1,0) [0|15] ""  MPC3,DASy
 SG_ RFC_OnGoingObj1_UiLifeCycles : 168|7@1+ (1,0) [0|127] ""  MPC3,DASy
 SG_ RFC_OnGoingObj1_RCS : 184|11@1+ (0.1,-100) [-100|100] "dBm"  MPC3,DASy
 SG_ RFC_OnGoingObj1_RFF : 200|8@1+ (1,0) [0|255] ""  MPC3,DASy
 SG_ RFC_OnGoingObj1_Width : 208|16@1- (0.0078125,0) [-256|255.9921875] ""  MPC3,DASy

BO_ 80 VFC_GlobalHdr: 32 MPC3
 SG_ VFC_GlobalHdr_CRC : 0|16@1+ (1,0) [0|65535] ""  RadarFrontCenter,DASy
 SG_ VFC_GlobalHdr_AliveCtr : 16|8@1+ (1,0) [0|255] ""  RadarFrontCenter,DASy
 SG_ VFC_GlobalHdr_SensorState : 24|3@1+ (1,0) [0|7] ""  RadarFrontCenter,DASy
 SG_ VFC_GlobalHdr_CalibState : 27|3@1+ (1,0) [0|7] ""  RadarFrontCenter,DASy
 SG_ VFC_GlobalHdr_TimeStamp : 30|26@1+ (1,0) [0|67108863] "ms"  RadarFrontCenter,DASy
 SG_ VFC_GlobalHdr_ProtocolVersion : 64|16@1+ (1,0) [0|65535] ""  RadarFrontCenter,DASy
 SG_ VFC_GlobalHdr_FrameNumber : 80|16@1+ (1,0) [0|65535] ""  RadarFrontCenter,DASy
 SG_ VFC_GlobalHdr_SwVersion : 96|20@1+ (0.01,0) [0|9999.99] ""  RadarFrontCenter,DASy
 SG_ VFC_GlobalHdr_MountPosY : 116|12@1+ (0.001,-2.048) [-2.048|2.047] "m"  RadarFrontCenter,DASy
 SG_ VFC_GlobalHdr_MountPosX : 128|13@1+ (0.001,-4.096) [-4.096|4.095] "m"  RadarFrontCenter,DASy
 SG_ VFC_GlobalHdr_MountPosZ : 141|13@1+ (0.001,0) [0|5] "m"  RadarFrontCenter,DASy
 SG_ VFC_GlobalHdr_CalYawAngle : 154|10@1+ (0.0005,-0.256) [-0.256|0.2555] "rad"  RadarFrontCenter,DASy
 SG_ VFC_GlobalHdr_CalPitchAngle : 164|10@1+ (0.0005,-0.256) [-0.256|0.2555] "rad"  RadarFrontCenter,DASy
 SG_ VFC_GlobalHdr_CalRollAngle : 174|10@1+ (0.0005,-0.256) [-0.256|0.2555] "rad"  RadarFrontCenter,DASy
 SG_ VFC_GlobalHdr_CalYawStdDev : 192|9@1+ (0.0005,0) [0|0.2555] "rad"  RadarFrontCenter,DASy
 SG_ VFC_GlobalHdr_CalPitchStdDev : 201|9@1+ (0.0005,0) [0|0.2555] "rad"  RadarFrontCenter,DASy
 SG_ VFC_GlobalHdr_CalRollStdDev : 210|9@1+ (0.0005,0) [0|0.2555] "rad"  RadarFrontCenter,DASy
 SG_ VFC_GlobalHdr_TimeLatency : 224|16@1+ (1,0) [0|65535] "ms"  RadarFrontCenter,DASy

CM_ BO_ 3221225472 "This is a message for not used signals, created by Vector CANdb++ DBC OLE DB Provider.";
CM_ SG_ 3221225472 VFC_Left_Confidence "left line exist prob. range : 0~1";
CM_ SG_ 3221225472 VFC_Left_DxEnd " left line dx end";
CM_ SG_ 3221225472 VFC_Left_Dy "left line dy";
CM_ SG_ 3221225472 VFC_Left_Curv " left line curvature";
CM_ SG_ 3221225472 VFC_Left_CurvChange " left line curvature change rate";
CM_ SG_ 3221225472 VFC_Left_HeadingAngle "left line heading angle";
CM_ SG_ 3221225472 VFC_Left_Type "left line type";
CM_ SG_ 3221225472 VFC_Left_ID "left line ID(id for tracking each individual clothoid, not a constant), range: 0~255, 0 means line missing";
CM_ SG_ 3221225472 VFC_Right_Confidence "right line exist prob. range : 0~1";
CM_ SG_ 3221225472 VFC_Right_DxEnd " right line dx end";
CM_ SG_ 3221225472 VFC_Right_Dy "right line dy";
CM_ SG_ 3221225472 VFC_Right_Curv " right line curvature";
CM_ SG_ 3221225472 VFC_Right_CurvChange " right line curvature change rate";
CM_ SG_ 3221225472 VFC_Right_HeadingAngle "right line heading angle";
CM_ SG_ 3221225472 VFC_Right_Type "right line type";
CM_ SG_ 3221225472 VFC_Right_ID "right line ID(id for tracking each individual clothoid, not a constant), range: 0~255, 0 means line missing";
CM_ SG_ 3221225472 VFC_LeftLe_Confidence "left adjacent line exist prob. range : 0~1";
CM_ SG_ 3221225472 VFC_LeftLe_DxEnd " left adjacent line dx end";
CM_ SG_ 3221225472 VFC_LeftLe_Dy "left adjacent line dy";
CM_ SG_ 3221225472 VFC_LeftLe_Curv " left adjacent line curvature";
CM_ SG_ 3221225472 VFC_LeftLe_CurvChange " left adjacent line curvature change rate";
CM_ SG_ 3221225472 VFC_LeftLe_HeadingAngle "left adjacent line heading angle";
CM_ SG_ 3221225472 VFC_LeftLe_Type "left adjacent line type";
CM_ SG_ 3221225472 VFC_LeftLe_ID "left adjacent line ID(id for tracking each individual clothoid, not a constant), range: 0~255, 0 means line missing";
CM_ SG_ 3221225472 VFC_RightRi_Confidence "right adjacent line exist prob. range : 0~1";
CM_ SG_ 3221225472 VFC_RightRi_DxEnd "right adjacent line dx end";
CM_ SG_ 3221225472 VFC_RightRi_Dy "right adjacent line dy";
CM_ SG_ 3221225472 VFC_RightRi_Curv " right adjacent line curvature";
CM_ SG_ 3221225472 VFC_RightRi_CurvChange "right adjacent line curvature change rate";
CM_ SG_ 3221225472 VFC_RightRi_HeadingAngle "right line heading angle";
CM_ SG_ 3221225472 VFC_RightRi_Type "right adjacentt line type";
CM_ SG_ 3221225472 VFC_RightRi_ID "right adjacent line ID(id for tracking each individual clothoid, not a constant), range: 0~255, 0 means line missing";
CM_ SG_ 3221225472 RFC_ACC_TGU_Hdr_CRC "Crc_CalculateCRC8";
CM_ SG_ 3221225472 RFC_ACCObjInfo1_CRC "Crc_Calculate CRC8 SAE J1850";
CM_ SG_ 3221225472 RFC_OnGoingObj3_CRC "Crc_Calculate CRC8 SAE J1850";
CM_ SG_ 3221225472 RFC_OnGoingObj2_CRC "Crc_Calculate CRC8 SAE J1850";
CM_ SG_ 3221225472 RRR_ObjHdr_CRC "CRC - Autosar E2E Profile 5 - Not Required for Demo";
CM_ SG_ 3221225472 RRR_ObjHdr_AliveCtr "Alive counter - Autosar E2E Profile 5 - Not Required for Demo";
CM_ SG_ 3221225472 RRR_ObjHdr_ProtBlockCtr "Blockcounter";
CM_ SG_ 3221225472 RRR_ObjHdr_TimeLatency "Absolute time gap, i.e. latency, between measurement time (DSP) and sending time (COM)";
CM_ SG_ 3221225472 RRR_ObjHdr_TimeStampStatus "Autosar StbM_TimeBaseStatusType bitfield with extension";
CM_ SG_ 3221225472 RRR_ObjHdr_TimeStamp "AUTOSAR Time Stamp";
CM_ SG_ 3221225472 RRL_ObjHdr_CRC "CRC - Autosar E2E Profile 5 - Not Required for Demo";
CM_ SG_ 3221225472 RRL_ObjHdr_AliveCtr "Alive counter - Autosar E2E Profile 5 - Not Required for Demo";
CM_ SG_ 3221225472 RRL_ObjHdr_ProtBlockCtr "Blockcounter";
CM_ SG_ 3221225472 RRL_ObjHdr_TimeLatency "Absolute time gap, i.e. latency, between measurement time (DSP) and sending time (COM)";
CM_ SG_ 3221225472 RRL_ObjHdr_TimeStampStatus "Autosar StbM_TimeBaseStatusType bitfield with extension";
CM_ SG_ 3221225472 RRL_ObjHdr_TimeStamp "AUTOSAR Time Stamp";
CM_ SG_ 3221225472 RFR_ObjHdr_CRC "CRC - Autosar E2E Profile 5 - Not Required for Demo";
CM_ SG_ 3221225472 RFR_ObjHdr_AliveCtr "Alive counter - Autosar E2E Profile 5 - Not Required for Demo";
CM_ SG_ 3221225472 RFR_ObjHdr_ProtBlockCtr "Blockcounter";
CM_ SG_ 3221225472 RFR_ObjHdr_TimeLatency "Absolute time gap, i.e. latency, between measurement time (DSP) and sending time (COM)";
CM_ SG_ 3221225472 RFR_ObjHdr_TimeStampStatus "Autosar StbM_TimeBaseStatusType bitfield with extension";
CM_ SG_ 3221225472 RFR_ObjHdr_TimeStamp "AUTOSAR Time Stamp";
CM_ SG_ 3221225472 RFL_ObjHdr_CRC "CRC - Autosar E2E Profile 5 - Not Required for Demo";
CM_ SG_ 3221225472 RFL_ObjHdr_AliveCtr "Alive counter - Autosar E2E Profile 5 - Not Required for Demo";
CM_ SG_ 3221225472 RFL_ObjHdr_ProtBlockCtr "Blockcounter";
CM_ SG_ 3221225472 RFL_ObjHdr_TimeLatency "Absolute time gap, i.e. latency, between measurement time (DSP) and sending time (COM)";
CM_ SG_ 3221225472 RFL_ObjHdr_TimeStampStatus "Autosar StbM_TimeBaseStatusType bitfield with extension";
CM_ SG_ 3221225472 RFL_ObjHdr_TimeStamp "AUTOSAR Time Stamp";
CM_ SG_ 3221225472 VFC_SafeSearch_ALC_CRC "Crc_CalculateCRC8";
CM_ SG_ 3221225472 VFC_SafeSearch_ALC_MsgCtr "Alive Counter";
CM_ SG_ 3221225472 RFC_Evaluator_ALC_CRC "Crc_CalculateCRC8";
CM_ SG_ 3221225472 RFC_Evaluator_ALC_MsgCtr "Alive Counter";
CM_ SG_ 3221225472 LaneChangeLeft_collision_prob "Collision probability of objects detected by FR and Video(on ego lane and left target lane)";
CM_ SG_ 3221225472 LaneChangeLeft_recommendation "Left lane-change recommemdation evaluated by target trajectory and ego vehicle motion";
CM_ SG_ 3221225472 LaneChangeRight_collision_prob "Collision probability of objects detected by FR and Video(on ego lane and right target lane)";
CM_ SG_ 3221225472 LaneChangeRight_recommendation "Right lane-change recommemdation evaluated by target trajectory and ego vehicle motion";
CM_ SG_ 3221225472 CRObj_evaluator_axd_valid "represent whether safe area is active";
CM_ SG_ 3221225472 CRObj_evaluator_axc_valid "represent whether accelerating LC is active";
CM_ SG_ 3221225472 FLObj_evaluator_feasibility "feasibility on front left side based on objects detected by CR";
CM_ SG_ 3221225472 FRObj_evaluator_feasibility "feasibility on front right side based on objects detected by CR";
CM_ SG_ 3221225472 RLObj_evaluator_feasibility "feasibility on rear left side based on objects detected by CR";
CM_ SG_ 3221225472 RRObj_evaluator_feasibility "feasibility on rear right side based on objects detected by CR";
CM_ SG_ 3221225472 RFC_ALC_CR_invalid "The Indicator to characterize invalidation of CR objects mapped to FID of CR_Invalid_Indicator";
CM_ SG_ 3221225472 RFL_Status_CRC "Crc_CalculateCRC8";
CM_ SG_ 3221225472 RFL_Status_MsgCtr "Alive Counter";
CM_ SG_ 3221225472 RFL_Modulation_Status "Indicate the modulation state of each corner radar";
CM_ SG_ 3221225472 RFL_Status_SensorState "Operation state of Front left corner radar.";
CM_ SG_ 3221225472 RFR_Status_CRC "Crc_CalculateCRC8";
CM_ SG_ 3221225472 RFR_Status_MsgCtr "Alive Counter";
CM_ SG_ 3221225472 RFR_Modulation_Status "Indicate the modulation state of each corner radar";
CM_ SG_ 3221225472 RFR_Status_SensorState "Operation state of Front right corner radar.";
CM_ SG_ 3221225472 RRL_Status_CRC "Crc_CalculateCRC8";
CM_ SG_ 3221225472 RRL_Status_MsgCtr "Alive Counter";
CM_ SG_ 3221225472 RRL_Status_SensorState "Operation state of Rear left corner radar.";
CM_ SG_ 3221225472 RRL_Modulation_Status "Indicate the modulation state of each corner radar";
CM_ SG_ 3221225472 RRR_Status_CRC "Crc_CalculateCRC8";
CM_ SG_ 3221225472 RRR_Status_MsgCtr "Alive Counter";
CM_ SG_ 3221225472 RRR_Status_SensorState "Operation state of Rear right corner radar.";
CM_ SG_ 3221225472 RRR_Modulation_Status "Indicate the modulation state of each corner radar";
CM_ SG_ 3221225472 RFL_Obj00_01_CRC "CRC - Autosar E2E Profile 5 - Not Required for Demo";
CM_ SG_ 3221225472 RFL_Obj00_01_AliveCtr "Alive counter - Autosar E2E Profile 5 - Not Required for Demo";
CM_ SG_ 3221225472 RFL_Obj00_01_ProtBlockCtr "Blockcounter";
CM_ SG_ 3221225472 RFL_Obj00_RefPosIndex "Reference Position of the detected objects";
CM_ SG_ 3221225472 RFL_Obj00_Dx "Object position in X direction";
CM_ SG_ 3221225472 RFL_Obj00_Dy "Object position in Y direction";
CM_ SG_ 3221225472 RFL_Obj00_DxVnce "Variance of object position in X direction";
CM_ SG_ 3221225472 RFL_Obj00_DyVnce "Variance of object position in Y direction";
CM_ SG_ 3221225472 RFL_Obj00_Vx "Object relative velocity in X direction";
CM_ SG_ 3221225472 RFL_Obj00_WidthVnce "Variance of object Width";
CM_ SG_ 3221225472 RFL_Obj00_Width "Object Width";
CM_ SG_ 3221225472 RFL_Obj00_Valid "Object is valid or not";
CM_ SG_ 3221225472 RFL_Obj00_ID "Unique Object ID";
CM_ SG_ 3221225472 RFL_Obj00_Length "Object Length";
CM_ SG_ 3221225472 RFL_Obj00_MovingObserved "Object has been observed moving over the ground since it was first detected";
CM_ SG_ 3221225472 RFL_Obj00_MovingProbability "Object has been observed moving over the ground";
CM_ SG_ 3221225472 RFL_Obj01_RefPosIndex "Reference Position of the detected objects";
CM_ SG_ 3221225472 RFL_Obj01_Dx "Object position in X direction";
CM_ SG_ 3221225472 RFL_Obj01_Dy "Object position in Y direction";
CM_ SG_ 3221225472 RFL_Obj01_DxVnce "Variance of object position in X direction";
CM_ SG_ 3221225472 RFL_Obj01_DyVnce "Variance of object position in Y direction";
CM_ SG_ 3221225472 RFL_Obj01_Vx "Object relative velocity in X direction";
CM_ SG_ 3221225472 RFL_Obj01_WidthVnce "Variance of object Width";
CM_ SG_ 3221225472 RFL_Obj01_Width "Object Width";
CM_ SG_ 3221225472 RFL_Obj01_Valid "Object is valid or not";
CM_ SG_ 3221225472 RFL_Obj01_ID "Unique Object ID";
CM_ SG_ 3221225472 RFL_Obj01_Length "Object Length";
CM_ SG_ 3221225472 RFL_Obj01_MovingObserved "Object has been observed moving over the ground since it was first detected";
CM_ SG_ 3221225472 RFL_Obj01_MovingProbability "Object has been observed moving over the ground";
CM_ SG_ 3221225472 RFL_Obj02_03_CRC "CRC - Autosar E2E Profile 5 - Not Required for Demo";
CM_ SG_ 3221225472 RFL_Obj02_03_AliveCtr "Alive counter - Autosar E2E Profile 5 - Not Required for Demo";
CM_ SG_ 3221225472 RFL_Obj02_03_ProtBlockCtr "Blockcounter";
CM_ SG_ 3221225472 RFL_Obj02_RefPosIndex "Reference Position of the detected objects";
CM_ SG_ 3221225472 RFL_Obj02_Dx "Object position in X direction";
CM_ SG_ 3221225472 RFL_Obj02_Dy "Object position in Y direction";
CM_ SG_ 3221225472 RFL_Obj02_DxVnce "Variance of object position in X direction";
CM_ SG_ 3221225472 RFL_Obj02_DyVnce "Variance of object position in Y direction";
CM_ SG_ 3221225472 RFL_Obj02_Vx "Object relative velocity in X direction";
CM_ SG_ 3221225472 RFL_Obj02_WidthVnce "Variance of object Width";
CM_ SG_ 3221225472 RFL_Obj02_Width "Object Width";
CM_ SG_ 3221225472 RFL_Obj02_Valid "Object is valid or not";
CM_ SG_ 3221225472 RFL_Obj02_ID "Unique Object ID";
CM_ SG_ 3221225472 RFL_Obj02_Length "Object Length";
CM_ SG_ 3221225472 RFL_Obj02_MovingObserved "Object has been observed moving over the ground since it was first detected";
CM_ SG_ 3221225472 RFL_Obj02_MovingProbability "Object has been observed moving over the ground";
CM_ SG_ 3221225472 RFL_Obj03_RefPosIndex "Reference Position of the detected objects";
CM_ SG_ 3221225472 RFL_Obj03_Dx "Object position in X direction";
CM_ SG_ 3221225472 RFL_Obj03_Dy "Object position in Y direction";
CM_ SG_ 3221225472 RFL_Obj03_DxVnce "Variance of object position in X direction";
CM_ SG_ 3221225472 RFL_Obj03_DyVnce "Variance of object position in Y direction";
CM_ SG_ 3221225472 RFL_Obj03_Vx "Object relative velocity in X direction";
CM_ SG_ 3221225472 RFL_Obj03_WidthVnce "Variance of object Width";
CM_ SG_ 3221225472 RFL_Obj03_Width "Object Width";
CM_ SG_ 3221225472 RFL_Obj03_Valid "Object is valid or not";
CM_ SG_ 3221225472 RFL_Obj03_ID "Unique Object ID";
CM_ SG_ 3221225472 RFL_Obj03_Length "Object Length";
CM_ SG_ 3221225472 RFL_Obj03_MovingObserved "Object has been observed moving over the ground since it was first detected";
CM_ SG_ 3221225472 RFL_Obj03_MovingProbability "Object has been observed moving over the ground";
CM_ SG_ 3221225472 RFL_Obj04_05_CRC "CRC - Autosar E2E Profile 5 - Not Required for Demo";
CM_ SG_ 3221225472 RFL_Obj04_05_AliveCtr "Alive counter - Autosar E2E Profile 5 - Not Required for Demo";
CM_ SG_ 3221225472 RFL_Obj04_05_ProtBlockCtr "Blockcounter";
CM_ SG_ 3221225472 RFL_Obj04_RefPosIndex "Reference Position of the detected objects";
CM_ SG_ 3221225472 RFL_Obj04_Dx "Object position in X direction";
CM_ SG_ 3221225472 RFL_Obj04_Dy "Object position in Y direction";
CM_ SG_ 3221225472 RFL_Obj04_DxVnce "Variance of object position in X direction";
CM_ SG_ 3221225472 RFL_Obj04_DyVnce "Variance of object position in Y direction";
CM_ SG_ 3221225472 RFL_Obj04_Vx "Object relative velocity in X direction";
CM_ SG_ 3221225472 RFL_Obj04_WidthVnce "Variance of object Width";
CM_ SG_ 3221225472 RFL_Obj04_Width "Object Width";
CM_ SG_ 3221225472 RFL_Obj04_Valid "Object is valid or not";
CM_ SG_ 3221225472 RFL_Obj04_ID "Unique Object ID";
CM_ SG_ 3221225472 RFL_Obj04_Length "Object Length";
CM_ SG_ 3221225472 RFL_Obj04_MovingObserved "Object has been observed moving over the ground since it was first detected";
CM_ SG_ 3221225472 RFL_Obj04_MovingProbability "Object has been observed moving over the ground";
CM_ SG_ 3221225472 RFL_Obj05_RefPosIndex "Reference Position of the detected objects";
CM_ SG_ 3221225472 RFL_Obj05_Dx "Object position in X direction";
CM_ SG_ 3221225472 RFL_Obj05_Dy "Object position in Y direction";
CM_ SG_ 3221225472 RFL_Obj05_DxVnce "Variance of object position in X direction";
CM_ SG_ 3221225472 RFL_Obj05_DyVnce "Variance of object position in Y direction";
CM_ SG_ 3221225472 RFL_Obj05_Vx "Object relative velocity in X direction";
CM_ SG_ 3221225472 RFL_Obj05_WidthVnce "Variance of object Width";
CM_ SG_ 3221225472 RFL_Obj05_Width "Object Width";
CM_ SG_ 3221225472 RFL_Obj05_Valid "Object is valid or not";
CM_ SG_ 3221225472 RFL_Obj05_ID "Unique Object ID";
CM_ SG_ 3221225472 RFL_Obj05_Length "Object Length";
CM_ SG_ 3221225472 RFL_Obj05_MovingObserved "Object has been observed moving over the ground since it was first detected";
CM_ SG_ 3221225472 RFL_Obj05_MovingProbability "Object has been observed moving over the ground";
CM_ SG_ 3221225472 RFR_Obj00_01_CRC "CRC - Autosar E2E Profile 5 - Not Required for Demo";
CM_ SG_ 3221225472 RFR_Obj00_01_AliveCtr "Alive counter - Autosar E2E Profile 5 - Not Required for Demo";
CM_ SG_ 3221225472 RFR_Obj00_01_ProtBlockCtr "Blockcounter";
CM_ SG_ 3221225472 RFR_Obj00_RefPosIndex "Reference Position of the detected objects";
CM_ SG_ 3221225472 RFR_Obj00_Dx "Object position in X direction";
CM_ SG_ 3221225472 RFR_Obj00_Dy "Object position in Y direction";
CM_ SG_ 3221225472 RFR_Obj00_DxVnce "Variance of object position in X direction";
CM_ SG_ 3221225472 RFR_Obj00_DyVnce "Variance of object position in Y direction";
CM_ SG_ 3221225472 RFR_Obj00_Vx "Object relative velocity in X direction";
CM_ SG_ 3221225472 RFR_Obj00_WidthVnce "Variance of object Width";
CM_ SG_ 3221225472 RFR_Obj00_Width "Object Width";
CM_ SG_ 3221225472 RFR_Obj00_Valid "Object is valid or not";
CM_ SG_ 3221225472 RFR_Obj00_ID "Unique Object ID";
CM_ SG_ 3221225472 RFR_Obj00_Length "Object Length";
CM_ SG_ 3221225472 RFR_Obj00_MovingObserved "Object has been observed moving over the ground since it was first detected";
CM_ SG_ 3221225472 RFR_Obj00_MovingProbability "Object has been observed moving over the ground";
CM_ SG_ 3221225472 RFR_Obj01_RefPosIndex "Reference Position of the detected objects";
CM_ SG_ 3221225472 RFR_Obj01_Dx "Object position in X direction";
CM_ SG_ 3221225472 RFR_Obj01_Dy "Object position in Y direction";
CM_ SG_ 3221225472 RFR_Obj01_DxVnce "Variance of object position in X direction";
CM_ SG_ 3221225472 RFR_Obj01_DyVnce "Variance of object position in Y direction";
CM_ SG_ 3221225472 RFR_Obj01_Vx "Object relative velocity in X direction";
CM_ SG_ 3221225472 RFR_Obj01_WidthVnce "Variance of object Width";
CM_ SG_ 3221225472 RFR_Obj01_Width "Object Width";
CM_ SG_ 3221225472 RFR_Obj01_Valid "Object is valid or not";
CM_ SG_ 3221225472 RFR_Obj01_ID "Unique Object ID";
CM_ SG_ 3221225472 RFR_Obj01_Length "Object Length";
CM_ SG_ 3221225472 RFR_Obj01_MovingObserved "Object has been observed moving over the ground since it was first detected";
CM_ SG_ 3221225472 RFR_Obj01_MovingProbability "Object has been observed moving over the ground";
CM_ SG_ 3221225472 RFR_Obj02_03_CRC "CRC - Autosar E2E Profile 5 - Not Required for Demo";
CM_ SG_ 3221225472 RFR_Obj02_03_AliveCtr "Alive counter - Autosar E2E Profile 5 - Not Required for Demo";
CM_ SG_ 3221225472 RFR_Obj02_03_ProtBlockCtr "Blockcounter";
CM_ SG_ 3221225472 RFR_Obj02_RefPosIndex "Reference Position of the detected objects";
CM_ SG_ 3221225472 RFR_Obj02_Dx "Object position in X direction";
CM_ SG_ 3221225472 RFR_Obj02_Dy "Object position in Y direction";
CM_ SG_ 3221225472 RFR_Obj02_DxVnce "Variance of object position in X direction";
CM_ SG_ 3221225472 RFR_Obj02_DyVnce "Variance of object position in Y direction";
CM_ SG_ 3221225472 RFR_Obj02_Vx "Object relative velocity in X direction";
CM_ SG_ 3221225472 RFR_Obj02_WidthVnce "Variance of object Width";
CM_ SG_ 3221225472 RFR_Obj02_Width "Object Width";
CM_ SG_ 3221225472 RFR_Obj02_Valid "Object is valid or not";
CM_ SG_ 3221225472 RFR_Obj02_ID "Unique Object ID";
CM_ SG_ 3221225472 RFR_Obj02_Length "Object Length";
CM_ SG_ 3221225472 RFR_Obj02_MovingObserved "Object has been observed moving over the ground since it was first detected";
CM_ SG_ 3221225472 RFR_Obj02_MovingProbability "Object has been observed moving over the ground";
CM_ SG_ 3221225472 RFR_Obj03_RefPosIndex "Reference Position of the detected objects";
CM_ SG_ 3221225472 RFR_Obj03_Dx "Object position in X direction";
CM_ SG_ 3221225472 RFR_Obj03_Dy "Object position in Y direction";
CM_ SG_ 3221225472 RFR_Obj03_DxVnce "Variance of object position in X direction";
CM_ SG_ 3221225472 RFR_Obj03_DyVnce "Variance of object position in Y direction";
CM_ SG_ 3221225472 RFR_Obj03_Vx "Object relative velocity in X direction";
CM_ SG_ 3221225472 RFR_Obj03_WidthVnce "Variance of object Width";
CM_ SG_ 3221225472 RFR_Obj03_Width "Object Width";
CM_ SG_ 3221225472 RFR_Obj03_Valid "Object is valid or not";
CM_ SG_ 3221225472 RFR_Obj03_ID "Unique Object ID";
CM_ SG_ 3221225472 RFR_Obj03_Length "Object Length";
CM_ SG_ 3221225472 RFR_Obj03_MovingObserved "Object has been observed moving over the ground since it was first detected";
CM_ SG_ 3221225472 RFR_Obj03_MovingProbability "Object has been observed moving over the ground";
CM_ SG_ 3221225472 RFR_Obj04_05_CRC "CRC - Autosar E2E Profile 5 - Not Required for Demo";
CM_ SG_ 3221225472 RFR_Obj04_05_AliveCtr "Alive counter - Autosar E2E Profile 5 - Not Required for Demo";
CM_ SG_ 3221225472 RFR_Obj04_05_ProtBlockCtr "Blockcounter";
CM_ SG_ 3221225472 RFR_Obj04_RefPosIndex "Reference Position of the detected objects";
CM_ SG_ 3221225472 RFR_Obj04_Dx "Object position in X direction";
CM_ SG_ 3221225472 RFR_Obj04_Dy "Object position in Y direction";
CM_ SG_ 3221225472 RFR_Obj04_DxVnce "Variance of object position in X direction";
CM_ SG_ 3221225472 RFR_Obj04_DyVnce "Variance of object position in Y direction";
CM_ SG_ 3221225472 RFR_Obj04_Vx "Object relative velocity in X direction";
CM_ SG_ 3221225472 RFR_Obj04_WidthVnce "Variance of object Width";
CM_ SG_ 3221225472 RFR_Obj04_Width "Object Width";
CM_ SG_ 3221225472 RFR_Obj04_Valid "Object is valid or not";
CM_ SG_ 3221225472 RFR_Obj04_ID "Unique Object ID";
CM_ SG_ 3221225472 RFR_Obj04_Length "Object Length";
CM_ SG_ 3221225472 RFR_Obj04_MovingObserved "Object has been observed moving over the ground since it was first detected";
CM_ SG_ 3221225472 RFR_Obj04_MovingProbability "Object has been observed moving over the ground";
CM_ SG_ 3221225472 RFR_Obj05_RefPosIndex "Reference Position of the detected objects";
CM_ SG_ 3221225472 RFR_Obj05_Dx "Object position in X direction";
CM_ SG_ 3221225472 RFR_Obj05_Dy "Object position in Y direction";
CM_ SG_ 3221225472 RFR_Obj05_DxVnce "Variance of object position in X direction";
CM_ SG_ 3221225472 RFR_Obj05_DyVnce "Variance of object position in Y direction";
CM_ SG_ 3221225472 RFR_Obj05_Vx "Object relative velocity in X direction";
CM_ SG_ 3221225472 RFR_Obj05_WidthVnce "Variance of object Width";
CM_ SG_ 3221225472 RFR_Obj05_Width "Object Width";
CM_ SG_ 3221225472 RFR_Obj05_Valid "Object is valid or not";
CM_ SG_ 3221225472 RFR_Obj05_ID "Unique Object ID";
CM_ SG_ 3221225472 RFR_Obj05_Length "Object Length";
CM_ SG_ 3221225472 RFR_Obj05_MovingObserved "Object has been observed moving over the ground since it was first detected";
CM_ SG_ 3221225472 RFR_Obj05_MovingProbability "Object has been observed moving over the ground";
CM_ SG_ 3221225472 RRL_Obj00_01_CRC "CRC - Autosar E2E Profile 5 - Not Required for Demo";
CM_ SG_ 3221225472 RRL_Obj00_01_AliveCtr "Alive counter - Autosar E2E Profile 5 - Not Required for Demo";
CM_ SG_ 3221225472 RRL_Obj00_01_ProtBlockCtr "Blockcounter";
CM_ SG_ 3221225472 RRL_Obj00_RefPosIndex "Reference Position of the detected objects";
CM_ SG_ 3221225472 RRL_Obj00_Dx "Object position in X direction";
CM_ SG_ 3221225472 RRL_Obj00_Dy "Object position in Y direction";
CM_ SG_ 3221225472 RRL_Obj00_DxVnce "Variance of object position in X direction";
CM_ SG_ 3221225472 RRL_Obj00_DyVnce "Variance of object position in Y direction";
CM_ SG_ 3221225472 RRL_Obj00_Vx "Object relative velocity in X direction";
CM_ SG_ 3221225472 RRL_Obj00_WidthVnce "Variance of object Width";
CM_ SG_ 3221225472 RRL_Obj00_Width "Object Width";
CM_ SG_ 3221225472 RRL_Obj00_Valid "Object is valid or not";
CM_ SG_ 3221225472 RRL_Obj00_ID "Unique Object ID";
CM_ SG_ 3221225472 RRL_Obj00_Length "Object Length";
CM_ SG_ 3221225472 RRL_Obj00_MovingObserved "Object has been observed moving over the ground since it was first detected";
CM_ SG_ 3221225472 RRL_Obj00_MovingProbability "Object has been observed moving over the ground";
CM_ SG_ 3221225472 RRL_Obj01_RefPosIndex "Reference Position of the detected objects";
CM_ SG_ 3221225472 RRL_Obj01_Dx "Object position in X direction";
CM_ SG_ 3221225472 RRL_Obj01_Dy "Object position in Y direction";
CM_ SG_ 3221225472 RRL_Obj01_DxVnce "Variance of object position in X direction";
CM_ SG_ 3221225472 RRL_Obj01_DyVnce "Variance of object position in Y direction";
CM_ SG_ 3221225472 RRL_Obj01_Vx "Object relative velocity in X direction";
CM_ SG_ 3221225472 RRL_Obj01_WidthVnce "Variance of object Width";
CM_ SG_ 3221225472 RRL_Obj01_Width "Object Width";
CM_ SG_ 3221225472 RRL_Obj01_Valid "Object is valid or not";
CM_ SG_ 3221225472 RRL_Obj01_ID "Unique Object ID";
CM_ SG_ 3221225472 RRL_Obj01_Length "Object Length";
CM_ SG_ 3221225472 RRL_Obj01_MovingObserved "Object has been observed moving over the ground since it was first detected";
CM_ SG_ 3221225472 RRL_Obj01_MovingProbability "Object has been observed moving over the ground";
CM_ SG_ 3221225472 RRL_Obj02_03_CRC "CRC - Autosar E2E Profile 5 - Not Required for Demo";
CM_ SG_ 3221225472 RRL_Obj02_03_AliveCtr "Alive counter - Autosar E2E Profile 5 - Not Required for Demo";
CM_ SG_ 3221225472 RRL_Obj02_03_ProtBlockCtr "Blockcounter";
CM_ SG_ 3221225472 RRL_Obj02_RefPosIndex "Reference Position of the detected objects";
CM_ SG_ 3221225472 RRL_Obj02_Dx "Object position in X direction";
CM_ SG_ 3221225472 RRL_Obj02_Dy "Object position in Y direction";
CM_ SG_ 3221225472 RRL_Obj02_DxVnce "Variance of object position in X direction";
CM_ SG_ 3221225472 RRL_Obj02_DyVnce "Variance of object position in Y direction";
CM_ SG_ 3221225472 RRL_Obj02_Vx "Object relative velocity in X direction";
CM_ SG_ 3221225472 RRL_Obj02_WidthVnce "Variance of object Width";
CM_ SG_ 3221225472 RRL_Obj02_Width "Object Width";
CM_ SG_ 3221225472 RRL_Obj02_Valid "Object is valid or not";
CM_ SG_ 3221225472 RRL_Obj02_ID "Unique Object ID";
CM_ SG_ 3221225472 RRL_Obj02_Length "Object Length";
CM_ SG_ 3221225472 RRL_Obj02_MovingObserved "Object has been observed moving over the ground since it was first detected";
CM_ SG_ 3221225472 RRL_Obj02_MovingProbability "Object has been observed moving over the ground";
CM_ SG_ 3221225472 RRL_Obj03_RefPosIndex "Reference Position of the detected objects";
CM_ SG_ 3221225472 RRL_Obj03_Dx "Object position in X direction";
CM_ SG_ 3221225472 RRL_Obj03_Dy "Object position in Y direction";
CM_ SG_ 3221225472 RRL_Obj03_DxVnce "Variance of object position in X direction";
CM_ SG_ 3221225472 RRL_Obj03_DyVnce "Variance of object position in Y direction";
CM_ SG_ 3221225472 RRL_Obj03_Vx "Object relative velocity in X direction";
CM_ SG_ 3221225472 RRL_Obj03_WidthVnce "Variance of object Width";
CM_ SG_ 3221225472 RRL_Obj03_Width "Object Width";
CM_ SG_ 3221225472 RRL_Obj03_Valid "Object is valid or not";
CM_ SG_ 3221225472 RRL_Obj03_ID "Unique Object ID";
CM_ SG_ 3221225472 RRL_Obj03_Length "Object Length";
CM_ SG_ 3221225472 RRL_Obj03_MovingObserved "Object has been observed moving over the ground since it was first detected";
CM_ SG_ 3221225472 RRL_Obj03_MovingProbability "Object has been observed moving over the ground";
CM_ SG_ 3221225472 RRL_Obj04_05_CRC "CRC - Autosar E2E Profile 5 - Not Required for Demo";
CM_ SG_ 3221225472 RRL_Obj04_05_AliveCtr "Alive counter - Autosar E2E Profile 5 - Not Required for Demo";
CM_ SG_ 3221225472 RRL_Obj04_05_ProtBlockCtr "Blockcounter";
CM_ SG_ 3221225472 RRL_Obj04_RefPosIndex "Reference Position of the detected objects";
CM_ SG_ 3221225472 RRL_Obj04_Dx "Object position in X direction";
CM_ SG_ 3221225472 RRL_Obj04_Dy "Object position in Y direction";
CM_ SG_ 3221225472 RRL_Obj04_DxVnce "Variance of object position in X direction";
CM_ SG_ 3221225472 RRL_Obj04_DyVnce "Variance of object position in Y direction";
CM_ SG_ 3221225472 RRL_Obj04_Vx "Object relative velocity in X direction";
CM_ SG_ 3221225472 RRL_Obj04_WidthVnce "Variance of object Width";
CM_ SG_ 3221225472 RRL_Obj04_Width "Object Width";
CM_ SG_ 3221225472 RRL_Obj04_Valid "Object is valid or not";
CM_ SG_ 3221225472 RRL_Obj04_ID "Unique Object ID";
CM_ SG_ 3221225472 RRL_Obj04_Length "Object Length";
CM_ SG_ 3221225472 RRL_Obj04_MovingObserved "Object has been observed moving over the ground since it was first detected";
CM_ SG_ 3221225472 RRL_Obj04_MovingProbability "Object has been observed moving over the ground";
CM_ SG_ 3221225472 RRL_Obj05_RefPosIndex "Reference Position of the detected objects";
CM_ SG_ 3221225472 RRL_Obj05_Dx "Object position in X direction";
CM_ SG_ 3221225472 RRL_Obj05_Dy "Object position in Y direction";
CM_ SG_ 3221225472 RRL_Obj05_DxVnce "Variance of object position in X direction";
CM_ SG_ 3221225472 RRL_Obj05_DyVnce "Variance of object position in Y direction";
CM_ SG_ 3221225472 RRL_Obj05_Vx "Object relative velocity in X direction";
CM_ SG_ 3221225472 RRL_Obj05_WidthVnce "Variance of object Width";
CM_ SG_ 3221225472 RRL_Obj05_Width "Object Width";
CM_ SG_ 3221225472 RRL_Obj05_Valid "Object is valid or not";
CM_ SG_ 3221225472 RRL_Obj05_ID "Unique Object ID";
CM_ SG_ 3221225472 RRL_Obj05_Length "Object Length";
CM_ SG_ 3221225472 RRL_Obj05_MovingObserved "Object has been observed moving over the ground since it was first detected";
CM_ SG_ 3221225472 RRL_Obj05_MovingProbability "Object has been observed moving over the ground";
CM_ SG_ 3221225472 RRR_Obj00_01_CRC "CRC - Autosar E2E Profile 5 - Not Required for Demo";
CM_ SG_ 3221225472 RRR_Obj00_01_AliveCtr "Alive counter - Autosar E2E Profile 5 - Not Required for Demo";
CM_ SG_ 3221225472 RRR_Obj00_01_ProtBlockCtr "Blockcounter";
CM_ SG_ 3221225472 RRR_Obj00_RefPosIndex "Reference Position of the detected objects";
CM_ SG_ 3221225472 RRR_Obj00_Dx "Object position in X direction";
CM_ SG_ 3221225472 RRR_Obj00_Dy "Object position in Y direction";
CM_ SG_ 3221225472 RRR_Obj00_DxVnce "Variance of object position in X direction";
CM_ SG_ 3221225472 RRR_Obj00_DyVnce "Variance of object position in Y direction";
CM_ SG_ 3221225472 RRR_Obj00_Vx "Object relative velocity in X direction";
CM_ SG_ 3221225472 RRR_Obj00_WidthVnce "Variance of object Width";
CM_ SG_ 3221225472 RRR_Obj00_Width "Object Width";
CM_ SG_ 3221225472 RRR_Obj00_Valid "Object is valid or not";
CM_ SG_ 3221225472 RRR_Obj00_ID "Unique Object ID";
CM_ SG_ 3221225472 RRR_Obj00_Length "Object Length";
CM_ SG_ 3221225472 RRR_Obj00_MovingObserved "Object has been observed moving over the ground since it was first detected";
CM_ SG_ 3221225472 RRR_Obj00_MovingProbability "Object has been observed moving over the ground";
CM_ SG_ 3221225472 RRR_Obj01_RefPosIndex "Reference Position of the detected objects";
CM_ SG_ 3221225472 RRR_Obj01_Dx "Object position in X direction";
CM_ SG_ 3221225472 RRR_Obj01_Dy "Object position in Y direction";
CM_ SG_ 3221225472 RRR_Obj01_DxVnce "Variance of object position in X direction";
CM_ SG_ 3221225472 RRR_Obj01_DyVnce "Variance of object position in Y direction";
CM_ SG_ 3221225472 RRR_Obj01_Vx "Object relative velocity in X direction";
CM_ SG_ 3221225472 RRR_Obj01_WidthVnce "Variance of object Width";
CM_ SG_ 3221225472 RRR_Obj01_Width "Object Width";
CM_ SG_ 3221225472 RRR_Obj01_Valid "Object is valid or not";
CM_ SG_ 3221225472 RRR_Obj01_ID "Unique Object ID";
CM_ SG_ 3221225472 RRR_Obj01_Length "Object Length";
CM_ SG_ 3221225472 RRR_Obj01_MovingObserved "Object has been observed moving over the ground since it was first detected";
CM_ SG_ 3221225472 RRR_Obj01_MovingProbability "Object has been observed moving over the ground";
CM_ SG_ 3221225472 RRR_Obj02_03_CRC "CRC - Autosar E2E Profile 5 - Not Required for Demo";
CM_ SG_ 3221225472 RRR_Obj02_03_AliveCtr "Alive counter - Autosar E2E Profile 5 - Not Required for Demo";
CM_ SG_ 3221225472 RRR_Obj02_03_ProtBlockCtr "Blockcounter";
CM_ SG_ 3221225472 RRR_Obj02_RefPosIndex "Reference Position of the detected objects";
CM_ SG_ 3221225472 RRR_Obj02_Dx "Object position in X direction";
CM_ SG_ 3221225472 RRR_Obj02_Dy "Object position in Y direction";
CM_ SG_ 3221225472 RRR_Obj02_DxVnce "Variance of object position in X direction";
CM_ SG_ 3221225472 RRR_Obj02_DyVnce "Variance of object position in Y direction";
CM_ SG_ 3221225472 RRR_Obj02_Vx "Object relative velocity in X direction";
CM_ SG_ 3221225472 RRR_Obj02_WidthVnce "Variance of object Width";
CM_ SG_ 3221225472 RRR_Obj02_Width "Object Width";
CM_ SG_ 3221225472 RRR_Obj02_Valid "Object is valid or not";
CM_ SG_ 3221225472 RRR_Obj02_ID "Unique Object ID";
CM_ SG_ 3221225472 RRR_Obj02_Length "Object Length";
CM_ SG_ 3221225472 RRR_Obj02_MovingObserved "Object has been observed moving over the ground since it was first detected";
CM_ SG_ 3221225472 RRR_Obj02_MovingProbability "Object has been observed moving over the ground";
CM_ SG_ 3221225472 RRR_Obj03_RefPosIndex "Reference Position of the detected objects";
CM_ SG_ 3221225472 RRR_Obj03_Dx "Object position in X direction";
CM_ SG_ 3221225472 RRR_Obj03_Dy "Object position in Y direction";
CM_ SG_ 3221225472 RRR_Obj03_DxVnce "Variance of object position in X direction";
CM_ SG_ 3221225472 RRR_Obj03_DyVnce "Variance of object position in Y direction";
CM_ SG_ 3221225472 RRR_Obj03_Vx "Object relative velocity in X direction";
CM_ SG_ 3221225472 RRR_Obj03_WidthVnce "Variance of object Width";
CM_ SG_ 3221225472 RRR_Obj03_Width "Object Width";
CM_ SG_ 3221225472 RRR_Obj03_Valid "Object is valid or not";
CM_ SG_ 3221225472 RRR_Obj03_ID "Unique Object ID";
CM_ SG_ 3221225472 RRR_Obj03_Length "Object Length";
CM_ SG_ 3221225472 RRR_Obj03_MovingObserved "Object has been observed moving over the ground since it was first detected";
CM_ SG_ 3221225472 RRR_Obj03_MovingProbability "Object has been observed moving over the ground";
CM_ SG_ 3221225472 RRR_Obj04_05_CRC "CRC - Autosar E2E Profile 5 - Not Required for Demo";
CM_ SG_ 3221225472 RRR_Obj04_05_AliveCtr "Alive counter - Autosar E2E Profile 5 - Not Required for Demo";
CM_ SG_ 3221225472 RRR_Obj04_05_ProtBlockCtr "Blockcounter";
CM_ SG_ 3221225472 RRR_Obj04_RefPosIndex "Reference Position of the detected objects";
CM_ SG_ 3221225472 RRR_Obj04_Dx "Object position in X direction";
CM_ SG_ 3221225472 RRR_Obj04_Dy "Object position in Y direction";
CM_ SG_ 3221225472 RRR_Obj04_DxVnce "Variance of object position in X direction";
CM_ SG_ 3221225472 RRR_Obj04_DyVnce "Variance of object position in Y direction";
CM_ SG_ 3221225472 RRR_Obj04_Vx "Object relative velocity in X direction";
CM_ SG_ 3221225472 RRR_Obj04_WidthVnce "Variance of object Width";
CM_ SG_ 3221225472 RRR_Obj04_Width "Object Width";
CM_ SG_ 3221225472 RRR_Obj04_Valid "Object is valid or not";
CM_ SG_ 3221225472 RRR_Obj04_ID "Unique Object ID";
CM_ SG_ 3221225472 RRR_Obj04_Length "Object Length";
CM_ SG_ 3221225472 RRR_Obj04_MovingObserved "Object has been observed moving over the ground since it was first detected";
CM_ SG_ 3221225472 RRR_Obj04_MovingProbability "Object has been observed moving over the ground";
CM_ SG_ 3221225472 RRR_Obj05_RefPosIndex "Reference Position of the detected objects";
CM_ SG_ 3221225472 RRR_Obj05_Dx "Object position in X direction";
CM_ SG_ 3221225472 RRR_Obj05_Dy "Object position in Y direction";
CM_ SG_ 3221225472 RRR_Obj05_DxVnce "Variance of object position in X direction";
CM_ SG_ 3221225472 RRR_Obj05_DyVnce "Variance of object position in Y direction";
CM_ SG_ 3221225472 RRR_Obj05_Vx "Object relative velocity in X direction";
CM_ SG_ 3221225472 RRR_Obj05_WidthVnce "Variance of object Width";
CM_ SG_ 3221225472 RRR_Obj05_Width "Object Width";
CM_ SG_ 3221225472 RRR_Obj05_Valid "Object is valid or not";
CM_ SG_ 3221225472 RRR_Obj05_ID "Unique Object ID";
CM_ SG_ 3221225472 RRR_Obj05_Length "Object Length";
CM_ SG_ 3221225472 RRR_Obj05_MovingObserved "Object has been observed moving over the ground since it was first detected";
CM_ SG_ 3221225472 RRR_Obj05_MovingProbability "Object has been observed moving over the ground";
CM_ SG_ 360 RFC_AEB_TGU_Hdr_CRC "Crc_CalculateCRC8";
CM_ SG_ 340 RFC_ACCObjInfo0_CRC "Crc_Calculate CRC8 SAE J1850";
CM_ SG_ 340 RFC_ACCObjInfo0_MsgCtr "Alive Counter";
CM_ SG_ 340 RFC_ACCObjInfo0_ID "PER fus handle of the object";
CM_ SG_ 340 RFC_ACCObjInfo0_Dx "longitudinal distance, relative to ego";
CM_ SG_ 340 RFC_ACCObjInfo0_Vx "longitudinal velocity, relative to ego";
CM_ SG_ 340 RFC_ACCObjInfo0_Dy "lateral distance, relative to ego";
CM_ SG_ 340 RFC_ACCObjInfo0_RFF "the object is fused with video(1) or radar only(0)";
CM_ SG_ 340 RFC_ACCObjInfo0_Width "width of object";
CM_ SG_ 361 RFC_AEB_TGU_AEBP_Obj_CRC "Crc_Calculate CRC8 SAE J1850";
CM_ SG_ 370 RFC_AEB_TGU_Turn_Obj0_1_CRC "Crc_Calculate CRC8 SAE J1850";
CM_ SG_ 369 RFC_AEB_TGU_VRU_Obj0_1_CRC "Crc_Calculate CRC8 SAE J1850";
CM_ SG_ 368 RFC_AEB_TGU_C2C_Obj0_1_CRC "Crc_Calculate CRC8 SAE J1850";
CM_ BO_ 151 "Transmit by MPC3 without receivers for KPI checking of lateral feature ";
CM_ SG_ 151 VFC_isLdwInReactZoneLe " represent if vehicle is in left reaction zone of LDW";
CM_ SG_ 151 VFC_isLdwInReactZoneRi " represent if vehicle is in right reaction zone of LDW";
CM_ SG_ 151 VFC_isRdpInReactZoneLe "represent if vehicle is in left reaction zone of RDP";
CM_ SG_ 151 VFC_isRdpInReactZoneRi "represent if vehicle is in right reaction zone of RDP";
CM_ SG_ 151 VFC_isELKslInReactZoneLe "represent if vehicle is in left reaction zone of ELKsl";
CM_ SG_ 151 VFC_isELKslInReactZoneRi "represent if vehicle is in right reaction zone of ELKsl";
CM_ SG_ 151 VFC_isELKoInReactZoneLe " represent if vehicle is in left reaction zone of ELKo";
CM_ SG_ 151 VFC_isELKoInReactZoneRi "represent if vehicle is in right reaction zone of ELKo";
CM_ SG_ 151 VFC_isELKotInReactZoneLe "represent if vehicle is in left reaction zone of ELKot";
CM_ SG_ 151 VFC_isELKotInReactZoneRi "represent if vehicle is in right reaction zone of ELKot";
CM_ SG_ 151 VFC_isELKreInReactZoneLe "represent if vehicle is in left reaction zone of ELKre";
CM_ SG_ 151 VFC_isELKreInReactZoneRi "represent if vehicle is in right reaction zone of ELKre";
CM_ SG_ 151 VFC_DesFinalTraj_Dy " dy deviation of target trajectory";
CM_ SG_ 151 VFC_DLC "distance between front tire and lane boundary";
CM_ SG_ 151 VFC_LatSpeed " lateral speed of ego vehicle";
CM_ SG_ 87 RFC_Modulation_Status_CRC "Crc_CalculateCRC8";
CM_ BO_ 255 "AUTOSAR Time Sync Only used for FR Endurance Run";
CM_ SG_ 255 RFC_SYNC_FC_Type "Type=0x20 : TSync    Type=0x28 : TSync FUP";
CM_ SG_ 255 RFC_SYNC_FC_CRC "Crc_CalculateCRC8";
CM_ SG_ 255 RFC_SYNC_FC_OVS "in FUP PDU OVS = Overflow of seconds";
CM_ SG_ 255 RFC_SYNC_FC_SGW "in FUP PDU SyncToGTM = 0 SyncToSubDomain = 1";
CM_ SG_ 255 RFC_SYNC_FC_Reserved "in FUP PDU reserved, default =0";
CM_ SG_ 255 RFC_SYNC_FC_SyncTime "TSync: SyncTimeSec = 32 bit LSB of the 48 bits seconds part of the timeTSync FUP: SyncTimeNSec = 32 Bit time value in nanoseconds";
CM_ SG_ 255 RFC_SYNC_FC_TimeDomain "Time Domain";
CM_ SG_ 255 RFC_SYNC_FC_SequenceCnt "Sequence counter";
CM_ SG_ 75 RFC_Fct_CRC "CRC - Autosar E2E Profile 5";
CM_ SG_ 75 RFC_Fct_AliveCtr "Alive counter - Autosar E2E Profile 5";
CM_ SG_ 75 RFC_ACCSts "Autonomous Emergency Braking Deceleration Request Value";
CM_ SG_ 75 RFC_ESSSts "Adaptive Cruise Control Autonomous Emergency Braking Brake Jerk Level Request";
CM_ SG_ 75 RFC_Stat_Error "FR5CP Error State mapped to FID of FR_Error_Indicator";
CM_ SG_ 75 RFC_Pri_ALOD_ControlType "TJA/ICA Hard Switch";
CM_ SG_ 137 VFC_LDS2RFC00_AliverCtr "Alive counter - Autosar E2E Profile 5";
CM_ SG_ 137 VFC_LDS2RFC00_CRC "CRC - Autosar E2E Profile 5";
CM_ SG_ 137 VFC_MotorTorqueMaxLimitRequest "Maximum torque limit of EPS motor";
CM_ SG_ 137 VFC_MotorTorqueMinLimitRequest "EPS motor torque minimum limit";
CM_ SG_ 137 VFC_LatAngReqActive "Steering angle request (steering wheel end)";
CM_ SG_ 137 VFC_LatAngReq "Steering angle request activation 0x384A-3FFF=Reserved";
CM_ SG_ 145 Selflearning_angle "Selflearning_angle Values";
CM_ SG_ 145 Selflearning_status "Self learning Status";
CM_ SG_ 145 VFC_LDS2RFC01_CRC "CRC - Autosar E2E Profile 5";
CM_ SG_ 145 VFC_LDS2RFC01_AliverCtr "Alive counter - Autosar E2E Profile 5";
CM_ SG_ 145 VFC_DriverWindowControl "Main driving window control;
0x1~0x65= 0%~100% (???????);
0x66-0x7F= Reserved";
CM_ SG_ 145 VFC_ToTargetLatDistance "Real-time horizontal distance from target location;???????????,???????????";
CM_ SG_ 145 VFC_LLaneDistanceFusion "Distance from vehicle center to left lane line;0x0-0x78=-1-5;
0x79-0x7F=reserved;";
CM_ SG_ 145 VFC_SunroofControl "Skylight control;0x1~0x65=sunroof 0%~100%
0x67~0xCB=sunshade 0%~100%(???)";
CM_ SG_ 145 VFC_RLaneDistanceFusion "Distance from vehicle center to right lane line;0x0-0x78=-1-5;0x79-0x7F=reserved;";
CM_ SG_ 146 VFC_VFC_LDS2RFC02_CRC "CRC - Autosar E2E Profile 5";
CM_ SG_ 146 VFC_VFC_LDS2RFC02_AliverCtr "Alive counter - Autosar E2E Profile 5";
CM_ SG_ 146 VFC_LASModeSelectionStatus "LAS mode selection signal status";
CM_ SG_ 146 VFC_LatTakeoverReq "Horizontal takeover request";
CM_ SG_ 146 VFC_HandsOnReq "handsOn request";
CM_ SG_ 146 VFC_RLaneMarkerType "Right lane line type";
CM_ SG_ 146 VFC_LaneChangeStatus "Lane change";
CM_ SG_ 146 VFC_RoadCurvatureFar "Road curvature 80m ahead;0x0-0x78=-0.03-0.03;
0x79-0x7F=reserved;";
CM_ SG_ 146 VFC_RRLaneDistance "Distance from the center of the vehicle to the lane line on the right and right:0x0~0x3c=0-12;0x3D~0x3F=reserved";
CM_ SG_ 146 VFC_IACCHWAMode "ACC_IACCHWAMode";
CM_ SG_ 146 VFC_LASWarningModeSelectionSts "LAS warning mode status";
CM_ SG_ 146 VFC_DriverHandsOffStatus "Driver disengagement";
CM_ SG_ 146 VFC_IACCHWATextInfoForDriver "IACC driver information prompt";
CM_ SG_ 146 VFC_LDWShakeLevStatus "LDW vibration intensity status";
CM_ SG_ 146 VFC_IACCHWAEnable "IACC/HWA enable switch status";
CM_ SG_ 146 VFC_HostLaneLeftStatus "Lane status on the right side of this lane0x9~0xF=reserved";
CM_ SG_ 146 VFC_ELKInterventionMode "Emergency lane keeping mode";
CM_ SG_ 146 VFC_ELKMode "Emergency lane keeping system status0x4~0x7=reseved";
CM_ SG_ 146 VFC_HostLaneRightStatus "Lane status on the right side of this lane";
CM_ SG_ 146 VFC_TargetBasedLateralControl "Horizontal control target type";
CM_ SG_ 146 VFC_HandsoffFuncStatus "Hands-off assisted driving function status";
CM_ SG_ 146 VFC_HandsoffFuncTextinfo "Tips for hands-off assisted driving function information;0xE~0xF=Reserved;";
CM_ SG_ 146 VFC_LLaneMarkerType "Left lane line type";
CM_ SG_ 146 VFC_ELKEnableStatus "Emergency lane remains on and off";
CM_ SG_ 146 VFC_LLLaneDistance "Distance from vehicle center to left-hand lane line;0x0-0x3C=0-12;
0x3D-0x3F=reserved;";
CM_ SG_ 146 VFC_LatPathDY "Distance between horizontal target track and actual track;????,????
DY(N : value of the message) :
   = N נ0.01 , for  0 =N = 511
   = (N-1024) נ0.01 , for N >511
Note:that Clockwise rotation is ‘-‘ and anti-Clockwise rotation is ‘+‘
";
CM_ SG_ 146 VFC_RoadCurvature "Road curvature at current location;????,????
0x0-0x78=-0.03-0.03;
0x79-0x7F=reserved;";
CM_ SG_ 146 VFC_LLLaneDetection "Recognition of left and left lane lines";
CM_ SG_ 146 VFC_LatPathHeadingAngle "Heading angle deviation between lateral target trajectory and actual;????,???? Heading angle (N : value of the message) := N נ0.1 , for  0 =N = 1023= (N-2048) נ0.1 , for N >1023Note:that Clockwise rotation is ‘-‘ and anti-Clockwise rotation is ‘+‘";
CM_ SG_ 146 VFC_Voiceinfo "Driving assistance sound information;0xF~0x1F=reserved";
CM_ SG_ 146 VFC_RRLaneDetection "Right and right lane line recognition;0x0-0x3C=0-12;
0x3D-0x3F=reserved;";
CM_ SG_ 146 VFC_RoadCurvatureNear "Road curvature 50m ahead;0x0-0x78=-0.03-0.03;0x79-0x7F=reserved;";
CM_ SG_ 147 VFC_VFC_LDS2RFC03_CRC "CRC - Autosar E2E Profile 5";
CM_ SG_ 147 VFC_VFC_LDS2RFC03_AliverCtr "Alive counter - Autosar E2E Profile 5";
CM_ SG_ 147 VFC_LaneQuality "置信度为百分比，换算公式为0.015625*(0x0~0x3F)";
CM_ SG_ 147 VFC_LaneEquationC1 "Lane line equation coefficient C1;????????:y=C0+C1*x+(1/2)*C2*x^2+(1/6)*C3*x^3,??C1????????????,?????-1+(0x0 ~ 0xFFE)*2^(-11))";
CM_ SG_ 147 VFC_LaneEquationC2 "Lane line equation coefficient C2;????????:y=C0+C1*x+(1/2)*C2*x^2+(1/6)*C3*x^3,??C2??????,?????(-2047 + (0x0 ~ 0xFFE))*2^(-16))";
CM_ SG_ 147 VFC_LaneEquationStatus "Lane line equation state signal";
CM_ SG_ 147 VFC_LaneEquationC3 "Lane line equation coefficient C3;????????:y=C0+C1*x+(1/2)*C2*x^2+(1/6)*C3*x^3,??C3?????????,?????(-2047 + (0x0 ~ 0xFFE))*2^(-21))";
CM_ SG_ 148 VFC_VFC_LDS2RFC04_CRC "CRC - Autosar E2E Profile 5";
CM_ SG_ 148 VFC_VFC_LDS2RFC04_AliverCtr "Alive counter - Autosar E2E Profile 5";
CM_ SG_ 148 VFC_LDWStatus "LDW status";
CM_ SG_ 148 VFC_LDWVibrationWarningReq "Vibration alarm request";
CM_ SG_ 148 VFC_LKAStatus "LKA status";
CM_ BO_ 149 "Transmit by MPC3 without receivers for lab test of lateral feature";
CM_ SG_ 149 VFC_Fct_Status_CRC "CRC - Autosar E2E Profile 5";
CM_ SG_ 149 VFC_Fct_Status_AliverCtr "Alive counter - Autosar E2E Profile 5";
CM_ SG_ 149 VFC_vehicleReachTargetLane "represent if vehicle is in target lane";
CM_ SG_ 149 VFC_isLaneChangeFinished "represent if lane change event is finished";
CM_ SG_ 149 VFC_inLaneChangeManoeuvre "represent if lane change manoeuvre is ended";
CM_ SG_ 149 VFC_isAlcAttentiveHandsOnSt "represent if driver is attentive";
CM_ SG_ 149 VFC_laneChangeDirectionChanged "represent if lane change direction is changed(support to check retreat behavior)";
CM_ SG_ 149 VFC_ILCASysSts "ALC status for regulation";
CM_ SG_ 149 VFC_DirectionIndDisableReq "direction indicator disable request from ALC function";
CM_ SG_ 149 VFC_OpticalWarningForALC "optical warning signal from ALC function";
CM_ SG_ 149 VFC_HapticWarningForALC "haptic warning signal from ALC function";
CM_ SG_ 930 VFC_TSR_NEWFC "Indicate that the detected speed limit sign vale is new or not";
CM_ SG_ 930 VFC_TSR_ASL_CRC "CRC - Autosar E2E Profile 5";
CM_ SG_ 930 VFC_TSR_ASL_AliveCtr "Alive counter - Autosar E2E Profile 5";
CM_ SG_ 930 VFC_ADAS_ModSts_SLA "SLA mode status, from BJEV ASL spec V0.8";
CM_ SG_ 930 VFC_ADAS_SpdLim_SLA "Speed limit value, from BJEV ASL spec V0.8";
CM_ SG_ 930 VFC_ADAS_SpdLimUnit_SLA "Speed limit unit, from BJEV ASL spec V0.8";
CM_ SG_ 929 VFC_TLAObject_CRC "CRC - Autosar E2E Profile 5";
CM_ SG_ 929 VFC_TLAObject_AliveCtr "Alive counter - Autosar E2E Profile 5";
CM_ SG_ 929 VFC_TLAObject_ProtBlockCtr "Protocol-Signal: Block-Counter";
CM_ SG_ 929 VFC_TLAObjectColour_LeftLane "Left lane traffic light color";
CM_ SG_ 929 VFC_TLAObjectColour_RightLane "Right lane traffic light color";
CM_ SG_ 929 VFC_TLAObjectColour_HostLane "Straight lane traffic light color";
CM_ SG_ 929 VFC_TLAStopLine_HostLane "Distance between front bumper and stop line";
CM_ SG_ 929 VFC_TLF_SuggestedDriveAction "Suggested driving action";
CM_ SG_ 929 VFC_TLATrafficLightDisLeft "represent the distance to the traffic light";
CM_ SG_ 929 VFC_TLATrafficLightDisRight "represent the distance to the traffic light";
CM_ SG_ 929 VFC_TLATrafficLightDisHost "represent the distance to the traffic light";
CM_ SG_ 929 VFC_VFC_TLAZebraLineDis "represent the distance to the zebra line";
CM_ SG_ 273 RFC_TIPLBoundary_CRC "CRC - Autosar E2E Profile 5";
CM_ SG_ 288 RFC_OnComingObj0_CRC "Crc_Calculate CRC8 SAE J1850";
CM_ SG_ 288 RFC_OnComingObj0_MsgCtr "Alive Counter";
CM_ SG_ 288 RFC_OnComingObj0_ID "PER fus handle of the object";
CM_ SG_ 288 RFC_OnComingObj0_Dx "longitudinal distance, relative to ego";
CM_ SG_ 288 RFC_OnComingObj0_Vx "longitudinal velocity, relative to ego";
CM_ SG_ 288 RFC_OnComingObj0_Dy "lateral distance, relative to ego";
CM_ SG_ 288 RFC_OnComingObj0_RFF "the object is fused with video(1) or radar only(0)";
CM_ SG_ 288 RFC_OnComingObj0_Width "width of object";
CM_ SG_ 289 RFC_OnComingObj1_CRC "Crc_Calculate CRC8 SAE J1850";
CM_ SG_ 289 RFC_OnComingObj1_MsgCtr "Alive Counter";
CM_ SG_ 289 RFC_OnComingObj1_ID "PER fus handle of the object";
CM_ SG_ 289 RFC_OnComingObj1_Dx "longitudinal distance, relative to ego";
CM_ SG_ 289 RFC_OnComingObj1_Vx "longitudinal velocity, relative to ego";
CM_ SG_ 289 RFC_OnComingObj1_Dy "lateral distance, relative to ego";
CM_ SG_ 289 RFC_OnComingObj1_RFF "the object is fused with video(1) or radar only(0)";
CM_ SG_ 289 RFC_OnComingObj1_Width "width of object";
CM_ SG_ 292 RFC_OnGoingObj0_CRC "Crc_Calculate CRC8 SAE J1850";
CM_ SG_ 292 RFC_OnGoingObj0_MsgCtr "Alive Counter";
CM_ SG_ 292 RFC_OnGoingObj0_ID "PER fus handle of the object";
CM_ SG_ 292 RFC_OnGoingObj0_Dx "longitudinal distance, relative to ego";
CM_ SG_ 292 RFC_OnGoingObj0_Vx "longitudinal velocity, relative to ego";
CM_ SG_ 292 RFC_OnGoingObj0_Dy "lateral distance, relative to ego";
CM_ SG_ 292 RFC_OnGoingObj0_RFF "the object is fused with video(1) or radar only(0)";
CM_ SG_ 293 RFC_OnGoingObj1_CRC "Crc_Calculate CRC8 SAE J1850";
CM_ SG_ 293 RFC_OnGoingObj1_MsgCtr "Alive Counter";
CM_ SG_ 293 RFC_OnGoingObj1_ID "PER fus handle of the object";
CM_ SG_ 293 RFC_OnGoingObj1_Dx "longitudinal distance, relative to ego";
CM_ SG_ 293 RFC_OnGoingObj1_Vx "longitudinal velocity, relative to ego";
CM_ SG_ 293 RFC_OnGoingObj1_Dy "lateral distance, relative to ego";
CM_ SG_ 293 RFC_OnGoingObj1_RFF "the object is fused with video(1) or radar only(0)";
CM_ SG_ 80 VFC_GlobalHdr_CRC "CRC - Autosar E2E Profile 5";
CM_ SG_ 80 VFC_GlobalHdr_AliveCtr "Alive counter - Autosar E2E Profile 5";
CM_ SG_ 80 VFC_GlobalHdr_SensorState "The current state of the camera system
Previously VFC_SensorState_VisionFault in BJEV";
CM_ SG_ 80 VFC_GlobalHdr_CalibState "The calibration state of the camera system";
CM_ SG_ 80 VFC_GlobalHdr_TimeStamp "AUTOSAR TimeStamp of frame";
CM_ SG_ 80 VFC_GlobalHdr_ProtocolVersion "Protocol version to be send (BCD coded: Major.Minor): 0x0200 = V2.0";
CM_ SG_ 80 VFC_GlobalHdr_FrameNumber "The frame number that the data belongs to";
CM_ SG_ 80 VFC_GlobalHdr_SwVersion "SW version: 4 digits major version, 2 digits minor version";
CM_ SG_ 80 VFC_GlobalHdr_MountPosY "The current estimation of mounting position of the camera in the lateral direction";
CM_ SG_ 80 VFC_GlobalHdr_MountPosX "The current estimation of mounting position of the camera in the longitudinal direction";
CM_ SG_ 80 VFC_GlobalHdr_MountPosZ "The current estimation of mounting position of the camera in the vertical direction";
CM_ SG_ 80 VFC_GlobalHdr_CalYawAngle "The calibrated yaw angle of the camera";
CM_ SG_ 80 VFC_GlobalHdr_CalPitchAngle "The calibrated pitch angle of the camera";
CM_ SG_ 80 VFC_GlobalHdr_CalRollAngle "The calibrated roll angle of the camera";
CM_ SG_ 80 VFC_GlobalHdr_CalYawStdDev "The standard deviation of the calibrated yaw angle of the camera";
CM_ SG_ 80 VFC_GlobalHdr_CalPitchStdDev "The standard deviation of the calibrated pitch angle of the camera";
CM_ SG_ 80 VFC_GlobalHdr_CalRollStdDev "The standard deviation of the calibrated roll angle of the camera";
CM_ SG_ 80 VFC_GlobalHdr_TimeLatency "Absolute time gap, i.e. latency, between measurement time and sending time";
BA_DEF_ BO_  "GenMsgSendType" ENUM  "cyclic","NoMsgSendType","IfActive","Event","CA","CE";
BA_DEF_ BO_  "GenMsgCycleTime" INT 0 0;
BA_DEF_ SG_  "GenSigSendType" ENUM  "cyclic","OnChange","OnWrite","IfActive","OnChangeWithRepetition","OnWriteWithRepetition","IfActiveWithRepetition","CA","CE","Event";
BA_DEF_ SG_  "GenSigStartValue" INT 0 0;
BA_DEF_  "DBName" STRING ;
BA_DEF_ BO_  "CANFD_BRS" ENUM  "0","1";
BA_DEF_ BO_  "VFrameFormat" ENUM  "StandardCAN","ExtendedCAN","reserved","reserved","reserved","reserved","reserved","reserved","reserved","reserved","reserved","reserved","reserved","reserved","StandardCAN_FD","ExtendedCAN_FD";
BA_DEF_  "BusBaudateData" INT 0 10000;
BA_DEF_  "BusBaudateOther" INT 0 10000;
BA_DEF_ BO_  "GenMsgILSupport" ENUM  "No","Yes";
BA_DEF_  "BusType" STRING ;
BA_DEF_DEF_  "GenMsgSendType" "cyclic";
BA_DEF_DEF_  "GenMsgCycleTime" 0;
BA_DEF_DEF_  "GenSigSendType" "cyclic";
BA_DEF_DEF_  "GenSigStartValue" 0;
BA_DEF_DEF_  "DBName" "";
BA_DEF_DEF_  "CANFD_BRS" "1";
BA_DEF_DEF_  "VFrameFormat" "";
BA_DEF_DEF_  "BusBaudateData" 2;
BA_DEF_DEF_  "BusBaudateOther" 500;
BA_DEF_DEF_  "GenMsgILSupport" "Yes";
BA_DEF_DEF_  "BusType" "CAN FD";
BA_ "DBName" "DASy_RFC_VFC";
BA_ "GenMsgCycleTime" BO_ 941 20;
BA_ "VFrameFormat" BO_ 941 14;
BA_ "GenMsgCycleTime" BO_ 940 20;
BA_ "VFrameFormat" BO_ 940 14;
BA_ "GenMsgCycleTime" BO_ 938 20;
BA_ "VFrameFormat" BO_ 938 14;
BA_ "GenMsgCycleTime" BO_ 939 100;
BA_ "VFrameFormat" BO_ 939 14;
BA_ "GenMsgCycleTime" BO_ 931 100;
BA_ "VFrameFormat" BO_ 931 14;
BA_ "GenMsgCycleTime" BO_ 360 50;
BA_ "VFrameFormat" BO_ 360 14;
BA_ "GenMsgCycleTime" BO_ 340 50;
BA_ "VFrameFormat" BO_ 340 14;
BA_ "GenMsgCycleTime" BO_ 361 50;
BA_ "VFrameFormat" BO_ 361 14;
BA_ "GenMsgCycleTime" BO_ 370 50;
BA_ "VFrameFormat" BO_ 370 14;
BA_ "GenMsgCycleTime" BO_ 369 50;
BA_ "VFrameFormat" BO_ 369 14;
BA_ "GenMsgCycleTime" BO_ 368 50;
BA_ "VFrameFormat" BO_ 368 14;
BA_ "GenMsgCycleTime" BO_ 151 20;
BA_ "VFrameFormat" BO_ 151 14;
BA_ "GenMsgCycleTime" BO_ 87 50;
BA_ "VFrameFormat" BO_ 87 14;
BA_ "GenMsgCycleTime" BO_ 2281601536 20;
BA_ "VFrameFormat" BO_ 2281601536 15;
BA_ "GenMsgCycleTime" BO_ 255 500;
BA_ "VFrameFormat" BO_ 255 14;
BA_ "GenMsgCycleTime" BO_ 75 20;
BA_ "VFrameFormat" BO_ 75 14;
BA_ "GenMsgCycleTime" BO_ 137 10;
BA_ "VFrameFormat" BO_ 137 14;
BA_ "GenMsgCycleTime" BO_ 145 100;
BA_ "VFrameFormat" BO_ 145 14;
BA_ "GenMsgCycleTime" BO_ 146 100;
BA_ "VFrameFormat" BO_ 146 14;
BA_ "GenMsgCycleTime" BO_ 147 100;
BA_ "VFrameFormat" BO_ 147 14;
BA_ "GenMsgCycleTime" BO_ 148 20;
BA_ "VFrameFormat" BO_ 148 14;
BA_ "GenMsgCycleTime" BO_ 149 50;
BA_ "VFrameFormat" BO_ 149 14;
BA_ "GenMsgCycleTime" BO_ 930 100;
BA_ "VFrameFormat" BO_ 930 14;
BA_ "GenMsgSendType" BO_ 929 3;
BA_ "VFrameFormat" BO_ 929 14;
BA_ "GenMsgSendType" BO_ 273 3;
BA_ "VFrameFormat" BO_ 273 14;
BA_ "GenMsgCycleTime" BO_ 288 50;
BA_ "VFrameFormat" BO_ 288 14;
BA_ "GenMsgCycleTime" BO_ 289 50;
BA_ "VFrameFormat" BO_ 289 14;
BA_ "GenMsgCycleTime" BO_ 292 50;
BA_ "VFrameFormat" BO_ 292 14;
BA_ "GenMsgCycleTime" BO_ 293 50;
BA_ "VFrameFormat" BO_ 293 14;
BA_ "GenMsgSendType" BO_ 80 3;
BA_ "VFrameFormat" BO_ 80 14;
BA_ "GenSigStartValue" SG_ 941 AEB_TimeToBrk 1000;
BA_ "GenSigStartValue" SG_ 940 ACC_objectDataList0vy 128;
BA_ "GenSigStartValue" SG_ 940 ACC_objectDataList0vx 128;
BA_ "GenSigStartValue" SG_ 940 ACC_objectDataList0dy 128;
BA_ "GenSigStartValue" SG_ 938 VFC_steeringWheelAngleSig 7800;
BA_ "GenSigStartValue" SG_ 938 VFC_accelerationLateralSig 2000;
BA_ "GenSigStartValue" SG_ 938 VFC_accelerationLongitudinalSig 2000;
BA_ "GenSigStartValue" SG_ 938 VFC_yawrateSig 18000;
BA_ "GenSigStartValue" SG_ 75 RFC_ToqReq_ESS 1024;
BA_ "GenSigStartValue" SG_ 75 RFC_AngReq_ESS 14400;
BA_ "GenSigStartValue" SG_ 137 VFC_MotorTorqueMaxLimitRequest 1024;
BA_ "GenSigStartValue" SG_ 137 VFC_MotorTorqueMinLimitRequest 1024;
BA_ "GenSigStartValue" SG_ 145 Selflearning_angle 1025;
BA_ "GenSigStartValue" SG_ 145 VFC_LLaneDistanceFusion 36;
BA_ "GenSigStartValue" SG_ 145 VFC_RLaneDistanceFusion 36;
BA_ "GenSigStartValue" SG_ 146 VFC_LASModeSelectionStatus 1;
BA_ "GenSigStartValue" SG_ 146 VFC_RLaneMarkerType 7;
BA_ "GenSigStartValue" SG_ 146 VFC_RoadCurvatureFar 60;
BA_ "GenSigStartValue" SG_ 146 VFC_RRLaneDistance 28;
BA_ "GenSigStartValue" SG_ 146 VFC_LASWarningModeSelectionSts 2;
BA_ "GenSigStartValue" SG_ 146 VFC_LDWShakeLevStatus 2;
BA_ "GenSigStartValue" SG_ 146 VFC_LLaneMarkerType 7;
BA_ "GenSigStartValue" SG_ 146 VFC_LLLaneDistance 28;
BA_ "GenSigStartValue" SG_ 146 VFC_RoadCurvature 60;
BA_ "GenSigStartValue" SG_ 146 VFC_RoadCurvatureNear 60;
BA_ "GenSigStartValue" SG_ 147 VFC_LaneEquationC1 2047;
BA_ "GenSigStartValue" SG_ 147 VFC_LaneEquationC2 2047;
BA_ "GenSigStartValue" SG_ 147 VFC_LaneEquationC3 2047;
BA_ "GenSigSendType" SG_ 80 VFC_GlobalHdr_CRC 9;
BA_ "GenSigSendType" SG_ 80 VFC_GlobalHdr_AliveCtr 9;
BA_ "GenSigSendType" SG_ 80 VFC_GlobalHdr_SensorState 9;
BA_ "GenSigStartValue" SG_ 80 VFC_GlobalHdr_SensorState 1;
BA_ "GenSigSendType" SG_ 80 VFC_GlobalHdr_CalibState 9;
BA_ "GenSigSendType" SG_ 80 VFC_GlobalHdr_TimeStamp 9;
BA_ "GenSigSendType" SG_ 80 VFC_GlobalHdr_ProtocolVersion 9;
BA_ "GenSigStartValue" SG_ 80 VFC_GlobalHdr_ProtocolVersion 512;
BA_ "GenSigSendType" SG_ 80 VFC_GlobalHdr_FrameNumber 9;
BA_ "GenSigSendType" SG_ 80 VFC_GlobalHdr_SwVersion 9;
BA_ "GenSigSendType" SG_ 80 VFC_GlobalHdr_MountPosY 9;
BA_ "GenSigStartValue" SG_ 80 VFC_GlobalHdr_MountPosY 2048;
BA_ "GenSigSendType" SG_ 80 VFC_GlobalHdr_MountPosX 9;
BA_ "GenSigStartValue" SG_ 80 VFC_GlobalHdr_MountPosX 4096;
BA_ "GenSigSendType" SG_ 80 VFC_GlobalHdr_MountPosZ 9;
BA_ "GenSigSendType" SG_ 80 VFC_GlobalHdr_CalYawAngle 9;
BA_ "GenSigStartValue" SG_ 80 VFC_GlobalHdr_CalYawAngle 512;
BA_ "GenSigSendType" SG_ 80 VFC_GlobalHdr_CalPitchAngle 9;
BA_ "GenSigStartValue" SG_ 80 VFC_GlobalHdr_CalPitchAngle 512;
BA_ "GenSigSendType" SG_ 80 VFC_GlobalHdr_CalRollAngle 9;
BA_ "GenSigStartValue" SG_ 80 VFC_GlobalHdr_CalRollAngle 512;
BA_ "GenSigSendType" SG_ 80 VFC_GlobalHdr_CalYawStdDev 9;
BA_ "GenSigSendType" SG_ 80 VFC_GlobalHdr_CalPitchStdDev 9;
BA_ "GenSigSendType" SG_ 80 VFC_GlobalHdr_CalRollStdDev 9;
VAL_ 3221225472 VFC_Left_Type 0 "TYPE_SOLID_LINE" 1 "TYPE_DASHED_LINE" 2 "TYPE_DOUBLE_DASHED_DASHED" 3 "TYPE_DOUBLE_DASHED_SOLID" 4 "TYPE_DOUBLE_SOLID_DASHED" 5 "TYPE_DOUBLE_SOLID_SOLID" 6 "TYPE_MULTIPLE" 7 "TYPE_MULTIPLE_WARNING" 8 "TYPE_BOTTS_DOTS" 9 "TYPE_ROAD_EDGE" 10 "TYPE_ROAD_FURNITURE" 11 "TYPE_CURBSTONE" 12 "TYPE_TRAFFIC_STATIC" 13 "TYPE_UNKNOWN_RAISED" 14 "TYPE_UNKNOWN" ;
VAL_ 3221225472 VFC_Right_Type 0 "TYPE_SOLID_LINE" 1 "TYPE_DASHED_LINE" 2 "TYPE_DOUBLE_DASHED_DASHED" 3 "TYPE_DOUBLE_DASHED_SOLID" 4 "TYPE_DOUBLE_SOLID_DASHED" 5 "TYPE_DOUBLE_SOLID_SOLID" 6 "TYPE_MULTIPLE" 7 "TYPE_MULTIPLE_WARNING" 8 "TYPE_BOTTS_DOTS" 9 "TYPE_ROAD_EDGE" 10 "TYPE_ROAD_FURNITURE" 11 "TYPE_CURBSTONE" 12 "TYPE_TRAFFIC_STATIC" 13 "TYPE_UNKNOWN_RAISED" 14 "TYPE_UNKNOWN" ;
VAL_ 3221225472 VFC_LeftLe_Type 0 "TYPE_SOLID_LINE" 1 "TYPE_DASHED_LINE" 2 "TYPE_DOUBLE_DASHED_DASHED" 3 "TYPE_DOUBLE_DASHED_SOLID" 4 "TYPE_DOUBLE_SOLID_DASHED" 5 "TYPE_DOUBLE_SOLID_SOLID" 6 "TYPE_MULTIPLE" 7 "TYPE_MULTIPLE_WARNING" 8 "TYPE_BOTTS_DOTS" 9 "TYPE_ROAD_EDGE" 10 "TYPE_ROAD_FURNITURE" 11 "TYPE_CURBSTONE" 12 "TYPE_TRAFFIC_STATIC" 13 "TYPE_UNKNOWN_RAISED" 14 "TYPE_UNKNOWN" ;
VAL_ 3221225472 VFC_RightRi_Type 0 "TYPE_SOLID_LINE" 1 "TYPE_DASHED_LINE" 2 "TYPE_DOUBLE_DASHED_DASHED" 3 "TYPE_DOUBLE_DASHED_SOLID" 4 "TYPE_DOUBLE_SOLID_DASHED" 5 "TYPE_DOUBLE_SOLID_SOLID" 6 "TYPE_MULTIPLE" 7 "TYPE_MULTIPLE_WARNING" 8 "TYPE_BOTTS_DOTS" 9 "TYPE_ROAD_EDGE" 10 "TYPE_ROAD_FURNITURE" 11 "TYPE_CURBSTONE" 12 "TYPE_TRAFFIC_STATIC" 13 "TYPE_UNKNOWN_RAISED" 14 "TYPE_UNKNOWN" ;
VAL_ 3221225472 RFC_ACCObjInfo1_ValidFlag 0 "valid" 1 "invalid" ;
VAL_ 3221225472 RFC_ACCObjInfo1_UpdateFlag 0 "OBJECT_EXISTED_IN_PREVIOUS_CYCLE" 1 "NEW_OBJECT_IN_THE_CYCLE" ;
VAL_ 3221225472 RFC_ACCObjInfo1_Type 3 "Pedestrian" 2 "2 wheeler" 1 "4 wheeler and plus" 0 "Unknown" ;
VAL_ 3221225472 RFC_ACCObjInfo1_EDynProp 0 "MOVING_DYNAMICPROPERTY" 1 "STATIONARY_DYNAMICPROPERTY" 2 "ONCOMING_DYNAMICPROPERTY" 3 "CROSSING_LEFT_TO_RIGHT_DYNAMICPR" 4 "CROSSING_RIGHT_TO_LEFT_DYNAMICPR" 5 "UNKNOWN_DYNAMICPROPERTY" 6 "STOPPED_DYNAMICPROPERTY" 7 "RESERVED" ;
VAL_ 3221225472 RFC_ACCObjInfo1_UiLifeCycles 126 "MAX_CYCLE_OBJ_LIFECYCLE" 127 "INVALID_OBJ_LIFECYCLE" ;
VAL_ 3221225472 RFC_OnGoingObj3_ValidFlag 0 "valid" 1 "invalid" ;
VAL_ 3221225472 RFC_OnGoingObj3_UpdateFlag 0 "OBJECT_EXISTED_IN_PREVIOUS_CYCLE" 1 "NEW_OBJECT_IN_THE_CYCLE" ;
VAL_ 3221225472 RFC_OnGoingObj3_Type 3 "Pedestrian" 2 "2 wheeler" 1 "4 wheeler and plus" 0 "Unknown" ;
VAL_ 3221225472 RFC_OnGoingObj3_EDynProp 0 "MOVING_DYNAMICPROPERTY" 1 "STATIONARY_DYNAMICPROPERTY" 2 "ONCOMING_DYNAMICPROPERTY" 3 "CROSSING_LEFT_TO_RIGHT_DYNAMICPR" 4 "CROSSING_RIGHT_TO_LEFT_DYNAMICPR" 5 "UNKNOWN_DYNAMICPROPERTY" 6 "STOPPED_DYNAMICPROPERTY" 7 "RESERVED" ;
VAL_ 3221225472 RFC_OnGoingObj3_UiLifeCycles 126 "MAX_CYCLE_OBJ_LIFECYCLE" 127 "INVALID_OBJ_LIFECYCLE" ;
VAL_ 3221225472 RFC_OnGoingObj2_ValidFlag 0 "valid" 1 "invalid" ;
VAL_ 3221225472 RFC_OnGoingObj2_UpdateFlag 0 "OBJECT_EXISTED_IN_PREVIOUS_CYCLE" 1 "NEW_OBJECT_IN_THE_CYCLE" ;
VAL_ 3221225472 RFC_OnGoingObj2_Type 3 "Pedestrian" 2 "2 wheeler" 1 "4 wheeler and plus" 0 "Unknown" ;
VAL_ 3221225472 RFC_OnGoingObj2_EDynProp 0 "MOVING_DYNAMICPROPERTY" 1 "STATIONARY_DYNAMICPROPERTY" 2 "ONCOMING_DYNAMICPROPERTY" 3 "CROSSING_LEFT_TO_RIGHT_DYNAMICPR" 4 "CROSSING_RIGHT_TO_LEFT_DYNAMICPR" 5 "UNKNOWN_DYNAMICPROPERTY" 6 "STOPPED_DYNAMICPROPERTY" 7 "RESERVED" ;
VAL_ 3221225472 RFC_OnGoingObj2_UiLifeCycles 126 "MAX_CYCLE_OBJ_LIFECYCLE" 127 "INVALID_OBJ_LIFECYCLE" ;
VAL_ 3221225472 RRR_ObjHdr_TimeStampStatus 0 "TIMEOUT" 1 "Reserved1" 2 "SYNC_TO_GATEWAY" 3 "GLOBAL_TIME_BASE" 4 "TIMELEAP_FUTURE" 5 "TIMELEAP_PAST" 6 "Reserved6" 7 "Extension: GENERAL_ERROR" ;
VAL_ 3221225472 RRL_ObjHdr_TimeStampStatus 0 "TIMEOUT" 1 "Reserved1" 2 "SYNC_TO_GATEWAY" 3 "GLOBAL_TIME_BASE" 4 "TIMELEAP_FUTURE" 5 "TIMELEAP_PAST" 6 "Reserved6" 7 "Extension: GENERAL_ERROR" ;
VAL_ 3221225472 RFR_ObjHdr_TimeStampStatus 0 "TIMEOUT" 1 "Reserved1" 2 "SYNC_TO_GATEWAY" 3 "GLOBAL_TIME_BASE" 4 "TIMELEAP_FUTURE" 5 "TIMELEAP_PAST" 6 "Reserved6" 7 "Extension: GENERAL_ERROR" ;
VAL_ 3221225472 RFL_ObjHdr_TimeStampStatus 0 "TIMEOUT" 1 "Reserved1" 2 "SYNC_TO_GATEWAY" 3 "GLOBAL_TIME_BASE" 4 "TIMELEAP_FUTURE" 5 "TIMELEAP_PAST" 6 "Reserved6" 7 "Extension: GENERAL_ERROR" ;
VAL_ 3221225472 VFC_ALCSt 7 "Reserved" 6 "TOR" 5 "Perm Failure" 4 "Temp Failure" 3 "Active" 2 "Active Request" 1 "Passive" 0 "Init" ;
VAL_ 3221225472 VFC_LaneChangeDirection 3 "Reserved" 2 "Right" 1 "Left" 0 "None" ;
VAL_ 3221225472 VFC_SafeSearchCondition 1 "True" 0 "False" ;
VAL_ 3221225472 VFC_JumpTargetLane 1 "True" 0 "False" ;
VAL_ 3221225472 LaneChangeLeft_recommendation 1 "Recommend" 0 "Not Recommend" ;
VAL_ 3221225472 LaneChangeRight_recommendation 1 "Recommend" 0 "Not Recommend" ;
VAL_ 3221225472 CRObj_LeftObjLostAtCloseRange 1 "Lost" 0 "Not Lost" ;
VAL_ 3221225472 CRObj_RightObjLostAtCloseRange 1 "Lost" 0 "Not Lost" ;
VAL_ 3221225472 CRObj_evaluator_axd_valid 0 "Invalid" 1 "Valid" ;
VAL_ 3221225472 CRObj_evaluator_axc_valid 0 "Invalid" 1 "Valid" ;
VAL_ 3221225472 FLObj_evaluator_feasibility 0 "Unfeasible" 1 "Feasible" ;
VAL_ 3221225472 FRObj_evaluator_feasibility 0 "Unfeasible" 1 "Feasible" ;
VAL_ 3221225472 RLObj_evaluator_feasibility 0 "Unfeasible" 1 "Feasible" ;
VAL_ 3221225472 RRObj_evaluator_feasibility 0 "Unfeasible" 1 "Feasible" ;
VAL_ 3221225472 RFC_ALC_CR_invalid 0 "Valid" 1 "Invalid" ;
VAL_ 3221225472 RFL_Modulation_Status 0 "Normal" 1 "TimeSyncFail_ModFail" 2 "TimeSyncCorrect_ModFail" 3 "Reserved" ;
VAL_ 3221225472 RFL_Status_SensorState 0 "SENSOR FULLY OPERATIONAL" 1 "HW MALFUNCTION" 2 "DSP ISSUES" 3 "COMMUNICATION ERRORS" 4 "MISALIGNMENT (OUT OF SPEC)" 5 "SENSOR BLIDNESS DETECTED" 6 "SENSOR DISTUBED" 7 "OTHER ISSUES" 8 "DSP OFF BY REQUEST" 9 "RESERVED1" 10 "RESERVED2" 11 "RESERVED3" 12 "RESERVED4" 13 "RESERVED5" 14 "RESERVED6" 15 "INVALID" ;
VAL_ 3221225472 RFR_Modulation_Status 0 "Normal" 1 "TimeSyncFail_ModFail" 2 "TimeSyncCorrect_ModFail" 3 "Reserved" ;
VAL_ 3221225472 RFR_Status_SensorState 0 "SENSOR FULLY OPERATIONAL" 1 "HW MALFUNCTION" 2 "DSP ISSUES" 3 "COMMUNICATION ERRORS" 4 "MISALIGNMENT (OUT OF SPEC)" 5 "SENSOR BLIDNESS DETECTED" 6 "SENSOR DISTUBED" 7 "OTHER ISSUES" 8 "DSP OFF BY REQUEST" 9 "RESERVED1" 10 "RESERVED2" 11 "RESERVED3" 12 "RESERVED4" 13 "RESERVED5" 14 "RESERVED6" 15 "INVALID" ;
VAL_ 3221225472 RRL_Status_SensorState 0 "SENSOR FULLY OPERATIONAL" 1 "HW MALFUNCTION" 2 "DSP ISSUES" 3 "COMMUNICATION ERRORS" 4 "MISALIGNMENT (OUT OF SPEC)" 5 "SENSOR BLIDNESS DETECTED" 6 "SENSOR DISTUBED" 7 "OTHER ISSUES" 8 "DSP OFF BY REQUEST" 9 "RESERVED1" 10 "RESERVED2" 11 "RESERVED3" 12 "RESERVED4" 13 "RESERVED5" 14 "RESERVED6" 15 "INVALID" ;
VAL_ 3221225472 RRL_Modulation_Status 0 "Normal" 1 "TimeSyncFail_ModFail" 2 "TimeSyncCorrect_ModFail" 3 "Reserved" ;
VAL_ 3221225472 RRR_Status_SensorState 0 "SENSOR FULLY OPERATIONAL" 1 "HW MALFUNCTION" 2 "DSP ISSUES" 3 "COMMUNICATION ERRORS" 4 "MISALIGNMENT (OUT OF SPEC)" 5 "SENSOR BLIDNESS DETECTED" 6 "SENSOR DISTUBED" 7 "OTHER ISSUES" 8 "DSP OFF BY REQUEST" 9 "RESERVED1" 10 "RESERVED2" 11 "RESERVED3" 12 "RESERVED4" 13 "RESERVED5" 14 "RESERVED6" 15 "INVALID" ;
VAL_ 3221225472 RRR_Modulation_Status 0 "Normal" 1 "TimeSyncFail_ModFail" 2 "TimeSyncCorrect_ModFail" 3 "Reserved" ;
VAL_ 3221225472 RFL_Obj00_RefPosIndex 0 "Front corner left" 1 "Front center" 2 "Front corner right" 3 "Front wheelcase left" 4 "Front wheelcase right" 5 "Side middle left" 6 "Side middle right" 7 "Rear wheelcase left" 8 "Rear wheelcase right" 9 "Rear corner left" 10 "Rear center" 11 "Rear corner right" 12 "Object center" 13 "Rear wheelcase center" 14 "Front wheelcase center" 15 "Invalid" ;
VAL_ 3221225472 RFL_Obj00_Valid 0 "not valid" 1 "valid" ;
VAL_ 3221225472 RFL_Obj01_RefPosIndex 0 "Front corner left" 1 "Front center" 2 "Front corner right" 3 "Front wheelcase left" 4 "Front wheelcase right" 5 "Side middle left" 6 "Side middle right" 7 "Rear wheelcase left" 8 "Rear wheelcase right" 9 "Rear corner left" 10 "Rear center" 11 "Rear corner right" 12 "Object center" 13 "Rear wheelcase center" 14 "Front wheelcase center" 15 "Invalid" ;
VAL_ 3221225472 RFL_Obj01_Valid 0 "not valid" 1 "valid" ;
VAL_ 3221225472 RFL_Obj02_RefPosIndex 0 "Front corner left" 1 "Front center" 2 "Front corner right" 3 "Front wheelcase left" 4 "Front wheelcase right" 5 "Side middle left" 6 "Side middle right" 7 "Rear wheelcase left" 8 "Rear wheelcase right" 9 "Rear corner left" 10 "Rear center" 11 "Rear corner right" 12 "Object center" 13 "Rear wheelcase center" 14 "Front wheelcase center" 15 "Invalid" ;
VAL_ 3221225472 RFL_Obj02_Valid 0 "not valid" 1 "valid" ;
VAL_ 3221225472 RFL_Obj03_RefPosIndex 0 "Front corner left" 1 "Front center" 2 "Front corner right" 3 "Front wheelcase left" 4 "Front wheelcase right" 5 "Side middle left" 6 "Side middle right" 7 "Rear wheelcase left" 8 "Rear wheelcase right" 9 "Rear corner left" 10 "Rear center" 11 "Rear corner right" 12 "Object center" 13 "Rear wheelcase center" 14 "Front wheelcase center" 15 "Invalid" ;
VAL_ 3221225472 RFL_Obj03_Valid 0 "not valid" 1 "valid" ;
VAL_ 3221225472 RFL_Obj04_RefPosIndex 0 "Front corner left" 1 "Front center" 2 "Front corner right" 3 "Front wheelcase left" 4 "Front wheelcase right" 5 "Side middle left" 6 "Side middle right" 7 "Rear wheelcase left" 8 "Rear wheelcase right" 9 "Rear corner left" 10 "Rear center" 11 "Rear corner right" 12 "Object center" 13 "Rear wheelcase center" 14 "Front wheelcase center" 15 "Invalid" ;
VAL_ 3221225472 RFL_Obj04_Valid 0 "not valid" 1 "valid" ;
VAL_ 3221225472 RFL_Obj05_RefPosIndex 0 "Front corner left" 1 "Front center" 2 "Front corner right" 3 "Front wheelcase left" 4 "Front wheelcase right" 5 "Side middle left" 6 "Side middle right" 7 "Rear wheelcase left" 8 "Rear wheelcase right" 9 "Rear corner left" 10 "Rear center" 11 "Rear corner right" 12 "Object center" 13 "Rear wheelcase center" 14 "Front wheelcase center" 15 "Invalid" ;
VAL_ 3221225472 RFL_Obj05_Valid 0 "not valid" 1 "valid" ;
VAL_ 3221225472 RFR_Obj00_RefPosIndex 0 "Front corner left" 1 "Front center" 2 "Front corner right" 3 "Front wheelcase left" 4 "Front wheelcase right" 5 "Side middle left" 6 "Side middle right" 7 "Rear wheelcase left" 8 "Rear wheelcase right" 9 "Rear corner left" 10 "Rear center" 11 "Rear corner right" 12 "Object center" 13 "Rear wheelcase center" 14 "Front wheelcase center" 15 "Invalid" ;
VAL_ 3221225472 RFR_Obj00_Valid 0 "not valid" 1 "valid" ;
VAL_ 3221225472 RFR_Obj01_RefPosIndex 0 "Front corner left" 1 "Front center" 2 "Front corner right" 3 "Front wheelcase left" 4 "Front wheelcase right" 5 "Side middle left" 6 "Side middle right" 7 "Rear wheelcase left" 8 "Rear wheelcase right" 9 "Rear corner left" 10 "Rear center" 11 "Rear corner right" 12 "Object center" 13 "Rear wheelcase center" 14 "Front wheelcase center" 15 "Invalid" ;
VAL_ 3221225472 RFR_Obj01_Valid 0 "not valid" 1 "valid" ;
VAL_ 3221225472 RFR_Obj02_RefPosIndex 0 "Front corner left" 1 "Front center" 2 "Front corner right" 3 "Front wheelcase left" 4 "Front wheelcase right" 5 "Side middle left" 6 "Side middle right" 7 "Rear wheelcase left" 8 "Rear wheelcase right" 9 "Rear corner left" 10 "Rear center" 11 "Rear corner right" 12 "Object center" 13 "Rear wheelcase center" 14 "Front wheelcase center" 15 "Invalid" ;
VAL_ 3221225472 RFR_Obj02_Valid 0 "not valid" 1 "valid" ;
VAL_ 3221225472 RFR_Obj03_RefPosIndex 0 "Front corner left" 1 "Front center" 2 "Front corner right" 3 "Front wheelcase left" 4 "Front wheelcase right" 5 "Side middle left" 6 "Side middle right" 7 "Rear wheelcase left" 8 "Rear wheelcase right" 9 "Rear corner left" 10 "Rear center" 11 "Rear corner right" 12 "Object center" 13 "Rear wheelcase center" 14 "Front wheelcase center" 15 "Invalid" ;
VAL_ 3221225472 RFR_Obj03_Valid 0 "not valid" 1 "valid" ;
VAL_ 3221225472 RFR_Obj04_RefPosIndex 0 "Front corner left" 1 "Front center" 2 "Front corner right" 3 "Front wheelcase left" 4 "Front wheelcase right" 5 "Side middle left" 6 "Side middle right" 7 "Rear wheelcase left" 8 "Rear wheelcase right" 9 "Rear corner left" 10 "Rear center" 11 "Rear corner right" 12 "Object center" 13 "Rear wheelcase center" 14 "Front wheelcase center" 15 "Invalid" ;
VAL_ 3221225472 RFR_Obj04_Valid 0 "not valid" 1 "valid" ;
VAL_ 3221225472 RFR_Obj05_RefPosIndex 0 "Front corner left" 1 "Front center" 2 "Front corner right" 3 "Front wheelcase left" 4 "Front wheelcase right" 5 "Side middle left" 6 "Side middle right" 7 "Rear wheelcase left" 8 "Rear wheelcase right" 9 "Rear corner left" 10 "Rear center" 11 "Rear corner right" 12 "Object center" 13 "Rear wheelcase center" 14 "Front wheelcase center" 15 "Invalid" ;
VAL_ 3221225472 RFR_Obj05_Valid 0 "not valid" 1 "valid" ;
VAL_ 3221225472 RRL_Obj00_RefPosIndex 0 "Front corner left" 1 "Front center" 2 "Front corner right" 3 "Front wheelcase left" 4 "Front wheelcase right" 5 "Side middle left" 6 "Side middle right" 7 "Rear wheelcase left" 8 "Rear wheelcase right" 9 "Rear corner left" 10 "Rear center" 11 "Rear corner right" 12 "Object center" 13 "Rear wheelcase center" 14 "Front wheelcase center" 15 "Invalid" ;
VAL_ 3221225472 RRL_Obj00_Valid 0 "not valid" 1 "valid" ;
VAL_ 3221225472 RRL_Obj01_RefPosIndex 0 "Front corner left" 1 "Front center" 2 "Front corner right" 3 "Front wheelcase left" 4 "Front wheelcase right" 5 "Side middle left" 6 "Side middle right" 7 "Rear wheelcase left" 8 "Rear wheelcase right" 9 "Rear corner left" 10 "Rear center" 11 "Rear corner right" 12 "Object center" 13 "Rear wheelcase center" 14 "Front wheelcase center" 15 "Invalid" ;
VAL_ 3221225472 RRL_Obj01_Valid 0 "not valid" 1 "valid" ;
VAL_ 3221225472 RRL_Obj02_RefPosIndex 0 "Front corner left" 1 "Front center" 2 "Front corner right" 3 "Front wheelcase left" 4 "Front wheelcase right" 5 "Side middle left" 6 "Side middle right" 7 "Rear wheelcase left" 8 "Rear wheelcase right" 9 "Rear corner left" 10 "Rear center" 11 "Rear corner right" 12 "Object center" 13 "Rear wheelcase center" 14 "Front wheelcase center" 15 "Invalid" ;
VAL_ 3221225472 RRL_Obj02_Valid 0 "not valid" 1 "valid" ;
VAL_ 3221225472 RRL_Obj03_RefPosIndex 0 "Front corner left" 1 "Front center" 2 "Front corner right" 3 "Front wheelcase left" 4 "Front wheelcase right" 5 "Side middle left" 6 "Side middle right" 7 "Rear wheelcase left" 8 "Rear wheelcase right" 9 "Rear corner left" 10 "Rear center" 11 "Rear corner right" 12 "Object center" 13 "Rear wheelcase center" 14 "Front wheelcase center" 15 "Invalid" ;
VAL_ 3221225472 RRL_Obj03_Valid 0 "not valid" 1 "valid" ;
VAL_ 3221225472 RRL_Obj04_RefPosIndex 0 "Front corner left" 1 "Front center" 2 "Front corner right" 3 "Front wheelcase left" 4 "Front wheelcase right" 5 "Side middle left" 6 "Side middle right" 7 "Rear wheelcase left" 8 "Rear wheelcase right" 9 "Rear corner left" 10 "Rear center" 11 "Rear corner right" 12 "Object center" 13 "Rear wheelcase center" 14 "Front wheelcase center" 15 "Invalid" ;
VAL_ 3221225472 RRL_Obj04_Valid 0 "not valid" 1 "valid" ;
VAL_ 3221225472 RRL_Obj05_RefPosIndex 0 "Front corner left" 1 "Front center" 2 "Front corner right" 3 "Front wheelcase left" 4 "Front wheelcase right" 5 "Side middle left" 6 "Side middle right" 7 "Rear wheelcase left" 8 "Rear wheelcase right" 9 "Rear corner left" 10 "Rear center" 11 "Rear corner right" 12 "Object center" 13 "Rear wheelcase center" 14 "Front wheelcase center" 15 "Invalid" ;
VAL_ 3221225472 RRL_Obj05_Valid 0 "not valid" 1 "valid" ;
VAL_ 3221225472 RRR_Obj00_RefPosIndex 0 "Front corner left" 1 "Front center" 2 "Front corner right" 3 "Front wheelcase left" 4 "Front wheelcase right" 5 "Side middle left" 6 "Side middle right" 7 "Rear wheelcase left" 8 "Rear wheelcase right" 9 "Rear corner left" 10 "Rear center" 11 "Rear corner right" 12 "Object center" 13 "Rear wheelcase center" 14 "Front wheelcase center" 15 "Invalid" ;
VAL_ 3221225472 RRR_Obj00_Valid 0 "not valid" 1 "valid" ;
VAL_ 3221225472 RRR_Obj01_RefPosIndex 0 "Front corner left" 1 "Front center" 2 "Front corner right" 3 "Front wheelcase left" 4 "Front wheelcase right" 5 "Side middle left" 6 "Side middle right" 7 "Rear wheelcase left" 8 "Rear wheelcase right" 9 "Rear corner left" 10 "Rear center" 11 "Rear corner right" 12 "Object center" 13 "Rear wheelcase center" 14 "Front wheelcase center" 15 "Invalid" ;
VAL_ 3221225472 RRR_Obj01_Valid 0 "not valid" 1 "valid" ;
VAL_ 3221225472 RRR_Obj02_RefPosIndex 0 "Front corner left" 1 "Front center" 2 "Front corner right" 3 "Front wheelcase left" 4 "Front wheelcase right" 5 "Side middle left" 6 "Side middle right" 7 "Rear wheelcase left" 8 "Rear wheelcase right" 9 "Rear corner left" 10 "Rear center" 11 "Rear corner right" 12 "Object center" 13 "Rear wheelcase center" 14 "Front wheelcase center" 15 "Invalid" ;
VAL_ 3221225472 RRR_Obj02_Valid 0 "not valid" 1 "valid" ;
VAL_ 3221225472 RRR_Obj03_RefPosIndex 0 "Front corner left" 1 "Front center" 2 "Front corner right" 3 "Front wheelcase left" 4 "Front wheelcase right" 5 "Side middle left" 6 "Side middle right" 7 "Rear wheelcase left" 8 "Rear wheelcase right" 9 "Rear corner left" 10 "Rear center" 11 "Rear corner right" 12 "Object center" 13 "Rear wheelcase center" 14 "Front wheelcase center" 15 "Invalid" ;
VAL_ 3221225472 RRR_Obj03_Valid 0 "not valid" 1 "valid" ;
VAL_ 3221225472 RRR_Obj04_RefPosIndex 0 "Front corner left" 1 "Front center" 2 "Front corner right" 3 "Front wheelcase left" 4 "Front wheelcase right" 5 "Side middle left" 6 "Side middle right" 7 "Rear wheelcase left" 8 "Rear wheelcase right" 9 "Rear corner left" 10 "Rear center" 11 "Rear corner right" 12 "Object center" 13 "Rear wheelcase center" 14 "Front wheelcase center" 15 "Invalid" ;
VAL_ 3221225472 RRR_Obj04_Valid 0 "not valid" 1 "valid" ;
VAL_ 3221225472 RRR_Obj05_RefPosIndex 0 "Front corner left" 1 "Front center" 2 "Front corner right" 3 "Front wheelcase left" 4 "Front wheelcase right" 5 "Side middle left" 6 "Side middle right" 7 "Rear wheelcase left" 8 "Rear wheelcase right" 9 "Rear corner left" 10 "Rear center" 11 "Rear corner right" 12 "Object center" 13 "Rear wheelcase center" 14 "Front wheelcase center" 15 "Invalid" ;
VAL_ 3221225472 RRR_Obj05_Valid 0 "not valid" 1 "valid" ;
VAL_ 939 VFC_fusResultSource 3 "Reserve" 2 "FusResult_INIT" 1 "FusResult_MAP" 0 "FusResult_FC" ;
VAL_ 939 VFC_fusResultstate 3 "DISP_PDM" 2 "DISP_MAP_SIGN" 1 "DISP_FC_SIGN" 0 "NO_DISP" ;
VAL_ 931 VFC_DirectSunlightDetect 0 "False" 1 "True" ;
VAL_ 340 RFC_ACCObjInfo0_ValidFlag 0 "valid" 1 "invalid" ;
VAL_ 340 RFC_ACCObjInfo0_UpdateFlag 0 "OBJECT_EXISTED_IN_PREVIOUS_CYCLE" 1 "NEW_OBJECT_IN_THE_CYCLE" ;
VAL_ 340 RFC_ACCObjInfo0_Type 3 "Pedestrian" 2 "2 wheeler" 1 "4 wheeler and plus" 0 "Unknown" ;
VAL_ 340 RFC_ACCObjInfo0_EDynProp 0 "MOVING_DYNAMICPROPERTY" 1 "STATIONARY_DYNAMICPROPERTY" 2 "ONCOMING_DYNAMICPROPERTY" 3 "CROSSING_LEFT_TO_RIGHT_DYNAMICPR" 4 "CROSSING_RIGHT_TO_LEFT_DYNAMICPR" 5 "UNKNOWN_DYNAMICPROPERTY" 6 "STOPPED_DYNAMICPROPERTY" 7 "RESERVED" ;
VAL_ 340 RFC_ACCObjInfo0_UiLifeCycles 126 "MAX_CYCLE_OBJ_LIFECYCLE" 127 "INVALID_OBJ_LIFECYCLE" ;
VAL_ 361 RFC_AEB_TGU_AEBP_Obj_ValidFlag 0 "valid" 1 "invalid" ;
VAL_ 361 RFC_AEB_TGU_AEBP_Obj_UpdateFlag 0 "OBJECT_EXISTED_IN_PREVIOUS_CYCLE" 1 "NEW_OBJECT_IN_THE_CYCLE" ;
VAL_ 361 RFC_AEB_TGU_AEBP_Obj_Type 3 "Pedestrian" 2 "2 wheeler" 1 "4 wheeler and plus" 0 "Unknown" ;
VAL_ 361 RFC_AEB_TGU_AEBP_Obj_EDynProp 0 "MOVING_DYNAMICPROPERTY" 1 "STATIONARY_DYNAMICPROPERTY" 2 "ONCOMING_DYNAMICPROPERTY" 3 "CROSSING_LEFT_TO_RIGHT_DYNAMICPR" 4 "CROSSING_RIGHT_TO_LEFT_DYNAMICPR" 5 "UNKNOWN_DYNAMICPROPERTY" 6 "STOPPED_DYNAMICPROPERTY" 7 "RESERVED" ;
VAL_ 361 RFC_AEB_TGU_AEBP_Obj_UiLifeCyc 126 "MAX_CYCLE_OBJ_LIFECYCLE" 127 "INVALID_OBJ_LIFECYCLE" ;
VAL_ 370 RFC_AEB_TGU_Turn_Obj0_ValidFlag 0 "valid" 1 "invalid" ;
VAL_ 370 RFC_AEB_TGU_Turn_Obj0_UpdateFlag 0 "OBJECT_EXISTED_IN_PREVIOUS_CYCLE" 1 "NEW_OBJECT_IN_THE_CYCLE" ;
VAL_ 370 RFC_AEB_TGU_Turn_Obj0_Type 3 "Pedestrian" 2 "2 wheeler" 1 "4 wheeler and plus" 0 "Unknown" ;
VAL_ 370 RFC_AEB_TGU_Turn_Obj0_EDynProp 0 "MOVING_DYNAMICPROPERTY" 1 "STATIONARY_DYNAMICPROPERTY" 2 "ONCOMING_DYNAMICPROPERTY" 3 "CROSSING_LEFT_TO_RIGHT_DYNAMICPR" 4 "CROSSING_RIGHT_TO_LEFT_DYNAMICPR" 5 "UNKNOWN_DYNAMICPROPERTY" 6 "STOPPED_DYNAMICPROPERTY" 7 "RESERVED" ;
VAL_ 370 RFC_AEB_TGU_Turn_Obj0_UiLifeCyc 126 "MAX_CYCLE_OBJ_LIFECYCLE" 127 "INVALID_OBJ_LIFECYCLE" ;
VAL_ 370 RFC_AEB_TGU_Turn_Obj1_ValidFlag 0 "valid" 1 "invalid" ;
VAL_ 370 RFC_AEB_TGU_Turn_Obj1_UpdateFlag 0 "OBJECT_EXISTED_IN_PREVIOUS_CYCLE" 1 "NEW_OBJECT_IN_THE_CYCLE" ;
VAL_ 370 RFC_AEB_TGU_Turn_Obj1_Type 3 "Pedestrian" 2 "2 wheeler" 1 "4 wheeler and plus" 0 "Unknown" ;
VAL_ 370 RFC_AEB_TGU_Turn_Obj1_EDynProp 0 "MOVING_DYNAMICPROPERTY" 1 "STATIONARY_DYNAMICPROPERTY" 2 "ONCOMING_DYNAMICPROPERTY" 3 "CROSSING_LEFT_TO_RIGHT_DYNAMICPR" 4 "CROSSING_RIGHT_TO_LEFT_DYNAMICPR" 5 "UNKNOWN_DYNAMICPROPERTY" 6 "STOPPED_DYNAMICPROPERTY" 7 "RESERVED" ;
VAL_ 370 RFC_AEB_TGU_Turn_Obj1_UiLifeCyc 126 "MAX_CYCLE_OBJ_LIFECYCLE" 127 "INVALID_OBJ_LIFECYCLE" ;
VAL_ 369 RFC_AEB_TGU_VRU_Obj0_ValidFlag 0 "valid" 1 "invalid" ;
VAL_ 369 RFC_AEB_TGU_VRU_Obj0_UpdateFlag 0 "OBJECT_EXISTED_IN_PREVIOUS_CYCLE" 1 "NEW_OBJECT_IN_THE_CYCLE" ;
VAL_ 369 RFC_AEB_TGU_VRU_Obj0_Type 3 "Pedestrian" 2 "2 wheeler" 1 "4 wheeler and plus" 0 "Unknown" ;
VAL_ 369 RFC_AEB_TGU_VRU_Obj0_EDynProp 0 "MOVING_DYNAMICPROPERTY" 1 "STATIONARY_DYNAMICPROPERTY" 2 "ONCOMING_DYNAMICPROPERTY" 3 "CROSSING_LEFT_TO_RIGHT_DYNAMICPR" 4 "CROSSING_RIGHT_TO_LEFT_DYNAMICPR" 5 "UNKNOWN_DYNAMICPROPERTY" 6 "STOPPED_DYNAMICPROPERTY" 7 "RESERVED" ;
VAL_ 369 RFC_AEB_TGU_VRU_Obj0_UiLifeCyc 126 "MAX_CYCLE_OBJ_LIFECYCLE" 127 "INVALID_OBJ_LIFECYCLE" ;
VAL_ 369 RFC_AEB_TGU_VRU_Obj1_ValidFlag 0 "valid" 1 "invalid" ;
VAL_ 369 RFC_AEB_TGU_VRU_Obj1_UpdateFlag 0 "OBJECT_EXISTED_IN_PREVIOUS_CYCLE" 1 "NEW_OBJECT_IN_THE_CYCLE" ;
VAL_ 369 RFC_AEB_TGU_VRU_Obj1_Type 3 "Pedestrian" 2 "2 wheeler" 1 "4 wheeler and plus" 0 "Unknown" ;
VAL_ 369 RFC_AEB_TGU_VRU_Obj1_EDynProp 0 "MOVING_DYNAMICPROPERTY" 1 "STATIONARY_DYNAMICPROPERTY" 2 "ONCOMING_DYNAMICPROPERTY" 3 "CROSSING_LEFT_TO_RIGHT_DYNAMICPR" 4 "CROSSING_RIGHT_TO_LEFT_DYNAMICPR" 5 "UNKNOWN_DYNAMICPROPERTY" 6 "STOPPED_DYNAMICPROPERTY" 7 "RESERVED" ;
VAL_ 369 RFC_AEB_TGU_VRU_Obj1_UiLifeCyc 126 "MAX_CYCLE_OBJ_LIFECYCLE" 127 "INVALID_OBJ_LIFECYCLE" ;
VAL_ 368 RFC_AEB_TGU_C2C_Obj0_ValidFlag 0 "valid" 1 "invalid" ;
VAL_ 368 RFC_AEB_TGU_C2C_Obj0_UpdateFlag 0 "OBJECT_EXISTED_IN_PREVIOUS_CYCLE" 1 "NEW_OBJECT_IN_THE_CYCLE" ;
VAL_ 368 RFC_AEB_TGU_C2C_Obj0_Type 3 "Pedestrian" 2 "2 wheeler" 1 "4 wheeler and plus" 0 "Unknown" ;
VAL_ 368 RFC_AEB_TGU_C2C_Obj0_EDynProp 0 "MOVING_DYNAMICPROPERTY" 1 "STATIONARY_DYNAMICPROPERTY" 2 "ONCOMING_DYNAMICPROPERTY" 3 "CROSSING_LEFT_TO_RIGHT_DYNAMICPR" 4 "CROSSING_RIGHT_TO_LEFT_DYNAMICPR" 5 "UNKNOWN_DYNAMICPROPERTY" 6 "STOPPED_DYNAMICPROPERTY" 7 "RESERVED" ;
VAL_ 368 RFC_AEB_TGU_C2C_Obj0_UiLifeCyc 126 "MAX_CYCLE_OBJ_LIFECYCLE" 127 "INVALID_OBJ_LIFECYCLE" ;
VAL_ 368 RFC_AEB_TGU_C2C_Obj1_ValidFlag 0 "valid" 1 "invalid" ;
VAL_ 368 RFC_AEB_TGU_C2C_Obj1_UpdateFlag 0 "OBJECT_EXISTED_IN_PREVIOUS_CYCLE" 1 "NEW_OBJECT_IN_THE_CYCLE" ;
VAL_ 368 RFC_AEB_TGU_C2C_Obj1_Type 3 "Pedestrian" 2 "2 wheeler" 1 "4 wheeler and plus" 0 "Unknown" ;
VAL_ 368 RFC_AEB_TGU_C2C_Obj1_EDynProp 0 "MOVING_DYNAMICPROPERTY" 1 "STATIONARY_DYNAMICPROPERTY" 2 "ONCOMING_DYNAMICPROPERTY" 3 "CROSSING_LEFT_TO_RIGHT_DYNAMICPR" 4 "CROSSING_RIGHT_TO_LEFT_DYNAMICPR" 5 "UNKNOWN_DYNAMICPROPERTY" 6 "STOPPED_DYNAMICPROPERTY" 7 "RESERVED" ;
VAL_ 368 RFC_AEB_TGU_C2C_Obj1_UiLifeCyc 126 "MAX_CYCLE_OBJ_LIFECYCLE" 127 "INVALID_OBJ_LIFECYCLE" ;
VAL_ 151 VFC_dcLeCollisionProbLow 1 "True" 0 "False" ;
VAL_ 151 VFC_CFLeCollisionProbLow 1 "True" 0 "False" ;
VAL_ 151 VFC_CRLeCollisionProbLow 1 "True" 0 "False" ;
VAL_ 151 VFC_dcRiCollisionProbLow 1 "True" 0 "False" ;
VAL_ 151 VFC_HWA_ILCLeftSt 0 "ADAS_ILCSt_Off" 2 "ADAS_ILCSt_Enabled" 3 "ADAS_ILCSt_Wait" 4 "ADAS_ILCSt_LaneChanging" 5 "ADAS_ILCSt_LandChanged" 6 "ADAS_ILCSt_Abort" 7 "ADAS_ILCSt_Retreat" 8 "ADAS_ILCSt_Failure" ;
VAL_ 151 VFC_HWA_ILCRightSt 0 "ADAS_ILCSt_Off" 2 "ADAS_ILCSt_Enabled" 3 "ADAS_ILCSt_Wait" 4 "ADAS_ILCSt_LaneChanging" 5 "ADAS_ILCSt_LandChanged" 6 "ADAS_ILCSt_Abort" 7 "ADAS_ILCSt_Retreat" 8 "ADAS_ILCSt_Failure" ;
VAL_ 151 VFC_CFRiCollisionProbLow 1 "True" 0 "False" ;
VAL_ 151 VFC_CRRiCollisionProbLow 1 "True" 0 "False" ;
VAL_ 151 VFC_isOriLaneWidthInDefRange 1 "True" 0 "False" ;
VAL_ 151 VFC_isLeLaneTypeValidForALC 1 "True" 0 "False" ;
VAL_ 151 VFC_isNeiLeLaneWidthInRange 1 "True" 0 "False" ;
VAL_ 151 VFC_isDetecDisActCondForNeiLe 1 "True" 0 "False" ;
VAL_ 151 VFC_isExiProbActCondNeiLe 1 "True" 0 "False" ;
VAL_ 151 VFC_isRiLaneTypeValidForALC 1 "True" 0 "False" ;
VAL_ 151 VFC_isNeiRiLaneWidthInRange 1 "True" 0 "False" ;
VAL_ 151 VFC_isDetecDisActCondForNeiRi 1 "True" 0 "False" ;
VAL_ 151 VFC_isExiProbActCondNeiRi 1 "True" 0 "False" ;
VAL_ 151 VFC_isLdwInReactZoneLe 1 "True" 0 "False" ;
VAL_ 151 VFC_isLdwInReactZoneRi 1 "True" 0 "False" ;
VAL_ 151 VFC_isRdpInReactZoneLe 1 "True" 0 "False" ;
VAL_ 151 VFC_isRdpInReactZoneRi 1 "True" 0 "False" ;
VAL_ 151 VFC_isELKslInReactZoneLe 1 "True" 0 "False" ;
VAL_ 151 VFC_isELKslInReactZoneRi 1 "True" 0 "False" ;
VAL_ 151 VFC_isELKoInReactZoneLe 1 "True" 0 "False" ;
VAL_ 151 VFC_isELKoInReactZoneRi 1 "True" 0 "False" ;
VAL_ 151 VFC_isELKotInReactZoneLe 1 "True" 0 "False" ;
VAL_ 151 VFC_isELKotInReactZoneRi 1 "True" 0 "False" ;
VAL_ 151 VFC_isELKreInReactZoneLe 1 "True" 0 "False" ;
VAL_ 151 VFC_isELKreInReactZoneRi 1 "True" 0 "False" ;
VAL_ 87 RFC_RFL_ModState 0 "Normal" 1 "TimeSyncFail_ModFail" 2 "TimeSyncCorrect_ModFail" 3 "Reserved" ;
VAL_ 87 RFC_RFR_ModState 0 "Normal" 1 "TimeSyncFail_ModFail" 2 "TimeSyncCorrect_ModFail" 3 "Reserved" ;
VAL_ 87 RFC_RRL_ModState 0 "Normal" 1 "TimeSyncFail_ModFail" 2 "TimeSyncCorrect_ModFail" 3 "Reserved" ;
VAL_ 87 RFC_RRR_ModState 0 "Normal" 1 "TimeSyncFail_ModFail" 2 "TimeSyncCorrect_ModFail" 3 "Reserved" ;
VAL_ 75 RFC_SCF_MFS_Set 1 "ON" 0 "OFF" ;
VAL_ 75 RFC_AEBSts 0 "not active" 1 "active" ;
VAL_ 75 RFC_ACCSts 0 "Off" 1 "Passive" 2 "Standby" 3 "Active Control" 4 "Brake only" 5 "Override" 6 "Stand Active" 7 "Stand Wait" 8 "Temprary Falure" 9 "Permanent Falure" ;
VAL_ 75 RFC_ESSSts 0 "Off" 1 "Passive" 2 "Active" 3 "Fault" 4 "Reserved" 5 "Reserved" 6 "Reserved" 7 "Reserved" ;
VAL_ 75 RFC_ToqReqActive_ESS 0 "not active" 1 "active" ;
VAL_ 75 RFC_AngReqActive_ESS 0 "not active" 1 "active" ;
VAL_ 75 RFC_Stat_Error 0 "No Error" 1 "Error" ;
VAL_ 75 RFC_Stat_ACCSwitchButton 0 "Not_Pressed" 1 "Pressed" 2 "Dummy" 3 "Error" ;
VAL_ 137 VFC_MotorTorqueMaxLimitRequest 2047 "Reserved" ;
VAL_ 137 VFC_MotorTorqueMinLimitRequest 2047 "Reserved" ;
VAL_ 137 VFC_LatAngReqActive 0 "not active" 1 "active" ;
VAL_ 137 VFC_LatAngReq 14410 "Reseverd" ;
VAL_ 145 Selflearning_status 3 "reserved" 2 "completed" 1 "learning" 0 "init" ;
VAL_ 145 VFC_DriverWindowControl 102 "Reserved" 1 "0%~100%" 0 "no request" ;
VAL_ 145 VFC_LLaneDistanceFusion 121 "reserved" 0 "-1-5" ;
VAL_ 145 VFC_SunroofControl 205 "Reserved" 203 "Sunshade0%~100%" 1 "SunRoof0%~100%" 255 "Reserved" 254 "Initialize" 204 "stop" 102 "tilt" 0 "inactive" ;
VAL_ 145 VFC_RLaneDistanceFusion 1 "Reserved" 0 "-1-5" ;
VAL_ 146 VFC_EmergencyLightingRequest 3 "OFF" 2 "Level2" 1 "Level1" 0 "no request" ;
VAL_ 146 VFC_ELKActiveSide 3 "RESERVED" 2 "SIDE_RI" 1 "SIDE_LE" 0 "SIDE_UNDEF" ;
VAL_ 146 VFC_LASModeSelectionStatus 0 "Reserved" 1 "LDW" 2 "LKA" 3 "LCS" 4 "Reserved" 7 "OFF" ;
VAL_ 146 VFC_LatTakeoverReq 0 "no request" 1 "level 1 request" 2 "level 2 request" 3 "reserved" ;
VAL_ 146 VFC_HandsOnReq 7 "reserved" 6 "reserved" 0 "no request" 1 "level 1 request" 2 "level 2 request" 3 "level 3 request" 4 "level 4 request" 5 "reserved" ;
VAL_ 146 VFC_RLaneMarkerType 0 "Dashed" 1 "solid" 2 "road edge" 3 "double lane mark" 4 "Botts' dots" 5 "other" 6 "fence" 7 "no display" ;
VAL_ 146 VFC_LaneChangeStatus 0 "no lane change " 1 "lane changing" 2 "end lane change" 3 "unknow" ;
VAL_ 146 VFC_RoadCurvatureFar 1 "Reserved" 0 "-0.03-0.03" ;
VAL_ 146 VFC_RRLaneDistance 61 "reserved" 0 "0-12" ;
VAL_ 146 VFC_IACCHWAMode 0 "off" 1 "standby" 2 "passive" 3 "active" 4 "suspend" 5 "prohibition" 6 "reserved" 7 "failure" ;
VAL_ 146 VFC_LASWarningModeSelectionSts 0 "Reserved" 1 "sound" 2 "vibration" 3 "sound and vibration" 4 "Reserved" ;
VAL_ 146 VFC_DriverHandsOffStatus 0 "hands off" 1 "hands on Level1" 2 "hands on Level2" 3 "unkown" ;
VAL_ 146 VFC_IACCHWATextInfoForDriver 24 "Reserved" 13 "prohibition request" 12 "system error" 11 "caturion about driving safty" 10 "driver overrides steering" 28 "reserved" 15 "Hands on plz" 23 "unable to active in Bad weather" 22 "other system error" 0 "no display" 1 "IACC cancel" 2 "IACC deativate" 3 "IACC unintended exit" 4 "unable to activate IACC" 5 "lane condition not avaliable" 6 "ADR/DVR Status not Match" 7 "longitudinal control unavaliable" 8 "IACC not available by EPS" 9 "exceed speed limit" 14 "turn light switch on" 16 "Please turn on IACC in incall" 17 "unable to active in curve" 18 "unable to active for not in lane" 19 "Longitude Exit" 20 "TOR with safety stoping" 21 "TOR with safety stop completed" 27 "Driver Drowsy or Distracted" ;
VAL_ 146 VFC_LDWShakeLevStatus 0 "reserved" 1 "low" 2 "normal" 3 "high" ;
VAL_ 146 VFC_IACCHWAEnable 0 "OFF" 1 "on" ;
VAL_ 146 VFC_HostLaneLeftStatus 0 "no display" 1 "Tracking" 2 "Intervention" 3 "Warning" 4 "Centering" 5 "Crossing" 6 "UDLC Request Active" 7 "reserved" 8 "UDLC  not  Active by obj" 9 "reserved" ;
VAL_ 146 VFC_ELKInterventionMode 0 "off" 1 "Road edge" 2 "Overtaking" 3 "Oncoming" 4 "Solid Line" ;
VAL_ 146 VFC_ELKMode 0 "off" 1 "passive" 2 "active" 3 "fault" 4 "standby" 5 "reserved" 6 "reserved" 7 "reserved" ;
VAL_ 146 VFC_HostLaneRightStatus 0 "no display" 1 "Tracking" 2 "Intervention" 3 "Warning" 4 "Centering" 5 "Crossing" 6 "UDLC Request Active" 7 "reserved" 8 "UDLC  not  Active by obj" 9 "reserved" ;
VAL_ 146 VFC_TargetBasedLateralControl 0 "no lateral control" 1 "around Based" 2 "lane based" 3 "target based" ;
VAL_ 146 VFC_HandsoffFuncStatus 0 "off" 1 "passive" 2 "standby" 3 "wariming" 4 "total hansoff mode" 5 "handsoff with limit" 6 "reserved" 7 "faulure" ;
VAL_ 146 VFC_HandsoffFuncTextinfo 0 "no display" 1 "total handsoff mode" 2 "out of handsoff mode by out ODD" 3 "out of handsoff by Drowsiness" 4 "out of handsoff by Distraction" 5 "out of handsoffmode-IMS Unavail" 6 "out of handsoffmode-NAV Unavail" 7 "our of handsoffmode-NoCurvature" 8 "out of handsoffmode-IACC Suspend" 9 "Reserved" ;
VAL_ 146 VFC_LLaneMarkerType 0 "Dashed" 1 "solid" 2 "road edge" 3 "double lane mark" 4 "Botts' dots" 5 "other" 6 "fence" 7 "no display" ;
VAL_ 146 VFC_ELKEnableStatus 0 "off" 1 "on" ;
VAL_ 146 VFC_LLLaneDistance 1 "Reserved" 0 "0-12" ;
VAL_ 146 VFC_RoadCurvature 1 "Reserved" 0 "-0.03-0.03" ;
VAL_ 146 VFC_LLLaneDetection 0 "not detected" 1 "detected" 2 "road edge" 3 "fence" ;
VAL_ 146 VFC_Voiceinfo 15 "Reserved" 0 "no voice" 1 "latentWarning voive" 2 "FCWAEB voice" 3 "ACC object detect voice" 4 "ACC object disappeared voice" 5 "ACC/IACC takeover request voice" 6 "Left dangerous warning voice" 7 "Right dangerous warning  voice" 8 "reserved" 9 "IACC Active voice" 10 "IACC exit voice" 11 "reserved" 12 "reserved" 13 "cruise unintended exit" 14 "TrafficWarning" ;
VAL_ 146 VFC_RRLaneDetection 0 "not detected" 1 "detected" 2 "road edge" 3 "fence" ;
VAL_ 146 VFC_RoadCurvatureNear 1 "Reserved" 0 "-0.03-0.03" ;
VAL_ 147 VFC_LaneEquationStatus 3 "reserved" 2 "right lane" 1 "left lane" 0 "no display" ;
VAL_ 148 VFC_LDWStatus 0 "off" 1 "Standby" 2 "Active" 3 "Failure" ;
VAL_ 148 VFC_LDWVibrationWarningReq 0 "No Warming" 1 "Left Warming" 2 "Right Warming" 3 "Reserved" ;
VAL_ 148 VFC_LKAStatus 0 "off" 1 "Standby" 2 "Active" 3 "Failure" ;
VAL_ 149 VFC_LDWSt 7 "Reserved" 6 "Reserved" 5 "Perm Failure" 4 "Temp Failure" 3 "Active" 2 "Standby" 1 "Passive" 0 "Off" ;
VAL_ 149 VFC_RDPSt 7 "Reserved" 6 "Reserved" 5 "Perm Failure" 4 "Temp Failure" 3 "Active" 2 "Standby" 1 "Passive" 0 "Off" ;
VAL_ 149 VFC_ELKSt_re 7 "Reserved" 6 "Reserved" 5 "Perm Failure" 4 "Temp Failure" 3 "Active" 2 "Standby" 1 "Passive" 0 "Off" ;
VAL_ 149 VFC_ELKSt_ot 7 "Reserved" 6 "Reserved" 5 "Perm Failure" 4 "Temp Failure" 3 "Active" 2 "Standby" 1 "Passive" 0 "Off" ;
VAL_ 149 VFC_ELKSt_oc 7 "Reserved" 6 "Reserved" 5 "Perm Failure" 4 "Temp Failure" 3 "Active" 2 "Standby" 1 "Passive" 0 "Off" ;
VAL_ 149 VFC_ELKSt_sl 7 "Reserved" 6 "Reserved" 5 "Perm Failure" 4 "Temp Failure" 3 "Active" 2 "Standby" 1 "Passive" 0 "Off" ;
VAL_ 149 VFC_LKSSt 7 "Reserved" 6 "Reserved" 5 "Perm Failure" 4 "Temp Failure" 3 "Active" 2 "Standby" 1 "Passive" 0 "Off" ;
VAL_ 149 VFC_vehicleReachTargetLane 0 "False" 1 "True" ;
VAL_ 149 VFC_isLaneChangeFinished 0 "False" 1 "True" ;
VAL_ 149 VFC_inLaneChangeManoeuvre 0 "False" 1 "True" ;
VAL_ 149 VFC_isAlcAttentiveHandsOnSt 0 "False" 1 "True" ;
VAL_ 149 VFC_laneChangeDirectionChanged 0 "False" 1 "True" ;
VAL_ 149 VFC_ILCASysSts 7 "EALC_SysSt_FAILURE" 6 "EALC_SysSt_RETREAT" 5 "EALC_SysSt_ABORT" 4 "EALC_SysSt_FINISHED" 3 "EALC_SysSt_ACTIVE" 2 "EALC_SysSt_REQUEST" 1 "EALC_SysSt_ENABLED" 0 "EALC_SysSt_OFF" ;
VAL_ 149 VFC_DirectionIndDisableReq 2 "EALC_TURN_LAMP_OFF_RIGHT" 1 "EALC_TURN_LAMP_OFF_LEFT" 0 "EALC_TURN_LAMP_OFF_NO_REQ" ;
VAL_ 149 VFC_OpticalWarningForALC 7 "DRIVER_HANDSOFF" 6 "FAILURE_DURING_LCM" 5 "LCP_SUPPRESSED_NOT_BY_DRIVER" 4 "LCP_SUPPRESSED_BY_DRIVER" 3 "LCP" 2 "FAILURE" 1 "STANDBY" 0 "NO" ;
VAL_ 149 VFC_HapticWarningForALC 2 "FAILURE_DURING_LCM" 1 "LCP_SUPPRESSED_NOT_BY_DRIVER" 0 "NO" ;
VAL_ 930 VFC_TSR_NEWFC 1 "True" 0 "False" ;
VAL_ 930 VFC_NavCountryCodeInfo 127 "Reserve" 126 "Reserve" 125 "Reserve" 124 "Reserve" 123 "Reserve" 122 "Reserve" 121 "Reserve" 120 "Reserve" 119 "Reserve" 118 "Reserve" 117 "Reserve" 116 "Reserve" 115 "Reserve" 114 "Reserve" 113 "Reserve" 112 "Reserve" 111 "Reserve" 110 "Reserve" 109 "Reserve" 108 "Reserve" 107 "Reserve" 106 "Reserve" 105 "Reserve" 104 "Reserve" 103 "Reserve" 102 "Reserve" 101 "Reserve" 100 "Reserve" 99 "Reserve" 98 "Reserve" 97 "Reserve" 96 "Reserve" 95 "Reserve" 94 "Reserve" 93 "Reserve" 92 "Reserve" 91 "Reserve" 90 "Reserve" 89 "Reserve" 88 "Reserve" 87 "Reserve" 86 "Reserve" 85 "Reserve" 84 "Reserve" 83 "Reserve" 82 "Reserve" 81 "Reserve" 80 "Reserve" 79 "Reserve" 78 "Reserve" 77 "Reserve" 76 "Reserve" 75 "Reserve" 74 "Reserve" 73 "Reserve" 72 "Reserve" 71 "Reserve" 70 "Reserve" 69 "Reserve" 68 "Reserve" 67 "Reserve" 66 "Reserve" 65 "Reserve" 64 "Reserve" 63 "Reserve" 62 "Reserve" 61 "Reserve" 60 "Reserve" 59 "Reserve" 58 "Reserve" 57 "Reserve" 56 "Reserve" 55 "Reserve" 54 "Reserve" 53 "Reserve" 52 "Reserve" 51 "Reserve" 50 "Reserve" 49 "Reserve" 48 "Reserve" 47 "Reserve" 46 "Reserve" 45 "CHN 中国" 44 "MYS 马来西亚" 43 "NZL 新西兰" 42 "AUS 澳大利亚" 41 "KOS 科索沃" 40 "ALB 阿尔巴尼亚" 39 "MNE 黑山" 38 "MKD 北马其顿" 37 "BIH 波黑" 36 "SRB 塞尔维亚" 35 "ISR 以色列" 34 "TUR 土耳其" 33 "CHE 瑞士" 32 "NOR 挪威" 31 " AUT 奥地利" 30 "SWE 瑞典" 29 "SVN 斯洛文尼亚" 28 "SVK 斯洛伐克" 27 "ROU 罗马尼亚" 26 "PRT 葡萄牙" 25 "POL 波兰" 24 "NLD 荷兰" 23 "MLT 马耳他" 22 "LVA 拉脱维亚" 21 "LUX 卢森堡" 20 "LTU 立陶宛" 19 "ITA 意大利" 18 "IRL 爱尔兰" 17 "IMN 马恩岛" 16 "HUN 匈牙利" 15 "HRV 克罗地亚" 14 "GIB 直布罗陀" 13 "GRC 希腊" 12 "GBR 英国" 11 "FRO 法罗群岛" 10 "FRA 法国" 9 "FIN 芬兰" 8 "EST 爱沙尼亚" 7 "ESP 西班牙" 6 "DNK 丹麦" 5 "DEU 德国" 4 "CZE 捷克共和国" 3 "CYP 塞浦路斯" 2 "BGR 保加利亚" 1 "BEL 比利时" 0 "None" ;
VAL_ 930 LAS_OverspeedWarningOffset 31 "Invalid" 21 "Reserved" 0 "Reserved" ;
VAL_ 930 VFC_ADAS_ModSts_SLA 0 "Unknown" 1 "Off" 2 "Fusion mode" 3 "Vision mode" 4 "Navigation only mode" 5 "Defect" 6 "Reserved" 7 "Reserved" ;
VAL_ 930 VFC_ADAS_SpdLim_SLA 255 "Reserve" 37 "SPL 180" 36 "SPL 175" 35 "SPL 170" 34 "SPL 165" 33 "SPL 160" 32 "SPL 155" 31 "SPL 150" 30 "SPL 145" 0 "No Display" 1 "SPL Cancelled" 2 "SPL 5" 3 "SPL 10" 4 "SPL 15" 5 "SPL 20" 6 "SPL 25" 7 "SPL 30" 8 "SPL 35" 9 "SPL 40" 10 "SPL 45" 11 "SPL 50" 12 "SPL 55" 13 "SPL 60" 14 "SPL 65" 15 "SPL 70" 16 "SPL 75" 17 "SPL 80" 18 "SPL 85" 19 "SPL 90" 20 "SPL 95" 21 "SPL 100" 22 "SPL 105" 23 "SPL 110" 24 "SPL 115" 25 "SPL 120" 26 "SPL 125" 27 "SPL 130" 28 "SPL 135" 29 "SPL 140" ;
VAL_ 930 VFC_ADAS_SpdLimUnit_SLA 0 "Unknown" 1 "KPH" 2 "MPH" 3 "Reserved" ;
VAL_ 929 VFC_TLAObjectColour_LeftLane 0 "NONE/UNKNOWN(e.g. missing input)" 1 "RED" 2 "YELLOW" 3 "GREEN" ;
VAL_ 929 VFC_TLAObjectColour_RightLane 0 "NONE/UNKNOWN(e.g. missing input)" 1 "RED" 2 "YELLOW" 3 "GREEN" ;
VAL_ 929 VFC_TLAObjectColour_HostLane 0 "NONE/UNKNOWN(e.g. missing input)" 1 "RED" 2 "YELLOW" 3 "GREEN" ;
VAL_ 929 VFC_TLF_SuggestedDriveAction 0 "NONE/UNKNOWN" 1 "Can pass" 2 "Cannot pass" ;
VAL_ 273 RFC_TIPLBoundary_Type 0 "Without line and road edge" 1 "With line" 2 "With road edge" 3 "With line and road edge" ;
VAL_ 273 RFC_TIPLBoundary_Valid 0 "Invalid" 1 "Valid" ;
VAL_ 288 RFC_OnComingObj0_ValidFlag 0 "valid" 1 "invalid" ;
VAL_ 288 RFC_OnComingObj0_UpdateFlag 0 "OBJECT_EXISTED_IN_PREVIOUS_CYCLE" 1 "NEW_OBJECT_IN_THE_CYCLE" ;
VAL_ 288 RFC_OnComingObj0_Type 3 "Pedestrian" 2 "2 wheeler" 1 "4 wheeler and plus" 0 "Unknown" ;
VAL_ 288 RFC_OnComingObj0_EDynProp 0 "MOVING_DYNAMICPROPERTY" 1 "STATIONARY_DYNAMICPROPERTY" 2 "ONCOMING_DYNAMICPROPERTY" 3 "CROSSING_LEFT_TO_RIGHT_DYNAMICPR" 4 "CROSSING_RIGHT_TO_LEFT_DYNAMICPR" 5 "UNKNOWN_DYNAMICPROPERTY" 6 "STOPPED_DYNAMICPROPERTY" 7 "RESERVED" ;
VAL_ 288 RFC_OnComingObj0_UiLifeCycles 126 "MAX_CYCLE_OBJ_LIFECYCLE" 127 "INVALID_OBJ_LIFECYCLE" ;
VAL_ 289 RFC_OnComingObj1_ValidFlag 0 "valid" 1 "invalid" ;
VAL_ 289 RFC_OnComingObj1_UpdateFlag 0 "OBJECT_EXISTED_IN_PREVIOUS_CYCLE" 1 "NEW_OBJECT_IN_THE_CYCLE" ;
VAL_ 289 RFC_OnComingObj1_Type 3 "Pedestrian" 2 "2 wheeler" 1 "4 wheeler and plus" 0 "Unknown" ;
VAL_ 289 RFC_OnComingObj1_EDynProp 0 "MOVING_DYNAMICPROPERTY" 1 "STATIONARY_DYNAMICPROPERTY" 2 "ONCOMING_DYNAMICPROPERTY" 3 "CROSSING_LEFT_TO_RIGHT_DYNAMICPR" 4 "CROSSING_RIGHT_TO_LEFT_DYNAMICPR" 5 "UNKNOWN_DYNAMICPROPERTY" 6 "STOPPED_DYNAMICPROPERTY" 7 "RESERVED" ;
VAL_ 289 RFC_OnComingObj1_UiLifeCycles 126 "MAX_CYCLE_OBJ_LIFECYCLE" 127 "INVALID_OBJ_LIFECYCLE" ;
VAL_ 292 RFC_OnGoingObj0_ValidFlag 0 "valid" 1 "invalid" ;
VAL_ 292 RFC_OnGoingObj0_UpdateFlag 0 "OBJECT_EXISTED_IN_PREVIOUS_CYCLE" 1 "NEW_OBJECT_IN_THE_CYCLE" ;
VAL_ 292 RFC_OnGoingObj0_Type 3 "Pedestrian" 2 "2 wheeler" 1 "4 wheeler and plus" 0 "Unknown" ;
VAL_ 292 RFC_OnGoingObj0_EDynProp 0 "MOVING_DYNAMICPROPERTY" 1 "STATIONARY_DYNAMICPROPERTY" 2 "ONCOMING_DYNAMICPROPERTY" 3 "CROSSING_LEFT_TO_RIGHT_DYNAMICPR" 4 "CROSSING_RIGHT_TO_LEFT_DYNAMICPR" 5 "UNKNOWN_DYNAMICPROPERTY" 6 "STOPPED_DYNAMICPROPERTY" 7 "RESERVED" ;
VAL_ 292 RFC_OnGoingObj0_UiLifeCycles 126 "MAX_CYCLE_OBJ_LIFECYCLE" 127 "INVALID_OBJ_LIFECYCLE" ;
VAL_ 293 RFC_OnGoingObj1_ValidFlag 0 "valid" 1 "invalid" ;
VAL_ 293 RFC_OnGoingObj1_UpdateFlag 0 "OBJECT_EXISTED_IN_PREVIOUS_CYCLE" 1 "NEW_OBJECT_IN_THE_CYCLE" ;
VAL_ 293 RFC_OnGoingObj1_Type 3 "Pedestrian" 2 "2 wheeler" 1 "4 wheeler and plus" 0 "Unknown" ;
VAL_ 293 RFC_OnGoingObj1_EDynProp 0 "MOVING_DYNAMICPROPERTY" 1 "STATIONARY_DYNAMICPROPERTY" 2 "ONCOMING_DYNAMICPROPERTY" 3 "CROSSING_LEFT_TO_RIGHT_DYNAMICPR" 4 "CROSSING_RIGHT_TO_LEFT_DYNAMICPR" 5 "UNKNOWN_DYNAMICPROPERTY" 6 "STOPPED_DYNAMICPROPERTY" 7 "RESERVED" ;
VAL_ 293 RFC_OnGoingObj1_UiLifeCycles 126 "MAX_CYCLE_OBJ_LIFECYCLE" 127 "INVALID_OBJ_LIFECYCLE" ;
VAL_ 80 VFC_GlobalHdr_SensorState 0 "Camera Operational" 1 "Camera Initialization" 2 "Camera Limited (reduced Mode)" 3 "Reserved" 4 "Camera Blocked" 5 "Camera Error" 6 "Camera Calibration" 7 "Camera Decalibrated" ;
VAL_ 80 VFC_GlobalHdr_CalibState 0 "Fully Calibrated" 1 "Not Calibrated" 2 "Yaw Not Calibrated" 3 "Pitch Not Calibrated" 4 "Roll Not Calibrated" 5 "Reserved5" 6 "Reserved6" 7 "Reserved7" ;
